VERSION ""

NS_ :

BS_:

BU_: PBWM MCPB MCPA IDCM EVCU2 ECM DMPI BPCM

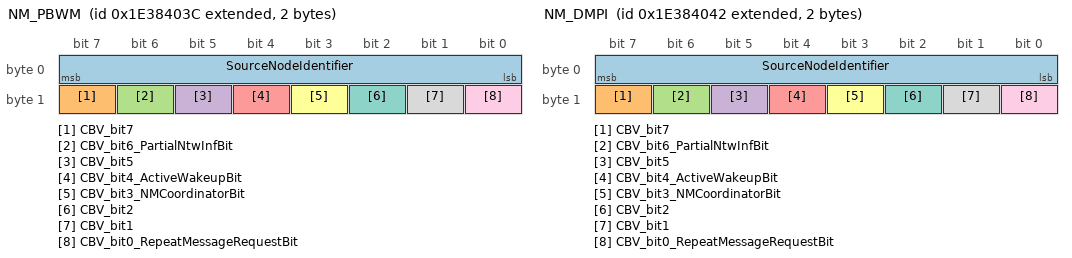
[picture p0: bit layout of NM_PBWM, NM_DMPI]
BO_ 2654486588 NM_PBWM: 2 PBWM
 SG_ SourceNodeIdentifier : 7|8@0+ (1,0) [0|255] "-"  DMPI,EVCU2,MCPB,MCPA,IDCM,BPCM,ECM
 SG_ CBV_bit7 : 15|1@0+ (1,0) [0|1] "" DMPI,EVCU2,MCPB,MCPA,IDCM,BPCM,ECM
 SG_ CBV_bit6_PartialNtwInfBit : 14|1@0+ (1,0) [0|1] "" DMPI,EVCU2,MCPB,MCPA,IDCM,BPCM,ECM
 SG_ CBV_bit5 : 13|1@0+ (1,0) [0|1] "" DMPI,EVCU2,MCPB,MCPA,IDCM,BPCM,ECM
 SG_ CBV_bit4_ActiveWakeupBit : 12|1@0+ (1,0) [0|1] "" DMPI,EVCU2,MCPB,MCPA,IDCM,BPCM,ECM
 SG_ CBV_bit3_NMCoordinatorBit : 11|1@0+ (1,0) [0|1] "" DMPI,EVCU2,MCPB,MCPA,IDCM,BPCM,ECM
 SG_ CBV_bit2 : 10|1@0+ (1,0) [0|1] "" DMPI,EVCU2,MCPB,MCPA,IDCM,BPCM,ECM
 SG_ CBV_bit1 : 9|1@0+ (1,0) [0|1] "" DMPI,EVCU2,MCPB,MCPA,IDCM,BPCM,ECM
 SG_ CBV_bit0_RepeatMessageRequestBit : 8|1@0+ (1,0) [0|1] "" DMPI,EVCU2,MCPB,MCPA,IDCM,BPCM,ECM

BO_ 2654486594 NM_DMPI: 2 DMPI
 SG_ SourceNodeIdentifier : 7|8@0+ (1,0) [0|255] "-"  PBWM,EVCU2,MCPB,MCPA,IDCM,BPCM,ECM
 SG_ CBV_bit7 : 15|1@0+ (1,0) [0|1] "" PBWM,EVCU2,MCPB,MCPA,IDCM,BPCM,ECM
 SG_ CBV_bit6_PartialNtwInfBit : 14|1@0+ (1,0) [0|1] "" PBWM,EVCU2,MCPB,MCPA,IDCM,BPCM,ECM
 SG_ CBV_bit5 : 13|1@0+ (1,0) [0|1] "" PBWM,EVCU2,MCPB,MCPA,IDCM,BPCM,ECM
 SG_ CBV_bit4_ActiveWakeupBit : 12|1@0+ (1,0) [0|1] "" PBWM,EVCU2,MCPB,MCPA,IDCM,BPCM,ECM
 SG_ CBV_bit3_NMCoordinatorBit : 11|1@0+ (1,0) [0|1] "" PBWM,EVCU2,MCPB,MCPA,IDCM,BPCM,ECM
 SG_ CBV_bit2 : 10|1@0+ (1,0) [0|1] "" PBWM,EVCU2,MCPB,MCPA,IDCM,BPCM,ECM
 SG_ CBV_bit1 : 9|1@0+ (1,0) [0|1] "" PBWM,EVCU2,MCPB,MCPA,IDCM,BPCM,ECM
 SG_ CBV_bit0_RepeatMessageRequestBit : 8|1@0+ (1,0) [0|1] "" PBWM,EVCU2,MCPB,MCPA,IDCM,BPCM,ECM

BO_ 214 INVTARGET1_2: 64 EVCU2
 SG_ UDCMin_Unlim_MCPB_2 : 129|16@0+ (0.01,0) [0|655.35] "V"  DMPI
 SG_ UDCMin_Unlim_MCPA_2 : 81|16@0+ (0.01,0) [0|655.35] "V"  DMPI
 SG_ UDCMax_Unlim_MCPB_2 : 113|16@0+ (0.01,0) [0|655.35] "V"  DMPI
 SG_ UDCMax_Unlim_MCPA_2 : 65|16@0+ (0.01,0) [0|655.35] "V"  DMPI
 SG_ TqGrdtLim_MCPB_2 : 144|16@0+ (0.1,0) [0|6553.5] "Nm/s"  DMPI
 SG_ TqGrdtLim_MCPA_2 : 97|16@0+ (0.1,0) [0|6553.5] "Nm/s"  DMPI
 SG_ TorqueCommand_MCPB_2 : 201|13@0+ (0.125,-512) [-512|511.875] "Nm"  DMPI
 SG_ TorqueCommand_MCPA_2 : 7|13@0+ (0.125,-512) [-512|511.875] "Nm"  DMPI
 SG_ TargetMotorRPM_MCPB_2 : 216|16@0+ (0.5,-16384) [-16384|16383.5] "rpm"  DMPI
 SG_ TargetMotorRPM_MCPA_2 : 22|16@0+ (0.5,-16384) [-16384|16383.5] "rpm"  DMPI
 SG_ SpdGrdtLim_MCPB_2 : 273|11@0+ (20,0) [0|40940] "rpm/s"  DMPI
 SG_ SpdGrdtLim_MCPA_2 : 160|11@0+ (20,0) [0|40940] "rpm/s"  DMPI
 SG_ Mtr_6SO_Request_MCPB_2 : 145|1@0+ (1,0) [0|1] "" DMPI
 SG_ Mtr_6SO_Request_MCPA_2 : 38|1@0+ (1,0) [0|1] "" DMPI
 SG_ ModeCommand_MCPB_2 : 220|4@0+ (1,0) [0|15] "" DMPI
 SG_ ModeCommand_MCPA_2 : 10|4@0+ (1,0) [0|15] "" DMPI
 SG_ MinTorque_Limit_MCPB_2 : 296|14@0+ (0.1,-1638.2) [-1638.2|0.1] "Nm"  DMPI
 SG_ MinTorque_Limit_MCPA_2 : 199|14@0+ (0.1,-1638.2) [-1638.2|0.1] "Nm"  DMPI
 SG_ MessageCounter_INVTARGET1_2 : 435|4@0+ (1,0) [0|15] "" DMPI
 SG_ MaxTorque_Limit_MCPB_2 : 294|14@0+ (0.1,0) [0|1638.3] "Nm"  DMPI
 SG_ MaxTorque_Limit_MCPA_2 : 181|14@0+ (0.1,0) [0|1638.3] "Nm"  DMPI
 SG_ MAC_INVTARGET1_2 : 471|48@0+ (1,0) [0|0] "" DMPI
 SG_ LgsDiagCldStrtCndMet_MCPB_2 : 267|1@0+ (1,0) [0|1] "" DMPI
 SG_ LgsDiagCldStrtCndFltPr_MCPB_2 : 268|1@0+ (1,0) [0|1] "" DMPI
 SG_ HVBatVlt_V_2 : 266|1@0+ (1,0) [0|1] "" DMPI
 SG_ EVCU_END_Request_Flag_2 : 256|1@0+ (1,0) [0|1] "" DMPI
 SG_ CRC_INVTARGET1_2 : 447|8@0+ (1,0) [0|255] "" DMPI
 SG_ Cntr_INVTARGET1_2 : 455|16@0+ (1,0) [0|65535] "" DMPI
 SG_ AEMD_MinOffset_MCPB_2 : 252|12@0+ (0.125,-511.875) [-511.875|0] "Nm"  DMPI
 SG_ AEMD_MinOffset_MCPA_2 : 41|12@0+ (0.125,-511.875) [-511.875|0] "Nm"  DMPI
 SG_ AEMD_MaxOffset_MCPB_2 : 232|12@0+ (0.125,0) [0|511.875] "Nm"  DMPI
 SG_ AEMD_Cutoff_FreqLow_MCPB_2 : 399|8@0+ (0.1,4.5) [4.5|30] "Hz"  DMPI
 SG_ AEMD_Cutoff_FreqLow_MCPA_2 : 391|8@0+ (0.1,4.5) [4.5|30] "Hz"  DMPI
 SG_ AEMD_Cutoff_FreqHigh_MCPB_2 : 383|8@0+ (0.1,0) [0|25.5] "Hz"  DMPI
 SG_ AEMD_Cutoff_FreqHigh_MCPA_2 : 375|8@0+ (0.1,0) [0|25.5] "Hz"  DMPI
 SG_ AEMD_Sclr_Gn_MCPB_2 : 354|11@0+ (0.01,0) [0|20.47] "rad/s/Nm"  DMPI
 SG_ AEMD_Sclr_Gn_MCPA_2 : 349|11@0+ (0.01,0) [0|20.47] "rad/s/Nm"  DMPI
 SG_ AEMD_Torque_BoostVolt_Margin : 37|12@0+ (0.125,0) [0|511.875] "Nm"  DMPI
 SG_ Boost_Torque_Margin_MCPB : 343|10@0+ (0.5,-256) [-256|255.5] "Nm"  DMPI
 SG_ Boost_Torque_Margin_MCPA : 321|10@0+ (0.5,-256) [-256|255.5] "Nm"  DMPI

BO_ 1065 MCPB_OBD_DTC: 32 MCPB
 SG_ MessageCounter_MCPB_OBD_DTC : 179|4@0+ (1,0) [0|15] ""  EVCU2
 SG_ MCPB_DTC_Stat2 : 26|3@0+ (1,0) [0|7] "" EVCU2
 SG_ MCPB_DTC_Stat1 : 18|3@0+ (1,0) [0|7] "" EVCU2
 SG_ MCPB_DTC_Idx2 : 31|5@0+ (1,0) [0|31] "" EVCU2
 SG_ MCPB_DTC_Idx1 : 23|5@0+ (1,0) [0|31] "" EVCU2
 SG_ MCPB_CalChar : 15|8@0+ (1,0) [0|255] "" EVCU2
 SG_ MCPB_Cal_ID_Idx : 7|6@0+ (1,0) [0|63] "" EVCU2
 SG_ CRC_MCPB_OBD_DTC : 191|8@0+ (1,0) [0|255] ""  EVCU2

BO_ 1057 MCPA_OBD_DTC: 32 MCPA
 SG_ MessageCounter_MCPA_OBD_DTC : 179|4@0+ (1,0) [0|15] ""  EVCU2
 SG_ MCPA_DTC_Stat2 : 26|3@0+ (1,0) [0|7] "" EVCU2
 SG_ MCPA_DTC_Stat1 : 18|3@0+ (1,0) [0|7] "" EVCU2
 SG_ MCPA_DTC_Idx2 : 31|5@0+ (1,0) [0|31] "" EVCU2
 SG_ MCPA_DTC_Idx1 : 23|5@0+ (1,0) [0|31] "" EVCU2
 SG_ MCPA_CalChar : 15|8@0+ (1,0) [0|255] "" EVCU2
 SG_ MCPA_Cal_ID_Idx : 7|6@0+ (1,0) [0|63] "" EVCU2
 SG_ CRC_MCPA_OBD_DTC : 191|8@0+ (1,0) [0|255] ""  EVCU2

BO_ 504 MCPB_STATUS: 32 MCPB
 SG_ MCPB_DerateReason_P : 7|4@0+ (1,0) [0|15] "-"  EVCU2
 SG_ MCPB_DC_Voltage_P : 1|10@0+ (1,0) [0|1022] "V"  EVCU2
 SG_ MCPB_DC_Volt_V_P : 3|1@0+ (1,0) [0|1] "" EVCU2
 SG_ MCPB_DC_Current_V_P : 2|1@0+ (1,0) [0|1] "" EVCU2
 SG_ MCPB_DC_Current_P : 38|15@0+ (0.1,-1638.4) [-1638.4|1638.3] "A"  EVCU2,BPCM
 SG_ MCPB_CoolantTemp_P : 18|11@0+ (0.1,-40) [-40|164.7] "°C"  EVCU2
 SG_ MC_MCPB_STATUS : 179|4@0+ (1,0) [0|15] "-"  EVCU2
 SG_ CRC_MCPB_STATUS : 191|8@0+ (1,0) [0|255] "-"  EVCU2
 SG_ MCPB_Inverter_Temp_P : 71|8@0+ (1,-40) [-40|215] "°C"  EVCU2
 SG_ MCPB_PIM_DC_Side_Busbar_Temp_P : 79|8@0+ (1,-40) [-40|215] "°C"  EVCU2
 SG_ MCPB_Rotor_Temperature_P : 55|8@0+ (1,-40) [-40|215] "ºC"  EVCU2
 SG_ MCPB_Service_Lamp_Request_P : 19|1@0+ (1,0) [0|1] "" EVCU2
 SG_ CLrDiagInfo_MCPB_P : 39|1@0+ (1,0) [0|1] "" EVCU2
 SG_ MCPB_Control_Board_Temperature_P : 63|8@0+ (1,-40) [-40|215] "" EVCU2

BO_ 503 MCPA_STATUS: 32 MCPA
 SG_ MCPA_DerateReason_P : 7|4@0+ (1,0) [0|15] "" EVCU2
 SG_ MCPA_DC_Voltage_P : 1|10@0+ (1,0) [0|1023] "V"  EVCU2
 SG_ MCPA_DC_Volt_V_P : 3|1@0+ (1,0) [0|1] "" EVCU2
 SG_ MCPA_DC_Current_V_P : 2|1@0+ (1,0) [0|1] "" EVCU2
 SG_ MCPA_DC_Current_P : 38|15@0+ (0.1,-1638.4) [-1638.4|1638.3] "A"  EVCU2,BPCM
 SG_ MCPA_CoolantTemp_P : 18|11@0+ (0.1,-40) [-40|164.7] "C"  EVCU2
 SG_ MC_MCPA_STATUS : 179|4@0+ (1,0) [0|15] "-"  EVCU2
 SG_ CRC_MCPA_STATUS : 191|8@0+ (1,0) [0|255] "-"  EVCU2
 SG_ MCPA_Inverter_Temp_P : 71|8@0+ (1,-40) [-40|215] "ºC"  EVCU2
 SG_ MCPA_PIM_DC_Side_Busbar_Temp_P : 79|8@0+ (1,-40) [-40|215] "ºC"  EVCU2
 SG_ MCPA_Rotor_Temperature_P : 55|8@0+ (1,-40) [-40|215] "ºC"  EVCU2
 SG_ MCPA_Service_Lamp_Request_P : 19|1@0+ (1,0) [0|1] "" EVCU2
 SG_ CLrDiagInfo_MCPA_P : 39|1@0+ (1,0) [0|1] "" EVCU2
 SG_ MCPA_Control_Board_Temperature_P : 63|8@0+ (1,-40) [-40|215] "ºC"  EVCU2

BO_ 297 INVTARGET_PROPULSION2: 48 EVCU2
 SG_ UDCMin_Unlim_MCPB_P : 111|16@0+ (0.01,0) [0|655.35] "V"  MCPB
 SG_ UDCMin_Unlim_MCPA_P : 23|16@0+ (0.01,0) [0|655.35] "V"  MCPA
 SG_ UDCMax_Unlim_MCPB_P : 143|16@0+ (0.01,0) [0|655.35] "V"  MCPB
 SG_ UDCMax_Unlim_MCPA_P : 39|16@0+ (0.01,0) [0|655.35] "V"  MCPA
 SG_ TqGrdtLim_MCPB_P : 79|16@0+ (0.1,0) [0|6553.5] "Nm/s"  MCPB
 SG_ TqGrdtLim_MCPA_P : 7|16@0+ (0.1,0) [0|6553.5] "Nm/s"  MCPA
 SG_ SpdGrdtLim_MCPB_P : 277|11@0+ (20,0) [0|40940] "rpm/s"  MCPB
 SG_ SpdGrdtLim_MCPA_P : 282|11@0+ (20,0) [0|40940] "rpm/s"  MCPA
 SG_ Pwr_Electr_Loop_FlwRate_MCPB_P : 63|8@0+ (0.1,0) [0|25.5] "LPM"  MCPB
 SG_ Pwr_Electr_Loop_FlwRate_MCPA_P : 55|8@0+ (0.1,0) [0|25.5] "LPM"  MCPA
 SG_ MC_INVTARGET_PROPULSION2 : 307|4@0+ (1,0) [0|15] "-"  MCPB,MCPA
 SG_ EVCU_MotorB_Speed : 191|16@0+ (1,-32768) [-32768|32767] "rpm"  MCPB
 SG_ EVCU_MotorA_Speed : 175|16@0+ (1,-32768) [-32768|32767] "rpm"  MCPA
 SG_ CRC_INVTARGET_PROPULSION2 : 319|8@0+ (1,0) [0|255] "-"  MCPB,MCPA

BO_ 296 INVTARGET_PROPULSION1: 48 EVCU2
 SG_ VehicleSpeedVSOSig_P : 55|13@0+ (0.0625,0) [0|511.875] "Km/h"  MCPB,MCPA
 SG_ TorqueCommand_MCPB_P : 157|14@0+ (0.125,-1023) [-1023|1024.875] "Nm"  MCPB
 SG_ TorqueCommand_MCPA_P : 139|14@0+ (0.125,-1023) [-1023|1024.875] "Nm"  MCPA
 SG_ TargetMotorRPM_MCPB_P : 23|16@0+ (0.5,-16384) [-16384|16383.5] "rpm"  MCPB
 SG_ TargetMotorRPM_MCPA_P : 7|16@0+ (0.5,-16384) [-16384|16383.5] "rpm"  MCPA
 SG_ ShiftLeverPosition_P : 273|4@0+ (1,0) [0|15] "" MCPB
 SG_ ParkCmd_PT_P : 259|2@0+ (1,0) [0|3] "" MCPB
 SG_ Mtr_6SO_Request_MCPB_P : 248|1@0+ (1,0) [0|1] "" MCPB
 SG_ Mtr_6SO_Request_MCPA_P : 249|1@0+ (1,0) [0|1] "" MCPA
 SG_ ModeCommand_MCPB_P : 227|4@0+ (1,0) [0|15] "" MCPB
 SG_ ModeCommand_MCPA_P : 231|4@0+ (1,0) [0|15] "" MCPA
 SG_ MC_INVTARGET_PROPULSION1 : 307|4@0+ (1,0) [0|15] "" MCPB,MCPA
 SG_ CRC_INVTARGET_PROPULSION1 : 319|8@0+ (1,0) [0|255] "-"  MCPB,MCPA
 SG_ CmdIgnSts_P : 58|3@0+ (1,0) [0|7] "" MCPB,MCPA
 SG_ BPCM_HV_TractionBusVoltage_P : 271|11@0+ (1,0) [0|2047] "V"  MCPB,MCPA
 SG_ BPCM_HV_Trac_Main_Contac_Sts_P : 276|3@0+ (1,0) [0|7] "" MCPB,MCPA
 SG_ AEMD_MinOffset_MCPB_P : 195|14@0+ (0.125,-1023) [-1023|1024.875] "Nm"  MCPB
 SG_ AEMD_MinOffset_MCPA_P : 119|14@0+ (0.125,-1023) [-1023|1024.875] "Nm"  MCPA
 SG_ AEMD_MaxOffset_MCPB_P : 213|14@0+ (0.125,-1023) [-1023|1024.875] "Nm"  MCPB
 SG_ AEMD_MaxOffset_MCPA_P : 121|14@0+ (0.125,-1023) [-1023|1024.875] "Nm"  MCPA
 SG_ AEMD_Cutoff_FreqLow_MCPB_P : 87|8@0+ (0.1,4.5) [4.5|30] "Hz"  MCPB
 SG_ AEMD_Cutoff_FreqLow_MCPA_P : 71|8@0+ (0.1,4.5) [4.5|30] "Hz"  MCPA
 SG_ AEMD_Cutoff_FreqHigh_MCPB_P : 95|8@0+ (0.1,0) [0|25.5] "Hz"  MCPB
 SG_ AEMD_Cutoff_FreqHigh_MCPA_P : 79|8@0+ (0.1,0) [0|25.5] "Hz"  MCPA
 SG_ AEMD_Sclr_Gn_MCPB_P : 242|9@0+ (0.02,0) [0|10.22] "rad/s/Nm"  MCPB
 SG_ AEMD_Sclr_Gn_MCPA_P : 235|9@0+ (0.02,0) [0|10.22] "rad/s/Nm"  MCPA

BO_ 294 MCPB_PROPULSION: 64 MCPB
 SG_ PlockFailSts_P : 179|3@0+ (1,0) [0|6] "" EVCU2
 SG_ Plock_PosSensor_P : 196|3@0+ (1,0) [0|6] "" EVCU2
 SG_ Plock_MotorPosSts_P : 188|3@0+ (1,0) [0|6] "" EVCU2
 SG_ Plock_fdbk_sts_P : 191|3@0+ (1,0) [0|7] "" EVCU2
 SG_ MPR_PosSensor_P : 199|3@0+ (1,0) [0|6] "" EVCU2
 SG_ MCPB_Torque_Achieved_V_P : 54|1@0+ (1,0) [0|1] "" EVCU2
 SG_ MCPB_Torque_Achieved_P : 21|14@0+ (0.125,-1023) [-1023|1024.875] "Nm"  EVCU2
 SG_ MCPB_TorqAchieved_AEMD_V_P : 71|1@0+ (1,0) [0|1] "" EVCU2
 SG_ MCPB_TorqAchieved_AEMD_P : 85|14@0+ (0.125,-1023) [-1023|1024.875] "Nm"  EVCU2
 SG_ MCPB_SPT_Stat_P : 39|2@0+ (1,0) [0|3] "" EVCU2
 SG_ MCPB_Spd_Lim_P : 135|16@0+ (1,-32767) [-32767|32678] "rpm"  EVCU2
 SG_ MCPB_RPM_V_P : 70|1@0+ (1,0) [0|1] "" EVCU2
 SG_ MCPB_RPM_P : 7|16@0+ (1,-32768) [-32768|32767] "rpm"  EVCU2
 SG_ MCPB_MtrMinCpbltyTrq_P : 117|14@0+ (0.125,-1023) [-1023|1024.875] "Nm"  EVCU2
 SG_ MCPB_MtrMaxCpbltyTrq_P : 101|14@0+ (0.125,-1023) [-1023|1024.875] "Nm"  EVCU2
 SG_ MCPB_MtrIndex_P : 44|5@0+ (1,0) [0|31] "" EVCU2
 SG_ MCPB_MinTorq_P : 69|14@0+ (0.125,-1023) [-1023|1024.875] "Nm"  EVCU2
 SG_ MCPB_MaxTorq_P : 53|14@0+ (0.125,-1023) [-1023|1024.875] "Nm"  EVCU2
 SG_ MCPB_Invrtr_State_P : 183|4@0+ (1,0) [0|15] "" EVCU2
 SG_ MCPB_InterlockSts_P : 103|2@0+ (1,0) [0|3] "" EVCU2
 SG_ MCPB_HV_CnctrOpn_Req_P : 119|1@0+ (1,0) [0|1] "" EVCU2
 SG_ MCPB_Dschrge_Status_P : 87|2@0+ (1,0) [0|3] "" EVCU2
 SG_ MCPB_DeratingFactor_P : 37|6@0+ (0.02,0) [0|1.26] "" EVCU2
 SG_ MCPB_CpbltySpdDivVolt_P : 167|16@0+ (1,0) [0|65535] "V"  EVCU2
 SG_ MCPB_AccelRawV_P : 55|1@0+ (1,0) [0|1] "" EVCU2
 SG_ MCPB_6SO_Status_P : 23|2@0+ (1,0) [0|3] "" EVCU2
 SG_ MCPB_3PS_Pos_P : 118|1@0+ (1,0) [0|1] "" EVCU2
 SG_ MCPB_AccelRaw_P : 151|16@0+ (1,-32768) [-32768|32767] "RPM/s"  EVCU2
 SG_ MC_MCPB_PROPULSION : 435|4@0+ (1,0) [0|15] "-"  EVCU2
 SG_ CRC_MCPB_PROPULSION : 447|8@0+ (1,0) [0|255] "-"  EVCU2
 SG_ MCPB_AC_Isolation_Status_P : 193|2@0+ (1,0) [0|3] "" EVCU2
 SG_ MCPB_Temp_P : 207|8@0+ (1,-40) [-40|215] "ºC"  EVCU2

BO_ 293 MCPA_PROPULSION: 64 MCPA
 SG_ MCPA_Torque_Achieved_V_P : 54|1@0+ (1,0) [0|1] "" EVCU2
 SG_ MCPA_Torque_Achieved_P : 21|14@0+ (0.125,-1023) [-1023|1024.875] "Nm"  EVCU2
 SG_ MCPA_TorqAchieved_AEMD_V_P : 71|1@0+ (1,0) [0|1] "" EVCU2
 SG_ MCPA_TorqAchieved_AEMD_P : 85|14@0+ (0.125,-1023) [-1023|1024.875] "Nm"  EVCU2
 SG_ MCPA_SPT_Stat_P : 39|2@0+ (1,0) [0|3] "" EVCU2
 SG_ MCPA_Spd_Lim_P : 135|16@0+ (1,-32767) [-32767|32768] "rpm"  EVCU2
 SG_ MCPA_RPM_V_P : 70|1@0+ (1,0) [0|1] "" EVCU2
 SG_ MCPA_RPM_P : 7|16@0+ (1,-32768) [-32768|32767] "rpm"  EVCU2
 SG_ MCPA_MtrMinCpbltyTrq_P : 117|14@0+ (0.125,-1023) [-1023|1024.875] "Nm"  EVCU2
 SG_ MCPA_MtrMaxCpbltyTrq_P : 101|14@0+ (0.125,-1023) [-1023|1024.875] "Nm"  EVCU2
 SG_ MCPA_MtrIndex_P : 44|5@0+ (1,0) [0|31] "" EVCU2
 SG_ MCPA_MinTorq_P : 69|14@0+ (0.125,-1023) [-1023|1024.875] "Nm"  EVCU2
 SG_ MCPA_MaxTorq_P : 53|14@0+ (0.125,-1023) [-1023|1024.875] "Nm"  EVCU2
 SG_ MCPA_Invrtr_State_P : 183|4@0+ (1,0) [0|15] "" EVCU2
 SG_ MCPA_InterlockSts_P : 103|2@0+ (1,0) [0|3] "" EVCU2
 SG_ MCPA_HV_CnctrOpn_Req_P : 119|1@0+ (1,0) [0|1] "" EVCU2
 SG_ MCPA_Dschrge_Status_P : 87|2@0+ (1,0) [0|3] "" EVCU2
 SG_ MCPA_DeratingFactor_P : 37|6@0+ (0.02,0) [0|1.26] "" EVCU2
 SG_ MCPA_CpbltySpdDivVolt_P : 167|16@0+ (1,0) [0|65535] "rpm"  EVCU2
 SG_ MCPA_AccelRawV_P : 55|1@0+ (1,0) [0|1] "" EVCU2
 SG_ MCPA_6SO_Status_P : 23|2@0+ (1,0) [0|3] "" EVCU2
 SG_ MCPA_3PS_Pos_P : 118|1@0+ (1,0) [0|1] "" EVCU2
 SG_ MCPA_AccelRaw_P : 151|16@0+ (1,-32768) [-32768|32767] "RPM/s"  EVCU2
 SG_ MC_MCPA_PROPULSION : 435|4@0+ (1,0) [0|15] "-"  EVCU2
 SG_ CRC_MCPA_PROPULSION : 447|8@0+ (1,0) [0|255] "-"  EVCU2
 SG_ MCPA_Temp_P : 207|8@0+ (1,-40) [-40|215] "°C"  EVCU2
 SG_ MCPA_AC_Isolation_Status_P : 199|2@0+ (1,0) [0|3] "" EVCU2

BO_ 220 PT_SYSTEM_FD_OBD: 48 EVCU2
 SG_ VIN_MSG_OBD : 25|2@0+ (1,0) [0|3] "" DMPI,PBWM,BPCM
 SG_ VIN_DATA_OBD : 39|56@0+ (1,0) [0|0] "" DMPI,PBWM,BPCM
 SG_ VehicleSpeedVSOSig_OBD : 119|13@0+ (0.0625,0) [0|511.9375] "Km/h"  DMPI,MCPB,MCPA,BPCM
 SG_ TotalOdometer_OBD : 95|20@0+ (1,0) [0|1048575] "km"  DMPI,PBWM,BPCM
 SG_ OperationalModeSts_OBD : 107|4@0+ (1,0) [0|15] "" DMPI,PBWM,MCPB,MCPA,BPCM,ECM
 SG_ EngineSpeedFailSts_W_OBD : 149|1@0+ (1,0) [0|1] "" DMPI
 SG_ EngineSpeed_W_OBD : 23|14@0+ (1,0) [0|16383] "1/min"  DMPI,BPCM
 SG_ CmdIgnSts_OBD : 122|3@0+ (1,0) [0|7] "" DMPI,PBWM,MCPB,MCPA,BPCM,ECM
 SG_ MessageCounter_PT_SYSTEM_FD_OBD : 307|4@0+ (1,0) [0|15] "-"  DMPI,BPCM,ECM
 SG_ CRC_PT_SYSTEM_FD_OBD : 319|8@0+ (1,0) [0|255] "-"  DMPI,BPCM,ECM

BO_ 200 PT_SYSTEM_FD_4: 64 EVCU2
 SG_ TotalAxle_Rq_BSM_PT : 55|16@0+ (2,-65534) [-65534|65536] "Nm"  DMPI
 SG_ TotalAxle_Min_Rq_BSM_PT : 113|1@0+ (1,0) [0|1] "" DMPI
 SG_ TotalAxle_Max_Rq_BSM_PT : 114|1@0+ (1,0) [0|1] "" DMPI
 SG_ Total_AxleTorque_Static_PT : 71|16@0+ (2,-65534) [-65534|65536] "Nm"  DMPI
 SG_ RHFWheelSpeed_PT : 111|13@0+ (0.0625,0) [0|511.9375] "Km/h"  DMPI
 SG_ RHF_WheelSensorFailSts_PT : 9|1@0+ (1,0) [0|1] "" DMPI
 SG_ LHFWheelSpeed_PT : 7|13@0+ (0.0625,0) [0|511.9375] "Km/h"  DMPI
 SG_ LHF_WheelSensorFailSts_PT : 10|1@0+ (1,0) [0|1] "" DMPI
 SG_ Ft_RrCouplingTrq_Desired_PT : 103|8@0+ (12,0) [0|3060] "Nm"  DMPI
 SG_ Ft_RrCouplingTrq_Actual_PT : 87|8@0+ (12,0) [0|3060] "Nm"  DMPI
 SG_ ESCActive_PT : 8|1@0+ (1,0) [0|1] "" DMPI
 SG_ Axle_TorqueStatic_D_TTC_PT : 23|16@0+ (2,-65534) [-65534|65536] "Nm"  DMPI
 SG_ Axle_TorqueStatic_D_TTC_ESC_PT : 39|16@0+ (2,-65534) [-65534|65536] "Nm"  DMPI
 SG_ AWDSysStat_PT : 123|3@0+ (1,0) [0|7] "-"  DMPI
 SG_ AtmosphericPressureFailSts_PT : 112|1@0+ (1,0) [0|1] "" DMPI
 SG_ AtmosphericPressure_W_PT : 95|8@0+ (3.6,300) [300|1218] "mbar"  DMPI
 SG_ MessageCounter_PT_SYSTEM_FD_4 : 435|4@0+ (1,0) [0|15] "-"  DMPI
 SG_ CRC_PT_SYSTEM_FD_4 : 447|8@0+ (1,0) [0|255] "-"  DMPI

CM_ SG_ 2654486588 SourceNodeIdentifier "Source Node Identifier";
CM_ SG_ 2654486588 CBV_bit6_PartialNtwInfBit "Partial Network Information Bit (PNI)";
CM_ SG_ 2654486588 CBV_bit4_ActiveWakeupBit "Active Wakeup Bit";
CM_ SG_ 2654486588 CBV_bit3_NMCoordinatorBit "NM Coordinator Sleep Bit";
CM_ SG_ 2654486588 CBV_bit0_RepeatMessageRequestBit "Repeat Message Request Bit";
CM_ SG_ 2654486594 SourceNodeIdentifier "Source Node Identifier";
CM_ SG_ 2654486594 CBV_bit6_PartialNtwInfBit "Partial Network Information Bit (PNI)";
CM_ SG_ 2654486594 CBV_bit4_ActiveWakeupBit "Active Wakeup Bit";
CM_ SG_ 2654486594 CBV_bit3_NMCoordinatorBit "NM Coordinator Sleep Bit";
CM_ SG_ 2654486594 CBV_bit0_RepeatMessageRequestBit "Repeat Message Request Bit";
CM_ SG_ 214 UDCMin_Unlim_MCPB_2 "Minimum DC voltage limit before linear generator derating Consider Max or Min torque. Default 36V";
CM_ SG_ 214 UDCMin_Unlim_MCPA_2 "Minimum DC voltage limit before linear generator derating Consider Max or Min torque. Default 36V";
CM_ SG_ 214 UDCMax_Unlim_MCPB_2 "Maximum DC voltage limit before linear generator derating Consider Max or Min torque. Default 52V";
CM_ SG_ 214 UDCMax_Unlim_MCPA_2 "Maximum DC voltage limit before linear generator derating Consider Max or Min torque. Default 52V";
CM_ SG_ 214 TqGrdtLim_MCPB_2 "Positive or Negative Torque Gradient applied for Torque Control Mode and Speed Control Mode. Default 1000Nm/s";
CM_ SG_ 214 TqGrdtLim_MCPA_2 "Positive or Negative Torque Gradient applied for Torque Control Mode and Speed Control Mode. Default 1000Nm/s";
CM_ SG_ 214 TorqueCommand_MCPB_2 "Torque command for MCPB";
CM_ SG_ 214 AEMD_Cutoff_FreqHigh_MCPA_2 "AEMD cut-off Frequency High for MCPA";
CM_ SG_ 214 AEMD_Cutoff_FreqHigh_MCPB_2 "AEMD cut-off Frequency High for MCPB";
CM_ SG_ 214 AEMD_Cutoff_FreqLow_MCPA_2 "AEMD cut-off Frequency Low for MCPA";
CM_ SG_ 214 AEMD_Cutoff_FreqLow_MCPB_2 "AEMD cut-off Frequency Low for MCPB";
CM_ SG_ 214 AEMD_MaxOffset_MCPB_2 "MCPB AEMD Max Offset";
CM_ SG_ 214 AEMD_MinOffset_MCPA_2 "MCPA AEMD Min Offset";
CM_ SG_ 214 AEMD_MinOffset_MCPB_2 "MCPB AEMD Min Offset";
CM_ SG_ 214 AEMD_Sclr_Gn_MCPA_2 "MCPA AEMD Scalar Gain";
CM_ SG_ 214 AEMD_Sclr_Gn_MCPB_2 "MCPB AEMD Scalar Gain";
CM_ SG_ 214 AEMD_Torque_BoostVolt_Margin "AEMD Torque for Boost Voltage Control";
CM_ SG_ 214 Boost_Torque_Margin_MCPA "Motor A Torque marging for Boost converter Voltage";
CM_ SG_ 214 Boost_Torque_Margin_MCPB "Motor B Torque marging for Boost converter Voltage";
CM_ SG_ 214 Cntr_INVTARGET1_2 "Cntr";
CM_ SG_ 214 CRC_INVTARGET1_2 "CRC according to SAE J1850 standard at each frame transmission.";
CM_ SG_ 214 EVCU_END_Request_Flag_2 "PCU END Request Flag";
CM_ SG_ 214 HVBatVlt_V_2 "High voltage battery pack voltage Validity";
CM_ SG_ 214 LgsDiagCldStrtCndFltPr_MCPB_2 "Legislated diagnostics cold start conditions fault present; true = [1]";
CM_ SG_ 214 LgsDiagCldStrtCndMet_MCPB_2 "Legislated diagnostics cold start conditions met; true = [1]";
CM_ SG_ 214 MAC_INVTARGET1_2 "MAC";
CM_ SG_ 214 MaxTorque_Limit_MCPA_2 "Maximum Limit of Electric Machine torque defined by Master Controller";
CM_ SG_ 214 MaxTorque_Limit_MCPB_2 "Maximum Limit of Electric Machine torque defined by Master Controller";
CM_ SG_ 214 MessageCounter_INVTARGET1_2 "This signal is a counter used for safety checks strategies. This counter is incremented of 1 (one) unit at each frame transmission.";
CM_ SG_ 214 MinTorque_Limit_MCPA_2 "Minimum Limit of Electric Machine torque defined by Master Controller";
CM_ SG_ 214 MinTorque_Limit_MCPB_2 "Minimum Limit of Electric Machine torque defined by Master Controller";
CM_ SG_ 214 ModeCommand_MCPA_2 "Mode command for MCPA";
CM_ SG_ 214 ModeCommand_MCPB_2 "Mode command for MCPB";
CM_ SG_ 214 Mtr_6SO_Request_MCPA_2 "Six Switch Open Request  for MCPA (1=RequestActive; 0=RequestNotActive)";
CM_ SG_ 214 Mtr_6SO_Request_MCPB_2 "Six Switch Open Request  for MCPB (1=RequestActive; 0=RequestNotActive)";
CM_ SG_ 214 SpdGrdtLim_MCPA_2 "Positive or negative (symetric) Speed Request Gradient applicable on both sign only for Speed Control Mode. Default 25,000 rpm/s";
CM_ SG_ 214 SpdGrdtLim_MCPB_2 "Positive or negative (symetric) Speed Request Gradient applicable on both sign only for Speed Control Mode. Default 25,000 rpm/s";
CM_ SG_ 214 TargetMotorRPM_MCPA_2 "Target Motor RPM for MCPA";
CM_ SG_ 214 TargetMotorRPM_MCPB_2 "Target Motor RPM for MCPB";
CM_ SG_ 214 TorqueCommand_MCPA_2 "Torque command for MCPA";
CM_ SG_ 1065 MessageCounter_MCPB_OBD_DTC "This signal is a counter used for safety checks strategies. This counter is incremented of 1 (one) unit at each frame transmission.";
CM_ SG_ 1065 MCPB_DTC_Stat2 "MCPB diagnostic trouble code status 1";
CM_ SG_ 1065 MCPB_DTC_Stat1 "MCPB diagnostic trouble code status 1";
CM_ SG_ 1065 MCPB_DTC_Idx2 "MCPB diagnostic trouble code index 2";
CM_ SG_ 1065 MCPB_DTC_Idx1 "MCPB diagnostic trouble code index 1";
CM_ SG_ 1065 MCPB_CalChar "MCPB Calibration CVN";
CM_ SG_ 1065 MCPB_Cal_ID_Idx "MCPB Calibration ID Index";
CM_ SG_ 1065 CRC_MCPB_OBD_DTC "CRC according to SAE J1850 standard at each frame transmission.";
CM_ SG_ 1057 MessageCounter_MCPA_OBD_DTC "This signal is a counter used for safety checks strategies. This counter is incremented of 1 (one) unit at each frame transmission.";
CM_ SG_ 1057 MCPA_DTC_Stat2 "MCPA diagnostic trouble code status 1";
CM_ SG_ 1057 MCPA_DTC_Stat1 "MCPA diagnostic trouble code status 1";
CM_ SG_ 1057 MCPA_DTC_Idx2 "MCPA diagnostic trouble code index 2";
CM_ SG_ 1057 MCPA_DTC_Idx1 "MCPA diagnostic trouble code index 1";
CM_ SG_ 1057 MCPA_CalChar "MCPA Calibration CVN";
CM_ SG_ 1057 MCPA_Cal_ID_Idx "MCPA Calibration ID Index";
CM_ SG_ 1057 CRC_MCPA_OBD_DTC "CRC according to SAE J1850 standard at each frame transmission.";
CM_ SG_ 504 MCPB_Service_Lamp_Request_P "The Service Light Request from the MCPB";
CM_ SG_ 504 MCPB_Rotor_Temperature_P "Rotor Temperature from Motor";
CM_ SG_ 504 MCPB_PIM_DC_Side_Busbar_Temp_P "MCPB busbar temperature in DC side";
CM_ SG_ 504 MCPB_Inverter_Temp_P "Motor Inverter Temperature";
CM_ SG_ 504 MCPB_DerateReason_P "Inverter Derating Reason.";
CM_ SG_ 504 MCPB_DC_Voltage_P "This signal indicates the Inverter Rear Right DC Voltage.";
CM_ SG_ 504 MCPB_DC_Volt_V_P "Achieved Torque value Validity, [1] = True";
CM_ SG_ 504 MCPB_DC_Current_V_P "Achieved Torque value Validity, [1] = True";
CM_ SG_ 504 MCPB_DC_Current_P "Motor B DC Current";
CM_ SG_ 504 MCPB_CoolantTemp_P "PIM Coolant Temperature";
CM_ SG_ 504 MCPB_Control_Board_Temperature_P "Motor Control Board temperature";
CM_ SG_ 504 MC_MCPB_STATUS "Message counter according to SAE J1850 standard that has to be calculated from bit 63 to bit 8 at each frame transmission.";
CM_ SG_ 504 CRC_MCPB_STATUS "CRC according to SAE J1850 standard that has to be calculated from bit 63 to bit 8 at each frame transmission.";
CM_ SG_ 504 CLrDiagInfo_MCPB_P "Legislative Diagnostic Clear information for MCPB";
CM_ SG_ 503 MCPA_Service_Lamp_Request_P "The Service Light Request from the MCPA";
CM_ SG_ 503 MCPA_Rotor_Temperature_P "Rotor Temperature from Motor";
CM_ SG_ 503 MCPA_PIM_DC_Side_Busbar_Temp_P "MCPA busbar temperature in DC side";
CM_ SG_ 503 MCPA_Inverter_Temp_P "Motor Inverter Temperature";
CM_ SG_ 503 MCPA_DerateReason_P "Inverter Derating Reason";
CM_ SG_ 503 MCPA_DC_Voltage_P "Inverter Front DC Voltage.";
CM_ SG_ 503 MCPA_DC_Volt_V_P "Motor A DC current validity, [1] = True";
CM_ SG_ 503 MCPA_DC_Current_V_P "Motor A DC current validity, [1] = True";
CM_ SG_ 503 MCPA_DC_Current_P "Motor A DC Current";
CM_ SG_ 503 MCPA_CoolantTemp_P "PIM Coolant Temperature";
CM_ SG_ 503 MCPA_Control_Board_Temperature_P "Motor Control Board temperature";
CM_ SG_ 503 MC_MCPA_STATUS "Message counter according to SAE J1850 standard that has to be calculated from bit 63 to bit 8 at each frame transmission.";
CM_ SG_ 503 CRC_MCPA_STATUS "CRC according to SAE J1850 standard that has to be calculated from bit 63 to bit 8 at each frame transmission.";
CM_ SG_ 503 CLrDiagInfo_MCPA_P "Legislative Diagnostic Clear information for MCPA";
CM_ SG_ 297 CRC_INVTARGET_PROPULSION2 "CRC according to SAE J1850 standard that has to be calculated from bit 63 to bit 8 at each frame transmission.";
CM_ SG_ 297 EVCU_MotorA_Speed "Motor A Speed Calculted by Supervisory Controller";
CM_ SG_ 297 EVCU_MotorB_Speed "Motor B Speed Calculted by Supervisory Controller";
CM_ SG_ 297 MC_INVTARGET_PROPULSION2 "Message counter according to SAE J1850 standard that has to be calculated from bit 63 to bit 8 at each frame transmission.";
CM_ SG_ 297 Pwr_Electr_Loop_FlwRate_MCPA_P "Inverter cooling liquid flow rate information";
CM_ SG_ 297 Pwr_Electr_Loop_FlwRate_MCPB_P "Inverter cooling liquid flow rate information";
CM_ SG_ 297 SpdGrdtLim_MCPA_P "Positive or negative (symetric) Speed Request Gradient applicable on both sign only for Speed Control Mode. Default 25,000 rpm/s";
CM_ SG_ 297 SpdGrdtLim_MCPB_P "Positive or negative (symetric) Speed Request Gradient applicable on both sign only for Speed Control Mode. Default 25,000 rpm/s";
CM_ SG_ 297 TqGrdtLim_MCPA_P "Positive or Negative Torque Gradient applied for Torque Control Mode and Speed Control Mode. Default 1000Nm/s";
CM_ SG_ 297 TqGrdtLim_MCPB_P "Positive or Negative Torque Gradient applied for Torque Control Mode and Speed Control Mode. Default 1000Nm/s";
CM_ SG_ 297 UDCMax_Unlim_MCPA_P "Maximum DC voltage limit before linear generator derating Consider Max or Min torque. Default 52V";
CM_ SG_ 297 UDCMax_Unlim_MCPB_P "Maximum DC voltage limit before linear generator derating Consider Max or Min torque. Default 52V";
CM_ SG_ 297 UDCMin_Unlim_MCPA_P "Minimum DC voltage limit before linear generator derating Consider Max or Min torque. Default 36V";
CM_ SG_ 297 UDCMin_Unlim_MCPB_P "Minimum DC voltage limit before linear generator derating Consider Max or Min torque. Default 36V";
CM_ SG_ 296 AEMD_Cutoff_FreqHigh_MCPA_P "AEMD cut-off Frequency High for MCPA";
CM_ SG_ 296 AEMD_Cutoff_FreqHigh_MCPB_P "AEMD cut-off Frequency High for MCPB";
CM_ SG_ 296 AEMD_Cutoff_FreqLow_MCPA_P "AEMD cut-off Frequency Low for MCPA";
CM_ SG_ 296 AEMD_Cutoff_FreqLow_MCPB_P "AEMD cut-off Frequency Low for MCPB";
CM_ SG_ 296 AEMD_MaxOffset_MCPA_P "MCPA AEMD Max Offset";
CM_ SG_ 296 AEMD_MaxOffset_MCPB_P "MCPB AEMD Max Offset";
CM_ SG_ 296 AEMD_MinOffset_MCPA_P "MCPA AEMD Min Offset";
CM_ SG_ 296 AEMD_MinOffset_MCPB_P "MCPB AEMD Min Offset";
CM_ SG_ 296 AEMD_Sclr_Gn_MCPA_P "MCPA AEMD Scalar Gain";
CM_ SG_ 296 AEMD_Sclr_Gn_MCPB_P "MCPB AEMD Scalar Gain";
CM_ SG_ 296 BPCM_HV_Trac_Main_Contac_Sts_P "Traction main contactor physical relay status";
CM_ SG_ 296 BPCM_HV_TractionBusVoltage_P "Battery link traction bus voltage.";
CM_ SG_ 296 CmdIgnSts_P "Used to give information about the key selector position";
CM_ SG_ 296 CRC_INVTARGET_PROPULSION1 "CRC according to SAE J1850 standard that has to be calculated from bit 63 to bit 8 at each frame transmission.";
CM_ SG_ 296 ModeCommand_MCPA_P "Mode command for MCPA";
CM_ SG_ 296 ModeCommand_MCPB_P "Mode command for MCPB";
CM_ SG_ 296 Mtr_6SO_Request_MCPA_P "Six Switch Open Request  for MCPA (1=RequestActive; 0=RequestNotActive)";
CM_ SG_ 296 Mtr_6SO_Request_MCPB_P "Six Switch Open Request  for MCPB (1=RequestActive; 0=RequestNotActive)";
CM_ SG_ 296 ParkCmd_PT_P "Park Command for MCP.";
CM_ SG_ 296 ShiftLeverPosition_P "Shift Lever Position";
CM_ SG_ 296 TargetMotorRPM_MCPA_P "Target Motor RPM for MCPA";
CM_ SG_ 296 TargetMotorRPM_MCPB_P "Target Motor RPM for MCPB";
CM_ SG_ 296 TorqueCommand_MCPA_P "Torque command for MCPA";
CM_ SG_ 296 TorqueCommand_MCPB_P "Torque command for MCPB";
CM_ SG_ 296 VehicleSpeedVSOSig_P "It is the average vehicle speed calculated.";
CM_ SG_ 294 PlockFailSts_P "Park Lock Fail Sts";
CM_ SG_ 294 Plock_PosSensor_P "Par lock physical position sensor feedback";
CM_ SG_ 294 MCPB_SPT_Stat_P "Inverter Isolation Status";
CM_ SG_ 294 Plock_MotorPosSts_P "Park lock motor position status";
CM_ SG_ 294 Plock_fdbk_sts_P "Park lock status";
CM_ SG_ 294 MPR_PosSensor_P "Manual Park Release sensor feedback";
CM_ SG_ 294 MCPB_Torque_Achieved_V_P "Achieved Torque value Validity, [1] = True";
CM_ SG_ 294 MCPB_Torque_Achieved_P "Motr B Torque Achieved";
CM_ SG_ 294 MCPB_TorqAchieved_AEMD_V_P "Motor Torque Achieved Validity";
CM_ SG_ 294 MCPB_TorqAchieved_AEMD_P "Motor Torque Achieved";
CM_ SG_ 294 MCPB_Temp_P "Motor Stator Temperature";
CM_ SG_ 294 MCPB_Spd_Lim_P "Limited motor speed during reduced performance from MCP B";
CM_ SG_ 294 MCPB_RPM_V_P "Motor B Speed Validity, [1] = True";
CM_ SG_ 294 MCPB_RPM_P "Motor B Speed Raw";
CM_ SG_ 294 MCPB_MtrMinCpbltyTrq_P "Motor B Min Capability Torque";
CM_ SG_ 294 MCPB_MtrMaxCpbltyTrq_P "Motor B Max Capability Torque";
CM_ SG_ 294 MCPB_MtrIndex_P "Motor B Capability Curve Array Index";
CM_ SG_ 294 MCPB_MinTorq_P "Motor B Minimum Torque";
CM_ SG_ 294 MCPB_MaxTorq_P "Motor B Maximum Torque";
CM_ SG_ 294 MCPB_Invrtr_State_P "Inverter State of Operation of Motor B";
CM_ SG_ 294 MCPB_InterlockSts_P "Rear right inverter interlock state";
CM_ SG_ 294 MCPB_HV_CnctrOpn_Req_P "HV Battery pack contactor request";
CM_ SG_ 294 MCPB_Dschrge_Status_P "The active discharge status of MCPB";
CM_ SG_ 294 MCPB_DeratingFactor_P "Motor B Derating Factor";
CM_ SG_ 294 MCPB_CpbltySpdDivVolt_P "Motor B Speed at Capability Curve";
CM_ SG_ 294 MCPB_AccelRawV_P "Motor B Acceleration Validity";
CM_ SG_ 294 MCPB_AccelRaw_P "Motor B Acceleration";
CM_ SG_ 294 MCPB_AC_Isolation_Status_P "Motor AC Isolation Status";
CM_ SG_ 294 MCPB_6SO_Status_P "Motor B 6SO Status";
CM_ SG_ 294 MCPB_3PS_Pos_P "3 phase motor short possible from MCP B; True = [1]";
CM_ SG_ 294 MC_MCPB_PROPULSION "Message counter according to SAE J1850 standard that has to be calculated from bit 63 to bit 8 at each frame transmission.";
CM_ SG_ 294 CRC_MCPB_PROPULSION "CRC according to SAE J1850 standard that has to be calculated from bit 63 to bit 8 at each frame transmission.";
CM_ SG_ 293 MCPA_Torque_Achieved_V_P "Achieved Torque value Validity, [1] = True";
CM_ SG_ 293 MCPA_Torque_Achieved_P "Motor A Torque Achieved";
CM_ SG_ 293 MCPA_TorqAchieved_AEMD_V_P "Motor Torque Achieved Validity";
CM_ SG_ 293 MCPA_TorqAchieved_AEMD_P "Motor Torque Achieved without AEMD";
CM_ SG_ 293 MCPA_Temp_P "Motor Stator Temperature";
CM_ SG_ 293 MCPA_SPT_Stat_P "Inverter Isolation Status";
CM_ SG_ 293 MCPA_Spd_Lim_P "Limited motor speed during reduced performance from MCPA";
CM_ SG_ 293 MCPA_RPM_V_P "Motor A Speed Validity, [1] = True";
CM_ SG_ 293 MCPA_RPM_P "Motor A Speed Raw";
CM_ SG_ 293 MCPA_MtrMinCpbltyTrq_P "Motor A Min Capability Torque";
CM_ SG_ 293 MCPA_MtrMaxCpbltyTrq_P "Motor A Max Capability Torque";
CM_ SG_ 293 MCPA_MtrIndex_P "Motor A Capability Curve Array Index";
CM_ SG_ 293 MCPA_MinTorq_P "Motor A Minimum Torque";
CM_ SG_ 293 MCPA_MaxTorq_P "Motor A Maximum Torque";
CM_ SG_ 293 MCPA_Invrtr_State_P "Inverter State of Operation of Motor A";
CM_ SG_ 293 MCPA_InterlockSts_P "Front inverter interlock state";
CM_ SG_ 293 MCPA_HV_CnctrOpn_Req_P "HV Battery pack contactor request";
CM_ SG_ 293 MCPA_Dschrge_Status_P "The active discharge status of MCPA";
CM_ SG_ 293 MCPA_DeratingFactor_P "Motor A Derating Factor";
CM_ SG_ 293 MCPA_CpbltySpdDivVolt_P "Motor A Speed at Capability Curve";
CM_ SG_ 293 MCPA_AccelRawV_P "Motor A Acceleration Validity";
CM_ SG_ 293 MCPA_AccelRaw_P "Motor A Acceleration";
CM_ SG_ 293 MCPA_AC_Isolation_Status_P "Motor AC Isolation Status";
CM_ SG_ 293 MCPA_6SO_Status_P "Motor A 6SO Status";
CM_ SG_ 293 MCPA_3PS_Pos_P "3 phase motor short possible from MCP B; True = [1]";
CM_ SG_ 293 MC_MCPA_PROPULSION "Message counter according to SAE J1850 standard that has to be calculated from bit 63 to bit 8 at each frame transmission.";
CM_ SG_ 293 CRC_MCPA_PROPULSION "CRC according to SAE J1850 standard that has to be calculated from bit 63 to bit 8 at each frame transmission.";
CM_ SG_ 220 TotalOdometer_OBD "Used to give information about the total odometer value in km.";
CM_ SG_ 220 OperationalModeSts_OBD "Used to give information about the Operational Mode Status";
CM_ SG_ 220 MessageCounter_PT_SYSTEM_FD_OBD "This signal is a counter used for safety checks strategies. This counter is incremented of 1 (one) unit at each frame transmission.";
CM_ SG_ 220 EngineSpeedFailSts_W_OBD "Used to indicate if a Fail is present for the engine speed";
CM_ SG_ 220 EngineSpeed_W_OBD "It gives information on C-CAN network about engine speed";
CM_ SG_ 220 CmdIgnSts_OBD "Used to give information about the key selector position";
CM_ SG_ 220 VIN_MSG_OBD "VIN Message Information";
CM_ SG_ 220 VIN_DATA_OBD "VIN Digits (8 bit ascii encoded)";
CM_ SG_ 220 VehicleSpeedVSOSig_OBD "It is the average vehicle speed calculated.";
CM_ SG_ 220 CRC_PT_SYSTEM_FD_OBD "CRC according to SAE J1850 standard at each frame transmission.";
CM_ SG_ 200 TotalAxle_Rq_BSM_PT "Combined axle traction torque request";
CM_ SG_ 200 TotalAxle_Min_Rq_BSM_PT "Combined axle traction torque min limit flag. Active = [1]";
CM_ SG_ 200 TotalAxle_Max_Rq_BSM_PT "Combined axle traction torque max limit flag. Active = [1]";
CM_ SG_ 200 Total_AxleTorque_Static_PT "Static Axle Torque (effective total Axle torque)";
CM_ SG_ 200 RHFWheelSpeed_PT "This is the value of the right front wheel speed";
CM_ SG_ 200 RHF_WheelSensorFailSts_PT "This signal indicates the fail status of RHF sensor";
CM_ SG_ 200 MessageCounter_PT_SYSTEM_FD_4 "This signal is a counter used for safety checks strategies. This counter is incremented of 1 (one) unit at each frame transmission.";
CM_ SG_ 200 LHFWheelSpeed_PT "This is the value of the left front wheel speed";
CM_ SG_ 200 LHF_WheelSensorFailSts_PT "This signal indicates the fail status of LHF sensor";
CM_ SG_ 200 Ft_RrCouplingTrq_Desired_PT "Desired center differential torque (Nm)";
CM_ SG_ 200 Ft_RrCouplingTrq_Actual_PT "Actual center differential torque (Nm)";
CM_ SG_ 200 ESCActive_PT "This signal is set to Active when the brake intervention by ESC is active.";
CM_ SG_ 200 CRC_PT_SYSTEM_FD_4 "CRC according to SAE J1850 standard at each frame transmission.";
CM_ SG_ 200 Axle_TorqueStatic_D_TTC_PT "Driver requested Axle torque (filtered/ torque shaped)";
CM_ SG_ 200 Axle_TorqueStatic_D_TTC_ESC_PT "Driver requested Axle torque (filtered/ torque shaped) including ESC torque intervention";
CM_ SG_ 200 AWDSysStat_PT "Transfer Case Status";
CM_ SG_ 200 AtmosphericPressureFailSts_PT "This signal indicates if the atmospheric pressure sensor is in fail.";
CM_ SG_ 200 AtmosphericPressure_W_PT "It indicates atmospheric pressure read from the atmospheric pressure sensor";
BA_DEF_ BO_ "CANFD_BRS" ENUM "0","1";
BA_DEF_ BO_ "VFrameFormat" ENUM "StandardCAN","ExtendedCAN","reserved","reserved","reserved","reserved","reserved","reserved","reserved","reserved","reserved","reserved","reserved","reserved","StandardCAN_FD","ExtendedCAN_FD";
BA_DEF_ BO_ "DiagConnection" HEX 0 65535;
BA_DEF_ BO_ "DiagState" ENUM "No","Yes";
BA_DEF_ BO_ "NmAsrMessage" ENUM "No","Yes";
BA_DEF_ BO_ "GenMsgDelayTime" INT 0 65535;
BA_DEF_ BO_ "GenMsgCycleTime" INT 0 65535;
BA_DEF_ BO_ "GenMsgCycleTimeFast" INT 0 65535;
BA_DEF_ BO_ "GenMsgStartDelayTime" INT 0 65535;
BA_DEF_ BO_ "GenMsgILSupport" ENUM "No","Yes";
BA_DEF_ BO_ "GenMsgNrOfRepetition" INT 0 255;
BA_DEF_ BO_ "GenMsgSendType" ENUM "Cyclic","NotUsed","NotUsed","NotUsed","NotUsed","NotUsed","NotUsed","NotUsed","NoMsgSendType";
BA_DEF_ BO_ "NmMessage" ENUM "No","Yes";
BA_DEF_ BO_ "DiagResponse" ENUM "No","Yes";
BA_DEF_ BO_ "Type" ENUM "P","C","PE","COC","PE_Cntrl","E","E_Cntrl","OC","S","BAF","DC","EM","MM","ISO-TP","-";
BA_DEF_ BO_ "DiagRequest" ENUM "No","Yes";
BA_DEF_ SG_ "GenSigTimeoutTime_PBWM" INT 0 65535;
BA_DEF_ SG_ "GenSigTimeoutTime_MCPB" INT 0 65535;
BA_DEF_ SG_ "GenSigTimeoutTime_MCPA" INT 0 65535;
BA_DEF_ SG_ "GenSigTimeoutTime_IDCM" INT 0 65535;
BA_DEF_ SG_ "GenSigTimeoutTime_EVCU2" INT 0 65535;
BA_DEF_ SG_ "GenSigTimeoutTime_ECM" INT 0 65535;
BA_DEF_ SG_ "GenSigTimeoutTime_DMPI" INT 0 65535;
BA_DEF_ SG_ "GenSigTimeoutTime_BPCM" INT 0 65535;
BA_DEF_ SG_ "SystemSignalLongSymbol" STRING ;
BA_DEF_ SG_ "GenSigSendType" ENUM "NotUsed","OnWrite","OnWriteWithRepetition","OnChange","OnChangeWithRepetition","IfActive","IfActiveWithRepetition","NoSigSendType";
BA_DEF_ SG_ "GenSigInactiveValue" INT 0 2147483647;
BA_DEF_ SG_ "GenSigStartValue" INT 0 2147483647;
BA_DEF_DEF_ "CANFD_BRS" "0";
BA_DEF_DEF_ "VFrameFormat" "StandardCAN_FD";
BA_DEF_DEF_ "DiagConnection" 0;
BA_DEF_DEF_ "DiagState" "No";
BA_DEF_DEF_ "NmAsrMessage" "No";
BA_DEF_DEF_ "GenMsgDelayTime" 0;
BA_DEF_DEF_ "GenMsgCycleTime" 0;
BA_DEF_DEF_ "GenMsgCycleTimeFast" 0;
BA_DEF_DEF_ "GenMsgStartDelayTime" 0;
BA_DEF_DEF_ "GenMsgILSupport" "No";
BA_DEF_DEF_ "GenMsgNrOfRepetition" 0;
BA_DEF_DEF_ "GenMsgSendType" "NoMsgSendType";
BA_DEF_DEF_ "NmMessage" "No";
BA_DEF_DEF_ "DiagResponse" "No";
BA_DEF_DEF_ "Type" "-";
BA_DEF_DEF_ "DiagRequest" "No";
BA_DEF_DEF_ "GenSigTimeoutTime_PBWM" 2500;
BA_DEF_DEF_ "GenSigTimeoutTime_MCPB" 2500;
BA_DEF_DEF_ "GenSigTimeoutTime_MCPA" 2500;
BA_DEF_DEF_ "GenSigTimeoutTime_IDCM" 2500;
BA_DEF_DEF_ "GenSigTimeoutTime_EVCU2" 2500;
BA_DEF_DEF_ "GenSigTimeoutTime_ECM" 2500;
BA_DEF_DEF_ "GenSigTimeoutTime_DMPI" 2500;
BA_DEF_DEF_ "GenSigTimeoutTime_BPCM" 2500;
BA_DEF_DEF_ "SystemSignalLongSymbol" "";
BA_DEF_DEF_ "GenSigSendType" "NoSigSendType";
BA_DEF_DEF_ "GenSigInactiveValue" 0;
BA_DEF_DEF_ "GenSigStartValue" 0;
BA_ "CANFD_BRS" BO_ 2654486588 1;
BA_ "VFrameFormat" BO_ 2654486588 15;
BA_ "NmAsrMessage" BO_ 2654486588 1;
BA_ "NmMessage" BO_ 2654486588 1;
BA_ "Type" BO_ 2654486588 8;
BA_ "CANFD_BRS" BO_ 2654486594 1;
BA_ "VFrameFormat" BO_ 2654486594 15;
BA_ "NmAsrMessage" BO_ 2654486594 1;
BA_ "NmMessage" BO_ 2654486594 1;
BA_ "Type" BO_ 2654486594 8;
BA_ "CANFD_BRS" BO_ 214 1;
BA_ "GenMsgCycleTime" BO_ 214 5;
BA_ "GenMsgILSupport" BO_ 214 1;
BA_ "GenMsgSendType" BO_ 214 0;
BA_ "Type" BO_ 214 1;
BA_ "CANFD_BRS" BO_ 1065 1;
BA_ "GenMsgCycleTime" BO_ 1065 100;
BA_ "GenMsgILSupport" BO_ 1065 1;
BA_ "GenMsgSendType" BO_ 1065 0;
BA_ "Type" BO_ 1065 1;
BA_ "CANFD_BRS" BO_ 1057 1;
BA_ "GenMsgCycleTime" BO_ 1057 100;
BA_ "GenMsgILSupport" BO_ 1057 1;
BA_ "GenMsgSendType" BO_ 1057 0;
BA_ "Type" BO_ 1057 1;
BA_ "CANFD_BRS" BO_ 504 1;
BA_ "GenMsgCycleTime" BO_ 504 20;
BA_ "GenMsgILSupport" BO_ 504 1;
BA_ "GenMsgSendType" BO_ 504 0;
BA_ "Type" BO_ 504 1;
BA_ "CANFD_BRS" BO_ 503 1;
BA_ "GenMsgCycleTime" BO_ 503 20;
BA_ "GenMsgILSupport" BO_ 503 1;
BA_ "GenMsgSendType" BO_ 503 0;
BA_ "Type" BO_ 503 1;
BA_ "CANFD_BRS" BO_ 297 1;
BA_ "GenMsgCycleTime" BO_ 297 10;
BA_ "GenMsgILSupport" BO_ 297 1;
BA_ "GenMsgSendType" BO_ 297 0;
BA_ "Type" BO_ 297 1;
BA_ "CANFD_BRS" BO_ 296 1;
BA_ "GenMsgCycleTime" BO_ 296 10;
BA_ "GenMsgILSupport" BO_ 296 1;
BA_ "GenMsgSendType" BO_ 296 0;
BA_ "Type" BO_ 296 1;
BA_ "CANFD_BRS" BO_ 294 1;
BA_ "GenMsgCycleTime" BO_ 294 10;
BA_ "GenMsgILSupport" BO_ 294 1;
BA_ "GenMsgSendType" BO_ 294 0;
BA_ "Type" BO_ 294 1;
BA_ "CANFD_BRS" BO_ 293 1;
BA_ "GenMsgCycleTime" BO_ 293 10;
BA_ "GenMsgILSupport" BO_ 293 1;
BA_ "GenMsgSendType" BO_ 293 0;
BA_ "Type" BO_ 293 1;
BA_ "CANFD_BRS" BO_ 220 1;
BA_ "GenMsgCycleTime" BO_ 220 10;
BA_ "GenMsgILSupport" BO_ 220 1;
BA_ "GenMsgSendType" BO_ 220 0;
BA_ "Type" BO_ 220 1;
BA_ "CANFD_BRS" BO_ 200 1;
BA_ "GenMsgCycleTime" BO_ 200 10;
BA_ "GenMsgILSupport" BO_ 200 1;
BA_ "GenMsgSendType" BO_ 200 0;
BA_ "Type" BO_ 200 1;
BA_ "GenSigTimeoutTime_MCPB" SG_ 220 VIN_MSG_OBD 0;
BA_ "GenSigTimeoutTime_MCPA" SG_ 220 VIN_MSG_OBD 0;
BA_ "GenSigTimeoutTime_IDCM" SG_ 220 VIN_MSG_OBD 0;
BA_ "GenSigTimeoutTime_EVCU2" SG_ 220 VIN_MSG_OBD 0;
BA_ "GenSigTimeoutTime_ECM" SG_ 220 VIN_MSG_OBD 0;
BA_ "GenSigStartValue" SG_ 220 VIN_MSG_OBD 3;
BA_ "GenSigTimeoutTime_PBWM" SG_ 214 TorqueCommand_MCPA_2 0;
BA_ "GenSigTimeoutTime_MCPB" SG_ 214 TorqueCommand_MCPA_2 0;
BA_ "GenSigTimeoutTime_MCPA" SG_ 214 TorqueCommand_MCPA_2 0;
BA_ "GenSigTimeoutTime_IDCM" SG_ 214 TorqueCommand_MCPA_2 0;
BA_ "GenSigTimeoutTime_EVCU2" SG_ 214 TorqueCommand_MCPA_2 0;
BA_ "GenSigTimeoutTime_ECM" SG_ 214 TorqueCommand_MCPA_2 0;
BA_ "GenSigTimeoutTime_BPCM" SG_ 214 TorqueCommand_MCPA_2 0;
BA_ "GenSigStartValue" SG_ 214 TorqueCommand_MCPA_2 4096;
BA_ "GenSigTimeoutTime_PBWM" SG_ 214 TargetMotorRPM_MCPB_2 0;
BA_ "GenSigTimeoutTime_MCPB" SG_ 214 TargetMotorRPM_MCPB_2 0;
BA_ "GenSigTimeoutTime_MCPA" SG_ 214 TargetMotorRPM_MCPB_2 0;
BA_ "GenSigTimeoutTime_IDCM" SG_ 214 TargetMotorRPM_MCPB_2 0;
BA_ "GenSigTimeoutTime_EVCU2" SG_ 214 TargetMotorRPM_MCPB_2 0;
BA_ "GenSigTimeoutTime_ECM" SG_ 214 TargetMotorRPM_MCPB_2 0;
BA_ "GenSigTimeoutTime_BPCM" SG_ 214 TargetMotorRPM_MCPB_2 0;
BA_ "GenSigStartValue" SG_ 214 TargetMotorRPM_MCPB_2 32768;
BA_ "GenSigTimeoutTime_PBWM" SG_ 214 TorqueCommand_MCPB_2 0;
BA_ "GenSigTimeoutTime_MCPB" SG_ 214 TorqueCommand_MCPB_2 0;
BA_ "GenSigTimeoutTime_MCPA" SG_ 214 TorqueCommand_MCPB_2 0;
BA_ "GenSigTimeoutTime_IDCM" SG_ 214 TorqueCommand_MCPB_2 0;
BA_ "GenSigTimeoutTime_EVCU2" SG_ 214 TorqueCommand_MCPB_2 0;
BA_ "GenSigTimeoutTime_ECM" SG_ 214 TorqueCommand_MCPB_2 0;
BA_ "GenSigTimeoutTime_BPCM" SG_ 214 TorqueCommand_MCPB_2 0;
BA_ "GenSigStartValue" SG_ 214 TorqueCommand_MCPB_2 4096;
BA_ "GenSigTimeoutTime_PBWM" SG_ 214 TqGrdtLim_MCPA_2 0;
BA_ "GenSigTimeoutTime_MCPB" SG_ 214 TqGrdtLim_MCPA_2 0;
BA_ "GenSigTimeoutTime_MCPA" SG_ 214 TqGrdtLim_MCPA_2 0;
BA_ "GenSigTimeoutTime_IDCM" SG_ 214 TqGrdtLim_MCPA_2 0;
BA_ "GenSigTimeoutTime_EVCU2" SG_ 214 TqGrdtLim_MCPA_2 0;
BA_ "GenSigTimeoutTime_ECM" SG_ 214 TqGrdtLim_MCPA_2 0;
BA_ "GenSigTimeoutTime_BPCM" SG_ 214 TqGrdtLim_MCPA_2 0;
BA_ "GenSigTimeoutTime_PBWM" SG_ 214 TargetMotorRPM_MCPA_2 0;
BA_ "GenSigTimeoutTime_MCPB" SG_ 214 TargetMotorRPM_MCPA_2 0;
BA_ "GenSigTimeoutTime_MCPA" SG_ 214 TargetMotorRPM_MCPA_2 0;
BA_ "GenSigTimeoutTime_IDCM" SG_ 214 TargetMotorRPM_MCPA_2 0;
BA_ "GenSigTimeoutTime_EVCU2" SG_ 214 TargetMotorRPM_MCPA_2 0;
BA_ "GenSigTimeoutTime_ECM" SG_ 214 TargetMotorRPM_MCPA_2 0;
BA_ "GenSigTimeoutTime_BPCM" SG_ 214 TargetMotorRPM_MCPA_2 0;
BA_ "GenSigStartValue" SG_ 214 TargetMotorRPM_MCPA_2 32768;
BA_ "GenSigTimeoutTime_PBWM" SG_ 214 SpdGrdtLim_MCPB_2 0;
BA_ "GenSigTimeoutTime_MCPB" SG_ 214 SpdGrdtLim_MCPB_2 0;
BA_ "GenSigTimeoutTime_MCPA" SG_ 214 SpdGrdtLim_MCPB_2 0;
BA_ "GenSigTimeoutTime_IDCM" SG_ 214 SpdGrdtLim_MCPB_2 0;
BA_ "GenSigTimeoutTime_EVCU2" SG_ 214 SpdGrdtLim_MCPB_2 0;
BA_ "GenSigTimeoutTime_ECM" SG_ 214 SpdGrdtLim_MCPB_2 0;
BA_ "GenSigTimeoutTime_BPCM" SG_ 214 SpdGrdtLim_MCPB_2 0;
BA_ "GenSigTimeoutTime_PBWM" SG_ 214 SpdGrdtLim_MCPA_2 0;
BA_ "GenSigTimeoutTime_MCPB" SG_ 214 SpdGrdtLim_MCPA_2 0;
BA_ "GenSigTimeoutTime_MCPA" SG_ 214 SpdGrdtLim_MCPA_2 0;
BA_ "GenSigTimeoutTime_IDCM" SG_ 214 SpdGrdtLim_MCPA_2 0;
BA_ "GenSigTimeoutTime_EVCU2" SG_ 214 SpdGrdtLim_MCPA_2 0;
BA_ "GenSigTimeoutTime_ECM" SG_ 214 SpdGrdtLim_MCPA_2 0;
BA_ "GenSigTimeoutTime_BPCM" SG_ 214 SpdGrdtLim_MCPA_2 0;
BA_ "GenSigTimeoutTime_PBWM" SG_ 214 Mtr_6SO_Request_MCPB_2 0;
BA_ "GenSigTimeoutTime_MCPB" SG_ 214 Mtr_6SO_Request_MCPB_2 0;
BA_ "GenSigTimeoutTime_MCPA" SG_ 214 Mtr_6SO_Request_MCPB_2 0;
BA_ "GenSigTimeoutTime_IDCM" SG_ 214 Mtr_6SO_Request_MCPB_2 0;
BA_ "GenSigTimeoutTime_EVCU2" SG_ 214 Mtr_6SO_Request_MCPB_2 0;
BA_ "GenSigTimeoutTime_ECM" SG_ 214 Mtr_6SO_Request_MCPB_2 0;
BA_ "GenSigTimeoutTime_BPCM" SG_ 214 Mtr_6SO_Request_MCPB_2 0;
BA_ "GenSigTimeoutTime_PBWM" SG_ 214 TqGrdtLim_MCPB_2 0;
BA_ "GenSigTimeoutTime_MCPB" SG_ 214 TqGrdtLim_MCPB_2 0;
BA_ "GenSigTimeoutTime_MCPA" SG_ 214 TqGrdtLim_MCPB_2 0;
BA_ "GenSigTimeoutTime_IDCM" SG_ 214 TqGrdtLim_MCPB_2 0;
BA_ "GenSigTimeoutTime_EVCU2" SG_ 214 TqGrdtLim_MCPB_2 0;
BA_ "GenSigTimeoutTime_ECM" SG_ 214 TqGrdtLim_MCPB_2 0;
BA_ "GenSigTimeoutTime_BPCM" SG_ 214 TqGrdtLim_MCPB_2 0;
BA_ "GenSigTimeoutTime_PBWM" SG_ 214 UDCMax_Unlim_MCPA_2 0;
BA_ "GenSigTimeoutTime_MCPB" SG_ 214 UDCMax_Unlim_MCPA_2 0;
BA_ "GenSigTimeoutTime_MCPA" SG_ 214 UDCMax_Unlim_MCPA_2 0;
BA_ "GenSigTimeoutTime_IDCM" SG_ 214 UDCMax_Unlim_MCPA_2 0;
BA_ "GenSigTimeoutTime_EVCU2" SG_ 214 UDCMax_Unlim_MCPA_2 0;
BA_ "GenSigTimeoutTime_ECM" SG_ 214 UDCMax_Unlim_MCPA_2 0;
BA_ "GenSigTimeoutTime_BPCM" SG_ 214 UDCMax_Unlim_MCPA_2 0;
BA_ "GenSigTimeoutTime_PBWM" SG_ 214 UDCMax_Unlim_MCPB_2 0;
BA_ "GenSigTimeoutTime_MCPB" SG_ 214 UDCMax_Unlim_MCPB_2 0;
BA_ "GenSigTimeoutTime_MCPA" SG_ 214 UDCMax_Unlim_MCPB_2 0;
BA_ "GenSigTimeoutTime_IDCM" SG_ 214 UDCMax_Unlim_MCPB_2 0;
BA_ "GenSigTimeoutTime_EVCU2" SG_ 214 UDCMax_Unlim_MCPB_2 0;
BA_ "GenSigTimeoutTime_ECM" SG_ 214 UDCMax_Unlim_MCPB_2 0;
BA_ "GenSigTimeoutTime_BPCM" SG_ 214 UDCMax_Unlim_MCPB_2 0;
BA_ "GenSigTimeoutTime_PBWM" SG_ 214 UDCMin_Unlim_MCPA_2 0;
BA_ "GenSigTimeoutTime_MCPB" SG_ 214 UDCMin_Unlim_MCPA_2 0;
BA_ "GenSigTimeoutTime_MCPA" SG_ 214 UDCMin_Unlim_MCPA_2 0;
BA_ "GenSigTimeoutTime_IDCM" SG_ 214 UDCMin_Unlim_MCPA_2 0;
BA_ "GenSigTimeoutTime_EVCU2" SG_ 214 UDCMin_Unlim_MCPA_2 0;
BA_ "GenSigTimeoutTime_ECM" SG_ 214 UDCMin_Unlim_MCPA_2 0;
BA_ "GenSigTimeoutTime_BPCM" SG_ 214 UDCMin_Unlim_MCPA_2 0;
BA_ "GenSigTimeoutTime_PBWM" SG_ 214 UDCMin_Unlim_MCPB_2 0;
BA_ "GenSigTimeoutTime_MCPB" SG_ 214 UDCMin_Unlim_MCPB_2 0;
BA_ "GenSigTimeoutTime_MCPA" SG_ 214 UDCMin_Unlim_MCPB_2 0;
BA_ "GenSigTimeoutTime_IDCM" SG_ 214 UDCMin_Unlim_MCPB_2 0;
BA_ "GenSigTimeoutTime_EVCU2" SG_ 214 UDCMin_Unlim_MCPB_2 0;
BA_ "GenSigTimeoutTime_ECM" SG_ 214 UDCMin_Unlim_MCPB_2 0;
BA_ "GenSigTimeoutTime_BPCM" SG_ 214 UDCMin_Unlim_MCPB_2 0;
BA_ "GenSigTimeoutTime_PBWM" SG_ 214 Mtr_6SO_Request_MCPA_2 0;
BA_ "GenSigTimeoutTime_MCPB" SG_ 214 Mtr_6SO_Request_MCPA_2 0;
BA_ "GenSigTimeoutTime_MCPA" SG_ 214 Mtr_6SO_Request_MCPA_2 0;
BA_ "GenSigTimeoutTime_IDCM" SG_ 214 Mtr_6SO_Request_MCPA_2 0;
BA_ "GenSigTimeoutTime_EVCU2" SG_ 214 Mtr_6SO_Request_MCPA_2 0;
BA_ "GenSigTimeoutTime_ECM" SG_ 214 Mtr_6SO_Request_MCPA_2 0;
BA_ "GenSigTimeoutTime_BPCM" SG_ 214 Mtr_6SO_Request_MCPA_2 0;
BA_ "GenSigTimeoutTime_PBWM" SG_ 214 ModeCommand_MCPB_2 0;
BA_ "GenSigTimeoutTime_MCPB" SG_ 214 ModeCommand_MCPB_2 0;
BA_ "GenSigTimeoutTime_MCPA" SG_ 214 ModeCommand_MCPB_2 0;
BA_ "GenSigTimeoutTime_IDCM" SG_ 214 ModeCommand_MCPB_2 0;
BA_ "GenSigTimeoutTime_EVCU2" SG_ 214 ModeCommand_MCPB_2 0;
BA_ "GenSigTimeoutTime_ECM" SG_ 214 ModeCommand_MCPB_2 0;
BA_ "GenSigTimeoutTime_BPCM" SG_ 214 ModeCommand_MCPB_2 0;
BA_ "GenSigTimeoutTime_PBWM" SG_ 214 ModeCommand_MCPA_2 0;
BA_ "GenSigTimeoutTime_MCPB" SG_ 214 ModeCommand_MCPA_2 0;
BA_ "GenSigTimeoutTime_MCPA" SG_ 214 ModeCommand_MCPA_2 0;
BA_ "GenSigTimeoutTime_IDCM" SG_ 214 ModeCommand_MCPA_2 0;
BA_ "GenSigTimeoutTime_EVCU2" SG_ 214 ModeCommand_MCPA_2 0;
BA_ "GenSigTimeoutTime_ECM" SG_ 214 ModeCommand_MCPA_2 0;
BA_ "GenSigTimeoutTime_BPCM" SG_ 214 ModeCommand_MCPA_2 0;
BA_ "GenSigTimeoutTime_PBWM" SG_ 214 MinTorque_Limit_MCPB_2 0;
BA_ "GenSigTimeoutTime_MCPB" SG_ 214 MinTorque_Limit_MCPB_2 0;
BA_ "GenSigTimeoutTime_MCPA" SG_ 214 MinTorque_Limit_MCPB_2 0;
BA_ "GenSigTimeoutTime_IDCM" SG_ 214 MinTorque_Limit_MCPB_2 0;
BA_ "GenSigTimeoutTime_EVCU2" SG_ 214 MinTorque_Limit_MCPB_2 0;
BA_ "GenSigTimeoutTime_ECM" SG_ 214 MinTorque_Limit_MCPB_2 0;
BA_ "GenSigTimeoutTime_BPCM" SG_ 214 MinTorque_Limit_MCPB_2 0;
BA_ "GenSigTimeoutTime_MCPB" SG_ 214 MinTorque_Limit_MCPA_2 0;
BA_ "GenSigTimeoutTime_MCPA" SG_ 214 MinTorque_Limit_MCPA_2 0;
BA_ "GenSigTimeoutTime_IDCM" SG_ 214 MinTorque_Limit_MCPA_2 0;
BA_ "GenSigTimeoutTime_EVCU2" SG_ 214 MinTorque_Limit_MCPA_2 0;
BA_ "GenSigTimeoutTime_ECM" SG_ 214 MinTorque_Limit_MCPA_2 0;
BA_ "GenSigTimeoutTime_BPCM" SG_ 214 MinTorque_Limit_MCPA_2 0;
BA_ "GenSigTimeoutTime_PBWM" SG_ 214 MinTorque_Limit_MCPA_2 0;
BA_ "GenSigTimeoutTime_PBWM" SG_ 214 MessageCounter_INVTARGET1_2 0;
BA_ "GenSigTimeoutTime_MCPB" SG_ 214 MessageCounter_INVTARGET1_2 0;
BA_ "GenSigTimeoutTime_MCPA" SG_ 214 MessageCounter_INVTARGET1_2 0;
BA_ "GenSigTimeoutTime_IDCM" SG_ 214 MessageCounter_INVTARGET1_2 0;
BA_ "GenSigTimeoutTime_EVCU2" SG_ 214 MessageCounter_INVTARGET1_2 0;
BA_ "GenSigTimeoutTime_ECM" SG_ 214 MessageCounter_INVTARGET1_2 0;
BA_ "GenSigTimeoutTime_BPCM" SG_ 214 MessageCounter_INVTARGET1_2 0;
BA_ "GenSigTimeoutTime_PBWM" SG_ 214 MaxTorque_Limit_MCPB_2 0;
BA_ "GenSigTimeoutTime_MCPB" SG_ 214 MaxTorque_Limit_MCPB_2 0;
BA_ "GenSigTimeoutTime_MCPA" SG_ 214 MaxTorque_Limit_MCPB_2 0;
BA_ "GenSigTimeoutTime_IDCM" SG_ 214 MaxTorque_Limit_MCPB_2 0;
BA_ "GenSigTimeoutTime_EVCU2" SG_ 214 MaxTorque_Limit_MCPB_2 0;
BA_ "GenSigTimeoutTime_ECM" SG_ 214 MaxTorque_Limit_MCPB_2 0;
BA_ "GenSigTimeoutTime_BPCM" SG_ 214 MaxTorque_Limit_MCPB_2 0;
BA_ "GenSigStartValue" SG_ 214 MaxTorque_Limit_MCPB_2 16382;
BA_ "GenSigTimeoutTime_PBWM" SG_ 214 MaxTorque_Limit_MCPA_2 0;
BA_ "GenSigTimeoutTime_MCPB" SG_ 214 MaxTorque_Limit_MCPA_2 0;
BA_ "GenSigTimeoutTime_MCPA" SG_ 214 MaxTorque_Limit_MCPA_2 0;
BA_ "GenSigTimeoutTime_IDCM" SG_ 214 MaxTorque_Limit_MCPA_2 0;
BA_ "GenSigTimeoutTime_EVCU2" SG_ 214 MaxTorque_Limit_MCPA_2 0;
BA_ "GenSigTimeoutTime_ECM" SG_ 214 MaxTorque_Limit_MCPA_2 0;
BA_ "GenSigTimeoutTime_BPCM" SG_ 214 MaxTorque_Limit_MCPA_2 0;
BA_ "GenSigStartValue" SG_ 214 MaxTorque_Limit_MCPA_2 16382;
BA_ "GenSigTimeoutTime_PBWM" SG_ 214 MAC_INVTARGET1_2 0;
BA_ "GenSigTimeoutTime_MCPB" SG_ 214 MAC_INVTARGET1_2 0;
BA_ "GenSigTimeoutTime_MCPA" SG_ 214 MAC_INVTARGET1_2 0;
BA_ "GenSigTimeoutTime_IDCM" SG_ 214 MAC_INVTARGET1_2 0;
BA_ "GenSigTimeoutTime_EVCU2" SG_ 214 MAC_INVTARGET1_2 0;
BA_ "GenSigTimeoutTime_ECM" SG_ 214 MAC_INVTARGET1_2 0;
BA_ "GenSigTimeoutTime_BPCM" SG_ 214 MAC_INVTARGET1_2 0;
BA_ "GenSigTimeoutTime_PBWM" SG_ 214 LgsDiagCldStrtCndMet_MCPB_2 0;
BA_ "GenSigTimeoutTime_MCPB" SG_ 214 LgsDiagCldStrtCndMet_MCPB_2 0;
BA_ "GenSigTimeoutTime_MCPA" SG_ 214 LgsDiagCldStrtCndMet_MCPB_2 0;
BA_ "GenSigTimeoutTime_IDCM" SG_ 214 LgsDiagCldStrtCndMet_MCPB_2 0;
BA_ "GenSigTimeoutTime_EVCU2" SG_ 214 LgsDiagCldStrtCndMet_MCPB_2 0;
BA_ "GenSigTimeoutTime_ECM" SG_ 214 LgsDiagCldStrtCndMet_MCPB_2 0;
BA_ "GenSigTimeoutTime_BPCM" SG_ 214 LgsDiagCldStrtCndMet_MCPB_2 0;
BA_ "GenSigTimeoutTime_PBWM" SG_ 214 LgsDiagCldStrtCndFltPr_MCPB_2 0;
BA_ "GenSigTimeoutTime_MCPB" SG_ 214 LgsDiagCldStrtCndFltPr_MCPB_2 0;
BA_ "GenSigTimeoutTime_MCPA" SG_ 214 LgsDiagCldStrtCndFltPr_MCPB_2 0;
BA_ "GenSigTimeoutTime_IDCM" SG_ 214 LgsDiagCldStrtCndFltPr_MCPB_2 0;
BA_ "GenSigTimeoutTime_EVCU2" SG_ 214 LgsDiagCldStrtCndFltPr_MCPB_2 0;
BA_ "GenSigTimeoutTime_ECM" SG_ 214 LgsDiagCldStrtCndFltPr_MCPB_2 0;
BA_ "GenSigTimeoutTime_BPCM" SG_ 214 LgsDiagCldStrtCndFltPr_MCPB_2 0;
BA_ "GenSigTimeoutTime_PBWM" SG_ 214 HVBatVlt_V_2 0;
BA_ "GenSigTimeoutTime_MCPB" SG_ 214 HVBatVlt_V_2 0;
BA_ "GenSigTimeoutTime_MCPA" SG_ 214 HVBatVlt_V_2 0;
BA_ "GenSigTimeoutTime_IDCM" SG_ 214 HVBatVlt_V_2 0;
BA_ "GenSigTimeoutTime_EVCU2" SG_ 214 HVBatVlt_V_2 0;
BA_ "GenSigTimeoutTime_ECM" SG_ 214 HVBatVlt_V_2 0;
BA_ "GenSigTimeoutTime_BPCM" SG_ 214 HVBatVlt_V_2 0;
BA_ "GenSigTimeoutTime_PBWM" SG_ 214 EVCU_END_Request_Flag_2 0;
BA_ "GenSigTimeoutTime_MCPB" SG_ 214 EVCU_END_Request_Flag_2 0;
BA_ "GenSigTimeoutTime_MCPA" SG_ 214 EVCU_END_Request_Flag_2 0;
BA_ "GenSigTimeoutTime_IDCM" SG_ 214 EVCU_END_Request_Flag_2 0;
BA_ "GenSigTimeoutTime_EVCU2" SG_ 214 EVCU_END_Request_Flag_2 0;
BA_ "GenSigTimeoutTime_ECM" SG_ 214 EVCU_END_Request_Flag_2 0;
BA_ "GenSigTimeoutTime_BPCM" SG_ 214 EVCU_END_Request_Flag_2 0;
BA_ "GenSigTimeoutTime_PBWM" SG_ 214 CRC_INVTARGET1_2 0;
BA_ "GenSigTimeoutTime_MCPB" SG_ 214 CRC_INVTARGET1_2 0;
BA_ "GenSigTimeoutTime_MCPA" SG_ 214 CRC_INVTARGET1_2 0;
BA_ "GenSigTimeoutTime_IDCM" SG_ 214 CRC_INVTARGET1_2 0;
BA_ "GenSigTimeoutTime_EVCU2" SG_ 214 CRC_INVTARGET1_2 0;
BA_ "GenSigTimeoutTime_ECM" SG_ 214 CRC_INVTARGET1_2 0;
BA_ "GenSigTimeoutTime_BPCM" SG_ 214 CRC_INVTARGET1_2 0;
BA_ "GenSigTimeoutTime_PBWM" SG_ 214 Cntr_INVTARGET1_2 0;
BA_ "GenSigTimeoutTime_MCPB" SG_ 214 Cntr_INVTARGET1_2 0;
BA_ "GenSigTimeoutTime_MCPA" SG_ 214 Cntr_INVTARGET1_2 0;
BA_ "GenSigTimeoutTime_IDCM" SG_ 214 Cntr_INVTARGET1_2 0;
BA_ "GenSigTimeoutTime_EVCU2" SG_ 214 Cntr_INVTARGET1_2 0;
BA_ "GenSigTimeoutTime_ECM" SG_ 214 Cntr_INVTARGET1_2 0;
BA_ "GenSigTimeoutTime_BPCM" SG_ 214 Cntr_INVTARGET1_2 0;
BA_ "GenSigTimeoutTime_PBWM" SG_ 214 AEMD_MinOffset_MCPB_2 0;
BA_ "GenSigTimeoutTime_MCPB" SG_ 214 AEMD_MinOffset_MCPB_2 0;
BA_ "GenSigTimeoutTime_MCPA" SG_ 214 AEMD_MinOffset_MCPB_2 0;
BA_ "GenSigTimeoutTime_IDCM" SG_ 214 AEMD_MinOffset_MCPB_2 0;
BA_ "GenSigTimeoutTime_EVCU2" SG_ 214 AEMD_MinOffset_MCPB_2 0;
BA_ "GenSigTimeoutTime_ECM" SG_ 214 AEMD_MinOffset_MCPB_2 0;
BA_ "GenSigTimeoutTime_BPCM" SG_ 214 AEMD_MinOffset_MCPB_2 0;
BA_ "GenSigStartValue" SG_ 214 AEMD_MinOffset_MCPB_2 4095;
BA_ "GenSigTimeoutTime_PBWM" SG_ 214 AEMD_Cutoff_FreqHigh_MCPB_2 0;
BA_ "GenSigTimeoutTime_MCPB" SG_ 214 AEMD_Cutoff_FreqHigh_MCPB_2 0;
BA_ "GenSigTimeoutTime_MCPA" SG_ 214 AEMD_Cutoff_FreqHigh_MCPB_2 0;
BA_ "GenSigTimeoutTime_IDCM" SG_ 214 AEMD_Cutoff_FreqHigh_MCPB_2 0;
BA_ "GenSigTimeoutTime_EVCU2" SG_ 214 AEMD_Cutoff_FreqHigh_MCPB_2 0;
BA_ "GenSigTimeoutTime_ECM" SG_ 214 AEMD_Cutoff_FreqHigh_MCPB_2 0;
BA_ "GenSigTimeoutTime_BPCM" SG_ 214 AEMD_Cutoff_FreqHigh_MCPB_2 0;
BA_ "GenSigTimeoutTime_PBWM" SG_ 214 AEMD_Cutoff_FreqHigh_MCPA_2 0;
BA_ "GenSigTimeoutTime_MCPB" SG_ 214 AEMD_Cutoff_FreqHigh_MCPA_2 0;
BA_ "GenSigTimeoutTime_MCPA" SG_ 214 AEMD_Cutoff_FreqHigh_MCPA_2 0;
BA_ "GenSigTimeoutTime_IDCM" SG_ 214 AEMD_Cutoff_FreqHigh_MCPA_2 0;
BA_ "GenSigTimeoutTime_EVCU2" SG_ 214 AEMD_Cutoff_FreqHigh_MCPA_2 0;
BA_ "GenSigTimeoutTime_ECM" SG_ 214 AEMD_Cutoff_FreqHigh_MCPA_2 0;
BA_ "GenSigTimeoutTime_BPCM" SG_ 214 AEMD_Cutoff_FreqHigh_MCPA_2 0;
BA_ "GenSigTimeoutTime_PBWM" SG_ 214 AEMD_MinOffset_MCPA_2 0;
BA_ "GenSigTimeoutTime_MCPB" SG_ 214 AEMD_MinOffset_MCPA_2 0;
BA_ "GenSigTimeoutTime_MCPA" SG_ 214 AEMD_MinOffset_MCPA_2 0;
BA_ "GenSigTimeoutTime_IDCM" SG_ 214 AEMD_MinOffset_MCPA_2 0;
BA_ "GenSigTimeoutTime_EVCU2" SG_ 214 AEMD_MinOffset_MCPA_2 0;
BA_ "GenSigTimeoutTime_ECM" SG_ 214 AEMD_MinOffset_MCPA_2 0;
BA_ "GenSigTimeoutTime_BPCM" SG_ 214 AEMD_MinOffset_MCPA_2 0;
BA_ "GenSigStartValue" SG_ 214 AEMD_MinOffset_MCPA_2 4095;
BA_ "GenSigTimeoutTime_PBWM" SG_ 214 AEMD_MaxOffset_MCPB_2 0;
BA_ "GenSigTimeoutTime_MCPB" SG_ 214 AEMD_MaxOffset_MCPB_2 0;
BA_ "GenSigTimeoutTime_MCPA" SG_ 214 AEMD_MaxOffset_MCPB_2 0;
BA_ "GenSigTimeoutTime_IDCM" SG_ 214 AEMD_MaxOffset_MCPB_2 0;
BA_ "GenSigTimeoutTime_EVCU2" SG_ 214 AEMD_MaxOffset_MCPB_2 0;
BA_ "GenSigTimeoutTime_ECM" SG_ 214 AEMD_MaxOffset_MCPB_2 0;
BA_ "GenSigTimeoutTime_BPCM" SG_ 214 AEMD_MaxOffset_MCPB_2 0;
BA_ "GenSigTimeoutTime_PBWM" SG_ 214 AEMD_Cutoff_FreqLow_MCPB_2 0;
BA_ "GenSigTimeoutTime_MCPB" SG_ 214 AEMD_Cutoff_FreqLow_MCPB_2 0;
BA_ "GenSigTimeoutTime_MCPA" SG_ 214 AEMD_Cutoff_FreqLow_MCPB_2 0;
BA_ "GenSigTimeoutTime_IDCM" SG_ 214 AEMD_Cutoff_FreqLow_MCPB_2 0;
BA_ "GenSigTimeoutTime_EVCU2" SG_ 214 AEMD_Cutoff_FreqLow_MCPB_2 0;
BA_ "GenSigTimeoutTime_ECM" SG_ 214 AEMD_Cutoff_FreqLow_MCPB_2 0;
BA_ "GenSigTimeoutTime_BPCM" SG_ 214 AEMD_Cutoff_FreqLow_MCPB_2 0;
BA_ "GenSigTimeoutTime_PBWM" SG_ 214 AEMD_Cutoff_FreqLow_MCPA_2 0;
BA_ "GenSigTimeoutTime_MCPB" SG_ 214 AEMD_Cutoff_FreqLow_MCPA_2 0;
BA_ "GenSigTimeoutTime_MCPA" SG_ 214 AEMD_Cutoff_FreqLow_MCPA_2 0;
BA_ "GenSigTimeoutTime_IDCM" SG_ 214 AEMD_Cutoff_FreqLow_MCPA_2 0;
BA_ "GenSigTimeoutTime_EVCU2" SG_ 214 AEMD_Cutoff_FreqLow_MCPA_2 0;
BA_ "GenSigTimeoutTime_ECM" SG_ 214 AEMD_Cutoff_FreqLow_MCPA_2 0;
BA_ "GenSigTimeoutTime_BPCM" SG_ 214 AEMD_Cutoff_FreqLow_MCPA_2 0;
BA_ "GenSigTimeoutTime_PBWM" SG_ 297 UDCMin_Unlim_MCPB_P 0;
BA_ "GenSigTimeoutTime_MCPA" SG_ 297 UDCMin_Unlim_MCPB_P 0;
BA_ "GenSigTimeoutTime_IDCM" SG_ 297 UDCMin_Unlim_MCPB_P 0;
BA_ "GenSigTimeoutTime_EVCU2" SG_ 297 UDCMin_Unlim_MCPB_P 0;
BA_ "GenSigTimeoutTime_ECM" SG_ 297 UDCMin_Unlim_MCPB_P 0;
BA_ "GenSigTimeoutTime_DMPI" SG_ 297 UDCMin_Unlim_MCPB_P 0;
BA_ "GenSigTimeoutTime_BPCM" SG_ 297 UDCMin_Unlim_MCPB_P 0;
BA_ "GenSigTimeoutTime_PBWM" SG_ 297 UDCMin_Unlim_MCPA_P 0;
BA_ "GenSigTimeoutTime_MCPB" SG_ 297 UDCMin_Unlim_MCPA_P 0;
BA_ "GenSigTimeoutTime_IDCM" SG_ 297 UDCMin_Unlim_MCPA_P 0;
BA_ "GenSigTimeoutTime_EVCU2" SG_ 297 UDCMin_Unlim_MCPA_P 0;
BA_ "GenSigTimeoutTime_ECM" SG_ 297 UDCMin_Unlim_MCPA_P 0;
BA_ "GenSigTimeoutTime_DMPI" SG_ 297 UDCMin_Unlim_MCPA_P 0;
BA_ "GenSigTimeoutTime_BPCM" SG_ 297 UDCMin_Unlim_MCPA_P 0;
BA_ "GenSigTimeoutTime_PBWM" SG_ 297 UDCMax_Unlim_MCPB_P 0;
BA_ "GenSigTimeoutTime_MCPA" SG_ 297 UDCMax_Unlim_MCPB_P 0;
BA_ "GenSigTimeoutTime_IDCM" SG_ 297 UDCMax_Unlim_MCPB_P 0;
BA_ "GenSigTimeoutTime_EVCU2" SG_ 297 UDCMax_Unlim_MCPB_P 0;
BA_ "GenSigTimeoutTime_ECM" SG_ 297 UDCMax_Unlim_MCPB_P 0;
BA_ "GenSigTimeoutTime_DMPI" SG_ 297 UDCMax_Unlim_MCPB_P 0;
BA_ "GenSigTimeoutTime_BPCM" SG_ 297 UDCMax_Unlim_MCPB_P 0;
BA_ "GenSigTimeoutTime_PBWM" SG_ 297 UDCMax_Unlim_MCPA_P 0;
BA_ "GenSigTimeoutTime_MCPB" SG_ 297 UDCMax_Unlim_MCPA_P 0;
BA_ "GenSigTimeoutTime_IDCM" SG_ 297 UDCMax_Unlim_MCPA_P 0;
BA_ "GenSigTimeoutTime_EVCU2" SG_ 297 UDCMax_Unlim_MCPA_P 0;
BA_ "GenSigTimeoutTime_ECM" SG_ 297 UDCMax_Unlim_MCPA_P 0;
BA_ "GenSigTimeoutTime_DMPI" SG_ 297 UDCMax_Unlim_MCPA_P 0;
BA_ "GenSigTimeoutTime_BPCM" SG_ 297 UDCMax_Unlim_MCPA_P 0;
BA_ "GenSigTimeoutTime_PBWM" SG_ 297 TqGrdtLim_MCPB_P 0;
BA_ "GenSigTimeoutTime_MCPA" SG_ 297 TqGrdtLim_MCPB_P 0;
BA_ "GenSigTimeoutTime_IDCM" SG_ 297 TqGrdtLim_MCPB_P 0;
BA_ "GenSigTimeoutTime_EVCU2" SG_ 297 TqGrdtLim_MCPB_P 0;
BA_ "GenSigTimeoutTime_ECM" SG_ 297 TqGrdtLim_MCPB_P 0;
BA_ "GenSigTimeoutTime_DMPI" SG_ 297 TqGrdtLim_MCPB_P 0;
BA_ "GenSigTimeoutTime_BPCM" SG_ 297 TqGrdtLim_MCPB_P 0;
BA_ "GenSigTimeoutTime_PBWM" SG_ 297 TqGrdtLim_MCPA_P 0;
BA_ "GenSigTimeoutTime_MCPB" SG_ 297 TqGrdtLim_MCPA_P 0;
BA_ "GenSigTimeoutTime_IDCM" SG_ 297 TqGrdtLim_MCPA_P 0;
BA_ "GenSigTimeoutTime_EVCU2" SG_ 297 TqGrdtLim_MCPA_P 0;
BA_ "GenSigTimeoutTime_ECM" SG_ 297 TqGrdtLim_MCPA_P 0;
BA_ "GenSigTimeoutTime_DMPI" SG_ 297 TqGrdtLim_MCPA_P 0;
BA_ "GenSigTimeoutTime_BPCM" SG_ 297 TqGrdtLim_MCPA_P 0;
BA_ "GenSigTimeoutTime_BPCM" SG_ 297 SpdGrdtLim_MCPB_P 0;
BA_ "GenSigTimeoutTime_PBWM" SG_ 297 SpdGrdtLim_MCPB_P 0;
BA_ "GenSigTimeoutTime_MCPA" SG_ 297 SpdGrdtLim_MCPB_P 0;
BA_ "GenSigTimeoutTime_IDCM" SG_ 297 SpdGrdtLim_MCPB_P 0;
BA_ "GenSigTimeoutTime_EVCU2" SG_ 297 SpdGrdtLim_MCPB_P 0;
BA_ "GenSigTimeoutTime_ECM" SG_ 297 SpdGrdtLim_MCPB_P 0;
BA_ "GenSigTimeoutTime_DMPI" SG_ 297 SpdGrdtLim_MCPB_P 0;
BA_ "GenSigTimeoutTime_PBWM" SG_ 297 SpdGrdtLim_MCPA_P 0;
BA_ "GenSigTimeoutTime_MCPB" SG_ 297 SpdGrdtLim_MCPA_P 0;
BA_ "GenSigTimeoutTime_IDCM" SG_ 297 SpdGrdtLim_MCPA_P 0;
BA_ "GenSigTimeoutTime_EVCU2" SG_ 297 SpdGrdtLim_MCPA_P 0;
BA_ "GenSigTimeoutTime_ECM" SG_ 297 SpdGrdtLim_MCPA_P 0;
BA_ "GenSigTimeoutTime_DMPI" SG_ 297 SpdGrdtLim_MCPA_P 0;
BA_ "GenSigTimeoutTime_BPCM" SG_ 297 SpdGrdtLim_MCPA_P 0;
BA_ "GenSigTimeoutTime_PBWM" SG_ 297 Pwr_Electr_Loop_FlwRate_MCPB_P 0;
BA_ "GenSigTimeoutTime_MCPA" SG_ 297 Pwr_Electr_Loop_FlwRate_MCPB_P 0;
BA_ "GenSigTimeoutTime_IDCM" SG_ 297 Pwr_Electr_Loop_FlwRate_MCPB_P 0;
BA_ "GenSigTimeoutTime_EVCU2" SG_ 297 Pwr_Electr_Loop_FlwRate_MCPB_P 0;
BA_ "GenSigTimeoutTime_ECM" SG_ 297 Pwr_Electr_Loop_FlwRate_MCPB_P 0;
BA_ "GenSigTimeoutTime_DMPI" SG_ 297 Pwr_Electr_Loop_FlwRate_MCPB_P 0;
BA_ "GenSigTimeoutTime_BPCM" SG_ 297 Pwr_Electr_Loop_FlwRate_MCPB_P 0;
BA_ "GenSigTimeoutTime_PBWM" SG_ 297 Pwr_Electr_Loop_FlwRate_MCPA_P 0;
BA_ "GenSigTimeoutTime_MCPB" SG_ 297 Pwr_Electr_Loop_FlwRate_MCPA_P 0;
BA_ "GenSigTimeoutTime_IDCM" SG_ 297 Pwr_Electr_Loop_FlwRate_MCPA_P 0;
BA_ "GenSigTimeoutTime_EVCU2" SG_ 297 Pwr_Electr_Loop_FlwRate_MCPA_P 0;
BA_ "GenSigTimeoutTime_ECM" SG_ 297 Pwr_Electr_Loop_FlwRate_MCPA_P 0;
BA_ "GenSigTimeoutTime_DMPI" SG_ 297 Pwr_Electr_Loop_FlwRate_MCPA_P 0;
BA_ "GenSigTimeoutTime_BPCM" SG_ 297 Pwr_Electr_Loop_FlwRate_MCPA_P 0;
BA_ "GenSigTimeoutTime_PBWM" SG_ 297 MC_INVTARGET_PROPULSION2 0;
BA_ "GenSigTimeoutTime_IDCM" SG_ 297 MC_INVTARGET_PROPULSION2 0;
BA_ "GenSigTimeoutTime_EVCU2" SG_ 297 MC_INVTARGET_PROPULSION2 0;
BA_ "GenSigTimeoutTime_ECM" SG_ 297 MC_INVTARGET_PROPULSION2 0;
BA_ "GenSigTimeoutTime_DMPI" SG_ 297 MC_INVTARGET_PROPULSION2 0;
BA_ "GenSigTimeoutTime_BPCM" SG_ 297 MC_INVTARGET_PROPULSION2 0;
BA_ "GenSigTimeoutTime_PBWM" SG_ 214 AEMD_Sclr_Gn_MCPB_2 0;
BA_ "GenSigTimeoutTime_MCPB" SG_ 214 AEMD_Sclr_Gn_MCPB_2 0;
BA_ "GenSigTimeoutTime_MCPA" SG_ 214 AEMD_Sclr_Gn_MCPB_2 0;
BA_ "GenSigTimeoutTime_IDCM" SG_ 214 AEMD_Sclr_Gn_MCPB_2 0;
BA_ "GenSigTimeoutTime_EVCU2" SG_ 214 AEMD_Sclr_Gn_MCPB_2 0;
BA_ "GenSigTimeoutTime_ECM" SG_ 214 AEMD_Sclr_Gn_MCPB_2 0;
BA_ "GenSigTimeoutTime_BPCM" SG_ 214 AEMD_Sclr_Gn_MCPB_2 0;
BA_ "GenSigTimeoutTime_PBWM" SG_ 214 AEMD_Sclr_Gn_MCPA_2 0;
BA_ "GenSigTimeoutTime_MCPB" SG_ 214 AEMD_Sclr_Gn_MCPA_2 0;
BA_ "GenSigTimeoutTime_MCPA" SG_ 214 AEMD_Sclr_Gn_MCPA_2 0;
BA_ "GenSigTimeoutTime_IDCM" SG_ 214 AEMD_Sclr_Gn_MCPA_2 0;
BA_ "GenSigTimeoutTime_EVCU2" SG_ 214 AEMD_Sclr_Gn_MCPA_2 0;
BA_ "GenSigTimeoutTime_ECM" SG_ 214 AEMD_Sclr_Gn_MCPA_2 0;
BA_ "GenSigTimeoutTime_BPCM" SG_ 214 AEMD_Sclr_Gn_MCPA_2 0;
BA_ "GenSigTimeoutTime_PBWM" SG_ 214 AEMD_Torque_BoostVolt_Margin 0;
BA_ "GenSigTimeoutTime_MCPB" SG_ 214 AEMD_Torque_BoostVolt_Margin 0;
BA_ "GenSigTimeoutTime_MCPA" SG_ 214 AEMD_Torque_BoostVolt_Margin 0;
BA_ "GenSigTimeoutTime_IDCM" SG_ 214 AEMD_Torque_BoostVolt_Margin 0;
BA_ "GenSigTimeoutTime_EVCU2" SG_ 214 AEMD_Torque_BoostVolt_Margin 0;
BA_ "GenSigTimeoutTime_ECM" SG_ 214 AEMD_Torque_BoostVolt_Margin 0;
BA_ "GenSigTimeoutTime_BPCM" SG_ 214 AEMD_Torque_BoostVolt_Margin 0;
BA_ "GenSigTimeoutTime_PBWM" SG_ 214 Boost_Torque_Margin_MCPA 0;
BA_ "GenSigTimeoutTime_MCPB" SG_ 214 Boost_Torque_Margin_MCPA 0;
BA_ "GenSigTimeoutTime_MCPA" SG_ 214 Boost_Torque_Margin_MCPA 0;
BA_ "GenSigTimeoutTime_IDCM" SG_ 214 Boost_Torque_Margin_MCPA 0;
BA_ "GenSigTimeoutTime_EVCU2" SG_ 214 Boost_Torque_Margin_MCPA 0;
BA_ "GenSigTimeoutTime_ECM" SG_ 214 Boost_Torque_Margin_MCPA 0;
BA_ "GenSigTimeoutTime_BPCM" SG_ 214 Boost_Torque_Margin_MCPA 0;
BA_ "GenSigStartValue" SG_ 214 Boost_Torque_Margin_MCPA 512;
BA_ "GenSigTimeoutTime_PBWM" SG_ 214 Boost_Torque_Margin_MCPB 0;
BA_ "GenSigTimeoutTime_MCPB" SG_ 214 Boost_Torque_Margin_MCPB 0;
BA_ "GenSigTimeoutTime_MCPA" SG_ 214 Boost_Torque_Margin_MCPB 0;
BA_ "GenSigTimeoutTime_IDCM" SG_ 214 Boost_Torque_Margin_MCPB 0;
BA_ "GenSigTimeoutTime_EVCU2" SG_ 214 Boost_Torque_Margin_MCPB 0;
BA_ "GenSigTimeoutTime_ECM" SG_ 214 Boost_Torque_Margin_MCPB 0;
BA_ "GenSigTimeoutTime_BPCM" SG_ 214 Boost_Torque_Margin_MCPB 0;
BA_ "GenSigStartValue" SG_ 214 Boost_Torque_Margin_MCPB 512;
BA_ "GenSigTimeoutTime_PBWM" SG_ 296 AEMD_Sclr_Gn_MCPB_P 0;
BA_ "GenSigTimeoutTime_MCPA" SG_ 296 AEMD_Sclr_Gn_MCPB_P 0;
BA_ "GenSigTimeoutTime_IDCM" SG_ 296 AEMD_Sclr_Gn_MCPB_P 0;
BA_ "GenSigTimeoutTime_EVCU2" SG_ 296 AEMD_Sclr_Gn_MCPB_P 0;
BA_ "GenSigTimeoutTime_ECM" SG_ 296 AEMD_Sclr_Gn_MCPB_P 0;
BA_ "GenSigTimeoutTime_DMPI" SG_ 296 AEMD_Sclr_Gn_MCPB_P 0;
BA_ "GenSigTimeoutTime_BPCM" SG_ 296 AEMD_Sclr_Gn_MCPB_P 0;
BA_ "GenSigTimeoutTime_PBWM" SG_ 296 AEMD_Sclr_Gn_MCPA_P 0;
BA_ "GenSigTimeoutTime_MCPB" SG_ 296 AEMD_Sclr_Gn_MCPA_P 0;
BA_ "GenSigTimeoutTime_IDCM" SG_ 296 AEMD_Sclr_Gn_MCPA_P 0;
BA_ "GenSigTimeoutTime_EVCU2" SG_ 296 AEMD_Sclr_Gn_MCPA_P 0;
BA_ "GenSigTimeoutTime_ECM" SG_ 296 AEMD_Sclr_Gn_MCPA_P 0;
BA_ "GenSigTimeoutTime_DMPI" SG_ 296 AEMD_Sclr_Gn_MCPA_P 0;
BA_ "GenSigTimeoutTime_BPCM" SG_ 296 AEMD_Sclr_Gn_MCPA_P 0;
BA_ "GenSigTimeoutTime_PBWM" SG_ 296 AEMD_Cutoff_FreqHigh_MCPA_P 0;
BA_ "GenSigTimeoutTime_MCPB" SG_ 296 AEMD_Cutoff_FreqHigh_MCPA_P 0;
BA_ "GenSigTimeoutTime_IDCM" SG_ 296 AEMD_Cutoff_FreqHigh_MCPA_P 0;
BA_ "GenSigTimeoutTime_EVCU2" SG_ 296 AEMD_Cutoff_FreqHigh_MCPA_P 0;
BA_ "GenSigTimeoutTime_ECM" SG_ 296 AEMD_Cutoff_FreqHigh_MCPA_P 0;
BA_ "GenSigTimeoutTime_DMPI" SG_ 296 AEMD_Cutoff_FreqHigh_MCPA_P 0;
BA_ "GenSigTimeoutTime_BPCM" SG_ 296 AEMD_Cutoff_FreqHigh_MCPA_P 0;
BA_ "GenSigTimeoutTime_PBWM" SG_ 296 AEMD_Cutoff_FreqLow_MCPA_P 0;
BA_ "GenSigTimeoutTime_MCPB" SG_ 296 AEMD_Cutoff_FreqLow_MCPA_P 0;
BA_ "GenSigTimeoutTime_IDCM" SG_ 296 AEMD_Cutoff_FreqLow_MCPA_P 0;
BA_ "GenSigTimeoutTime_EVCU2" SG_ 296 AEMD_Cutoff_FreqLow_MCPA_P 0;
BA_ "GenSigTimeoutTime_ECM" SG_ 296 AEMD_Cutoff_FreqLow_MCPA_P 0;
BA_ "GenSigTimeoutTime_DMPI" SG_ 296 AEMD_Cutoff_FreqLow_MCPA_P 0;
BA_ "GenSigTimeoutTime_BPCM" SG_ 296 AEMD_Cutoff_FreqLow_MCPA_P 0;
BA_ "GenSigTimeoutTime_PBWM" SG_ 296 AEMD_Cutoff_FreqHigh_MCPB_P 0;
BA_ "GenSigTimeoutTime_MCPA" SG_ 296 AEMD_Cutoff_FreqHigh_MCPB_P 0;
BA_ "GenSigTimeoutTime_IDCM" SG_ 296 AEMD_Cutoff_FreqHigh_MCPB_P 0;
BA_ "GenSigTimeoutTime_EVCU2" SG_ 296 AEMD_Cutoff_FreqHigh_MCPB_P 0;
BA_ "GenSigTimeoutTime_ECM" SG_ 296 AEMD_Cutoff_FreqHigh_MCPB_P 0;
BA_ "GenSigTimeoutTime_DMPI" SG_ 296 AEMD_Cutoff_FreqHigh_MCPB_P 0;
BA_ "GenSigTimeoutTime_BPCM" SG_ 296 AEMD_Cutoff_FreqHigh_MCPB_P 0;
BA_ "GenSigTimeoutTime_PBWM" SG_ 296 AEMD_MinOffset_MCPA_P 0;
BA_ "GenSigTimeoutTime_MCPB" SG_ 296 AEMD_MinOffset_MCPA_P 0;
BA_ "GenSigTimeoutTime_IDCM" SG_ 296 AEMD_MinOffset_MCPA_P 0;
BA_ "GenSigTimeoutTime_EVCU2" SG_ 296 AEMD_MinOffset_MCPA_P 0;
BA_ "GenSigTimeoutTime_ECM" SG_ 296 AEMD_MinOffset_MCPA_P 0;
BA_ "GenSigTimeoutTime_DMPI" SG_ 296 AEMD_MinOffset_MCPA_P 0;
BA_ "GenSigTimeoutTime_BPCM" SG_ 296 AEMD_MinOffset_MCPA_P 0;
BA_ "GenSigStartValue" SG_ 296 AEMD_MinOffset_MCPA_P 8184;
BA_ "GenSigTimeoutTime_PBWM" SG_ 296 AEMD_MaxOffset_MCPB_P 0;
BA_ "GenSigTimeoutTime_MCPA" SG_ 296 AEMD_MaxOffset_MCPB_P 0;
BA_ "GenSigTimeoutTime_IDCM" SG_ 296 AEMD_MaxOffset_MCPB_P 0;
BA_ "GenSigTimeoutTime_EVCU2" SG_ 296 AEMD_MaxOffset_MCPB_P 0;
BA_ "GenSigTimeoutTime_ECM" SG_ 296 AEMD_MaxOffset_MCPB_P 0;
BA_ "GenSigTimeoutTime_DMPI" SG_ 296 AEMD_MaxOffset_MCPB_P 0;
BA_ "GenSigTimeoutTime_BPCM" SG_ 296 AEMD_MaxOffset_MCPB_P 0;
BA_ "GenSigStartValue" SG_ 296 AEMD_MaxOffset_MCPB_P 8184;
BA_ "GenSigTimeoutTime_PBWM" SG_ 296 AEMD_MaxOffset_MCPA_P 0;
BA_ "GenSigTimeoutTime_MCPB" SG_ 296 AEMD_MaxOffset_MCPA_P 0;
BA_ "GenSigTimeoutTime_IDCM" SG_ 296 AEMD_MaxOffset_MCPA_P 0;
BA_ "GenSigTimeoutTime_EVCU2" SG_ 296 AEMD_MaxOffset_MCPA_P 0;
BA_ "GenSigTimeoutTime_ECM" SG_ 296 AEMD_MaxOffset_MCPA_P 0;
BA_ "GenSigTimeoutTime_DMPI" SG_ 296 AEMD_MaxOffset_MCPA_P 0;
BA_ "GenSigTimeoutTime_BPCM" SG_ 296 AEMD_MaxOffset_MCPA_P 0;
BA_ "GenSigStartValue" SG_ 296 AEMD_MaxOffset_MCPA_P 8184;
BA_ "GenSigTimeoutTime_PBWM" SG_ 296 AEMD_Cutoff_FreqLow_MCPB_P 0;
BA_ "GenSigTimeoutTime_MCPA" SG_ 296 AEMD_Cutoff_FreqLow_MCPB_P 0;
BA_ "GenSigTimeoutTime_IDCM" SG_ 296 AEMD_Cutoff_FreqLow_MCPB_P 0;
BA_ "GenSigTimeoutTime_EVCU2" SG_ 296 AEMD_Cutoff_FreqLow_MCPB_P 0;
BA_ "GenSigTimeoutTime_ECM" SG_ 296 AEMD_Cutoff_FreqLow_MCPB_P 0;
BA_ "GenSigTimeoutTime_DMPI" SG_ 296 AEMD_Cutoff_FreqLow_MCPB_P 0;
BA_ "GenSigTimeoutTime_BPCM" SG_ 296 AEMD_Cutoff_FreqLow_MCPB_P 0;
BA_ "GenSigTimeoutTime_PBWM" SG_ 297 EVCU_MotorB_Speed 0;
BA_ "GenSigTimeoutTime_MCPA" SG_ 297 EVCU_MotorB_Speed 0;
BA_ "GenSigTimeoutTime_IDCM" SG_ 297 EVCU_MotorB_Speed 0;
BA_ "GenSigTimeoutTime_EVCU2" SG_ 297 EVCU_MotorB_Speed 0;
BA_ "GenSigTimeoutTime_ECM" SG_ 297 EVCU_MotorB_Speed 0;
BA_ "GenSigTimeoutTime_DMPI" SG_ 297 EVCU_MotorB_Speed 0;
BA_ "GenSigTimeoutTime_BPCM" SG_ 297 EVCU_MotorB_Speed 0;
BA_ "GenSigStartValue" SG_ 297 EVCU_MotorB_Speed 32768;
BA_ "GenSigTimeoutTime_PBWM" SG_ 297 EVCU_MotorA_Speed 0;
BA_ "GenSigTimeoutTime_MCPB" SG_ 297 EVCU_MotorA_Speed 0;
BA_ "GenSigTimeoutTime_IDCM" SG_ 297 EVCU_MotorA_Speed 0;
BA_ "GenSigTimeoutTime_EVCU2" SG_ 297 EVCU_MotorA_Speed 0;
BA_ "GenSigTimeoutTime_ECM" SG_ 297 EVCU_MotorA_Speed 0;
BA_ "GenSigTimeoutTime_DMPI" SG_ 297 EVCU_MotorA_Speed 0;
BA_ "GenSigTimeoutTime_BPCM" SG_ 297 EVCU_MotorA_Speed 0;
BA_ "GenSigStartValue" SG_ 297 EVCU_MotorA_Speed 32768;
BA_ "GenSigTimeoutTime_PBWM" SG_ 297 CRC_INVTARGET_PROPULSION2 0;
BA_ "GenSigTimeoutTime_IDCM" SG_ 297 CRC_INVTARGET_PROPULSION2 0;
BA_ "GenSigTimeoutTime_EVCU2" SG_ 297 CRC_INVTARGET_PROPULSION2 0;
BA_ "GenSigTimeoutTime_ECM" SG_ 297 CRC_INVTARGET_PROPULSION2 0;
BA_ "GenSigTimeoutTime_DMPI" SG_ 297 CRC_INVTARGET_PROPULSION2 0;
BA_ "GenSigTimeoutTime_BPCM" SG_ 297 CRC_INVTARGET_PROPULSION2 0;
BA_ "GenSigTimeoutTime_PBWM" SG_ 296 VehicleSpeedVSOSig_P 0;
BA_ "GenSigTimeoutTime_IDCM" SG_ 296 VehicleSpeedVSOSig_P 0;
BA_ "GenSigTimeoutTime_EVCU2" SG_ 296 VehicleSpeedVSOSig_P 0;
BA_ "GenSigTimeoutTime_ECM" SG_ 296 VehicleSpeedVSOSig_P 0;
BA_ "GenSigTimeoutTime_DMPI" SG_ 296 VehicleSpeedVSOSig_P 0;
BA_ "GenSigTimeoutTime_BPCM" SG_ 296 VehicleSpeedVSOSig_P 0;
BA_ "GenSigTimeoutTime_PBWM" SG_ 296 TorqueCommand_MCPB_P 0;
BA_ "GenSigTimeoutTime_MCPA" SG_ 296 TorqueCommand_MCPB_P 0;
BA_ "GenSigTimeoutTime_IDCM" SG_ 296 TorqueCommand_MCPB_P 0;
BA_ "GenSigTimeoutTime_EVCU2" SG_ 296 TorqueCommand_MCPB_P 0;
BA_ "GenSigTimeoutTime_ECM" SG_ 296 TorqueCommand_MCPB_P 0;
BA_ "GenSigTimeoutTime_DMPI" SG_ 296 TorqueCommand_MCPB_P 0;
BA_ "GenSigTimeoutTime_BPCM" SG_ 296 TorqueCommand_MCPB_P 0;
BA_ "GenSigStartValue" SG_ 296 TorqueCommand_MCPB_P 8184;
BA_ "GenSigTimeoutTime_PBWM" SG_ 296 TorqueCommand_MCPA_P 0;
BA_ "GenSigTimeoutTime_MCPB" SG_ 296 TorqueCommand_MCPA_P 0;
BA_ "GenSigTimeoutTime_IDCM" SG_ 296 TorqueCommand_MCPA_P 0;
BA_ "GenSigTimeoutTime_EVCU2" SG_ 296 TorqueCommand_MCPA_P 0;
BA_ "GenSigTimeoutTime_ECM" SG_ 296 TorqueCommand_MCPA_P 0;
BA_ "GenSigTimeoutTime_DMPI" SG_ 296 TorqueCommand_MCPA_P 0;
BA_ "GenSigTimeoutTime_BPCM" SG_ 296 TorqueCommand_MCPA_P 0;
BA_ "GenSigStartValue" SG_ 296 TorqueCommand_MCPA_P 8184;
BA_ "GenSigTimeoutTime_PBWM" SG_ 296 TargetMotorRPM_MCPB_P 0;
BA_ "GenSigTimeoutTime_MCPA" SG_ 296 TargetMotorRPM_MCPB_P 0;
BA_ "GenSigTimeoutTime_IDCM" SG_ 296 TargetMotorRPM_MCPB_P 0;
BA_ "GenSigTimeoutTime_EVCU2" SG_ 296 TargetMotorRPM_MCPB_P 0;
BA_ "GenSigTimeoutTime_ECM" SG_ 296 TargetMotorRPM_MCPB_P 0;
BA_ "GenSigTimeoutTime_DMPI" SG_ 296 TargetMotorRPM_MCPB_P 0;
BA_ "GenSigTimeoutTime_BPCM" SG_ 296 TargetMotorRPM_MCPB_P 0;
BA_ "GenSigStartValue" SG_ 296 TargetMotorRPM_MCPB_P 32768;
BA_ "GenSigTimeoutTime_PBWM" SG_ 296 TargetMotorRPM_MCPA_P 0;
BA_ "GenSigTimeoutTime_MCPB" SG_ 296 TargetMotorRPM_MCPA_P 0;
BA_ "GenSigTimeoutTime_IDCM" SG_ 296 TargetMotorRPM_MCPA_P 0;
BA_ "GenSigTimeoutTime_EVCU2" SG_ 296 TargetMotorRPM_MCPA_P 0;
BA_ "GenSigTimeoutTime_ECM" SG_ 296 TargetMotorRPM_MCPA_P 0;
BA_ "GenSigTimeoutTime_DMPI" SG_ 296 TargetMotorRPM_MCPA_P 0;
BA_ "GenSigTimeoutTime_BPCM" SG_ 296 TargetMotorRPM_MCPA_P 0;
BA_ "GenSigStartValue" SG_ 296 TargetMotorRPM_MCPA_P 32768;
BA_ "GenSigTimeoutTime_PBWM" SG_ 296 ShiftLeverPosition_P 0;
BA_ "GenSigTimeoutTime_MCPA" SG_ 296 ShiftLeverPosition_P 0;
BA_ "GenSigTimeoutTime_PBWM" SG_ 220 VehicleSpeedVSOSig_OBD 0;
BA_ "GenSigTimeoutTime_IDCM" SG_ 220 VehicleSpeedVSOSig_OBD 0;
BA_ "GenSigTimeoutTime_EVCU2" SG_ 220 VehicleSpeedVSOSig_OBD 0;
BA_ "GenSigTimeoutTime_MCPB" SG_ 220 VIN_DATA_OBD 0;
BA_ "GenSigTimeoutTime_MCPA" SG_ 220 VIN_DATA_OBD 0;
BA_ "GenSigTimeoutTime_IDCM" SG_ 220 VIN_DATA_OBD 0;
BA_ "GenSigTimeoutTime_EVCU2" SG_ 220 VIN_DATA_OBD 0;
BA_ "GenSigTimeoutTime_ECM" SG_ 220 VIN_DATA_OBD 0;
BA_ "GenSigTimeoutTime_ECM" SG_ 220 VehicleSpeedVSOSig_OBD 0;
BA_ "GenSigTimeoutTime_PBWM" SG_ 220 EngineSpeed_W_OBD 0;
BA_ "GenSigTimeoutTime_MCPB" SG_ 220 EngineSpeed_W_OBD 0;
BA_ "GenSigTimeoutTime_MCPA" SG_ 220 EngineSpeed_W_OBD 0;
BA_ "GenSigTimeoutTime_IDCM" SG_ 220 EngineSpeed_W_OBD 0;
BA_ "GenSigTimeoutTime_EVCU2" SG_ 220 EngineSpeed_W_OBD 0;
BA_ "GenSigTimeoutTime_ECM" SG_ 220 EngineSpeed_W_OBD 0;
BA_ "GenSigTimeoutTime_PBWM" SG_ 220 EngineSpeedFailSts_W_OBD 0;
BA_ "GenSigTimeoutTime_MCPB" SG_ 220 EngineSpeedFailSts_W_OBD 0;
BA_ "GenSigTimeoutTime_MCPA" SG_ 220 EngineSpeedFailSts_W_OBD 0;
BA_ "GenSigTimeoutTime_IDCM" SG_ 220 EngineSpeedFailSts_W_OBD 0;
BA_ "GenSigTimeoutTime_EVCU2" SG_ 220 EngineSpeedFailSts_W_OBD 0;
BA_ "GenSigTimeoutTime_ECM" SG_ 220 EngineSpeedFailSts_W_OBD 0;
BA_ "GenSigTimeoutTime_BPCM" SG_ 220 EngineSpeedFailSts_W_OBD 0;
BA_ "GenSigTimeoutTime_IDCM" SG_ 220 OperationalModeSts_OBD 0;
BA_ "GenSigTimeoutTime_EVCU2" SG_ 220 OperationalModeSts_OBD 0;
BA_ "GenSigTimeoutTime_MCPB" SG_ 220 TotalOdometer_OBD 0;
BA_ "GenSigTimeoutTime_MCPA" SG_ 220 TotalOdometer_OBD 0;
BA_ "GenSigTimeoutTime_IDCM" SG_ 220 TotalOdometer_OBD 0;
BA_ "GenSigTimeoutTime_EVCU2" SG_ 220 TotalOdometer_OBD 0;
BA_ "GenSigTimeoutTime_ECM" SG_ 220 TotalOdometer_OBD 0;
BA_ "GenSigTimeoutTime_PBWM" SG_ 200 AtmosphericPressure_W_PT 0;
BA_ "GenSigTimeoutTime_MCPB" SG_ 200 AtmosphericPressure_W_PT 0;
BA_ "GenSigTimeoutTime_MCPA" SG_ 200 AtmosphericPressure_W_PT 0;
BA_ "GenSigTimeoutTime_IDCM" SG_ 200 AtmosphericPressure_W_PT 0;
BA_ "GenSigTimeoutTime_EVCU2" SG_ 200 AtmosphericPressure_W_PT 0;
BA_ "GenSigTimeoutTime_ECM" SG_ 200 AtmosphericPressure_W_PT 0;
BA_ "GenSigTimeoutTime_BPCM" SG_ 200 AtmosphericPressure_W_PT 0;
BA_ "GenSigStartValue" SG_ 200 AtmosphericPressure_W_PT 255;
BA_ "GenSigTimeoutTime_PBWM" SG_ 200 AtmosphericPressureFailSts_PT 0;
BA_ "GenSigTimeoutTime_MCPB" SG_ 200 AtmosphericPressureFailSts_PT 0;
BA_ "GenSigTimeoutTime_MCPA" SG_ 200 AtmosphericPressureFailSts_PT 0;
BA_ "GenSigTimeoutTime_IDCM" SG_ 200 AtmosphericPressureFailSts_PT 0;
BA_ "GenSigTimeoutTime_EVCU2" SG_ 200 AtmosphericPressureFailSts_PT 0;
BA_ "GenSigTimeoutTime_ECM" SG_ 200 AtmosphericPressureFailSts_PT 0;
BA_ "GenSigTimeoutTime_BPCM" SG_ 200 AtmosphericPressureFailSts_PT 0;
BA_ "GenSigTimeoutTime_PBWM" SG_ 200 AWDSysStat_PT 0;
BA_ "GenSigTimeoutTime_MCPB" SG_ 200 AWDSysStat_PT 0;
BA_ "GenSigTimeoutTime_MCPA" SG_ 200 AWDSysStat_PT 0;
BA_ "GenSigTimeoutTime_IDCM" SG_ 200 AWDSysStat_PT 0;
BA_ "GenSigTimeoutTime_EVCU2" SG_ 200 AWDSysStat_PT 0;
BA_ "GenSigTimeoutTime_ECM" SG_ 200 AWDSysStat_PT 0;
BA_ "GenSigTimeoutTime_BPCM" SG_ 200 AWDSysStat_PT 0;
BA_ "GenSigStartValue" SG_ 200 AWDSysStat_PT 7;
BA_ "GenSigTimeoutTime_PBWM" SG_ 200 Axle_TorqueStatic_D_TTC_ESC_PT 0;
BA_ "GenSigTimeoutTime_MCPB" SG_ 200 Axle_TorqueStatic_D_TTC_ESC_PT 0;
BA_ "GenSigTimeoutTime_MCPA" SG_ 200 Axle_TorqueStatic_D_TTC_ESC_PT 0;
BA_ "GenSigTimeoutTime_IDCM" SG_ 200 Axle_TorqueStatic_D_TTC_ESC_PT 0;
BA_ "GenSigTimeoutTime_EVCU2" SG_ 200 Axle_TorqueStatic_D_TTC_ESC_PT 0;
BA_ "GenSigTimeoutTime_ECM" SG_ 200 Axle_TorqueStatic_D_TTC_ESC_PT 0;
BA_ "GenSigTimeoutTime_BPCM" SG_ 200 Axle_TorqueStatic_D_TTC_ESC_PT 0;
BA_ "GenSigStartValue" SG_ 200 Axle_TorqueStatic_D_TTC_ESC_PT 32767;
BA_ "GenSigTimeoutTime_PBWM" SG_ 200 Axle_TorqueStatic_D_TTC_PT 0;
BA_ "GenSigTimeoutTime_MCPB" SG_ 200 Axle_TorqueStatic_D_TTC_PT 0;
BA_ "GenSigTimeoutTime_MCPA" SG_ 200 Axle_TorqueStatic_D_TTC_PT 0;
BA_ "GenSigTimeoutTime_IDCM" SG_ 200 Axle_TorqueStatic_D_TTC_PT 0;
BA_ "GenSigTimeoutTime_EVCU2" SG_ 200 Axle_TorqueStatic_D_TTC_PT 0;
BA_ "GenSigTimeoutTime_ECM" SG_ 200 Axle_TorqueStatic_D_TTC_PT 0;
BA_ "GenSigTimeoutTime_BPCM" SG_ 200 Axle_TorqueStatic_D_TTC_PT 0;
BA_ "GenSigStartValue" SG_ 200 Axle_TorqueStatic_D_TTC_PT 32767;
BA_ "GenSigTimeoutTime_PBWM" SG_ 200 ESCActive_PT 0;
BA_ "GenSigTimeoutTime_MCPB" SG_ 200 ESCActive_PT 0;
BA_ "GenSigTimeoutTime_MCPA" SG_ 200 ESCActive_PT 0;
BA_ "GenSigTimeoutTime_IDCM" SG_ 200 ESCActive_PT 0;
BA_ "GenSigTimeoutTime_EVCU2" SG_ 200 ESCActive_PT 0;
BA_ "GenSigTimeoutTime_ECM" SG_ 200 ESCActive_PT 0;
BA_ "GenSigTimeoutTime_BPCM" SG_ 200 ESCActive_PT 0;
BA_ "GenSigTimeoutTime_PBWM" SG_ 200 Ft_RrCouplingTrq_Actual_PT 0;
BA_ "GenSigTimeoutTime_MCPB" SG_ 200 Ft_RrCouplingTrq_Actual_PT 0;
BA_ "GenSigTimeoutTime_MCPA" SG_ 200 Ft_RrCouplingTrq_Actual_PT 0;
BA_ "GenSigTimeoutTime_IDCM" SG_ 200 Ft_RrCouplingTrq_Actual_PT 0;
BA_ "GenSigTimeoutTime_EVCU2" SG_ 200 Ft_RrCouplingTrq_Actual_PT 0;
BA_ "GenSigTimeoutTime_ECM" SG_ 200 Ft_RrCouplingTrq_Actual_PT 0;
BA_ "GenSigTimeoutTime_BPCM" SG_ 200 Ft_RrCouplingTrq_Actual_PT 0;
BA_ "GenSigStartValue" SG_ 200 Ft_RrCouplingTrq_Actual_PT 255;
BA_ "GenSigTimeoutTime_PBWM" SG_ 200 Ft_RrCouplingTrq_Desired_PT 0;
BA_ "GenSigTimeoutTime_MCPB" SG_ 200 Ft_RrCouplingTrq_Desired_PT 0;
BA_ "GenSigTimeoutTime_MCPA" SG_ 200 Ft_RrCouplingTrq_Desired_PT 0;
BA_ "GenSigTimeoutTime_IDCM" SG_ 200 Ft_RrCouplingTrq_Desired_PT 0;
BA_ "GenSigTimeoutTime_EVCU2" SG_ 200 Ft_RrCouplingTrq_Desired_PT 0;
BA_ "GenSigTimeoutTime_ECM" SG_ 200 Ft_RrCouplingTrq_Desired_PT 0;
BA_ "GenSigTimeoutTime_BPCM" SG_ 200 Ft_RrCouplingTrq_Desired_PT 0;
BA_ "GenSigStartValue" SG_ 200 Ft_RrCouplingTrq_Desired_PT 255;
BA_ "GenSigTimeoutTime_PBWM" SG_ 200 LHF_WheelSensorFailSts_PT 0;
BA_ "GenSigTimeoutTime_MCPB" SG_ 200 LHF_WheelSensorFailSts_PT 0;
BA_ "GenSigTimeoutTime_MCPA" SG_ 200 LHF_WheelSensorFailSts_PT 0;
BA_ "GenSigTimeoutTime_IDCM" SG_ 200 LHF_WheelSensorFailSts_PT 0;
BA_ "GenSigTimeoutTime_EVCU2" SG_ 200 LHF_WheelSensorFailSts_PT 0;
BA_ "GenSigTimeoutTime_ECM" SG_ 200 LHF_WheelSensorFailSts_PT 0;
BA_ "GenSigTimeoutTime_BPCM" SG_ 200 LHF_WheelSensorFailSts_PT 0;
BA_ "GenSigTimeoutTime_PBWM" SG_ 200 LHFWheelSpeed_PT 0;
BA_ "GenSigTimeoutTime_MCPB" SG_ 200 LHFWheelSpeed_PT 0;
BA_ "GenSigTimeoutTime_MCPA" SG_ 200 LHFWheelSpeed_PT 0;
BA_ "GenSigTimeoutTime_IDCM" SG_ 200 LHFWheelSpeed_PT 0;
BA_ "GenSigTimeoutTime_EVCU2" SG_ 200 LHFWheelSpeed_PT 0;
BA_ "GenSigTimeoutTime_ECM" SG_ 200 LHFWheelSpeed_PT 0;
BA_ "GenSigTimeoutTime_BPCM" SG_ 200 LHFWheelSpeed_PT 0;
BA_ "GenSigTimeoutTime_PBWM" SG_ 200 RHF_WheelSensorFailSts_PT 0;
BA_ "GenSigTimeoutTime_MCPB" SG_ 200 RHF_WheelSensorFailSts_PT 0;
BA_ "GenSigTimeoutTime_MCPA" SG_ 200 RHF_WheelSensorFailSts_PT 0;
BA_ "GenSigTimeoutTime_IDCM" SG_ 200 RHF_WheelSensorFailSts_PT 0;
BA_ "GenSigTimeoutTime_EVCU2" SG_ 200 RHF_WheelSensorFailSts_PT 0;
BA_ "GenSigTimeoutTime_ECM" SG_ 200 RHF_WheelSensorFailSts_PT 0;
BA_ "GenSigTimeoutTime_BPCM" SG_ 200 RHF_WheelSensorFailSts_PT 0;
BA_ "GenSigTimeoutTime_PBWM" SG_ 200 RHFWheelSpeed_PT 0;
BA_ "GenSigTimeoutTime_MCPB" SG_ 200 RHFWheelSpeed_PT 0;
BA_ "GenSigTimeoutTime_MCPA" SG_ 200 RHFWheelSpeed_PT 0;
BA_ "GenSigTimeoutTime_IDCM" SG_ 200 RHFWheelSpeed_PT 0;
BA_ "GenSigTimeoutTime_EVCU2" SG_ 200 RHFWheelSpeed_PT 0;
BA_ "GenSigTimeoutTime_ECM" SG_ 200 RHFWheelSpeed_PT 0;
BA_ "GenSigTimeoutTime_BPCM" SG_ 200 RHFWheelSpeed_PT 0;
BA_ "GenSigTimeoutTime_PBWM" SG_ 200 Total_AxleTorque_Static_PT 0;
BA_ "GenSigTimeoutTime_MCPB" SG_ 200 Total_AxleTorque_Static_PT 0;
BA_ "GenSigTimeoutTime_MCPA" SG_ 200 Total_AxleTorque_Static_PT 0;
BA_ "GenSigTimeoutTime_IDCM" SG_ 200 Total_AxleTorque_Static_PT 0;
BA_ "GenSigTimeoutTime_EVCU2" SG_ 200 Total_AxleTorque_Static_PT 0;
BA_ "GenSigTimeoutTime_ECM" SG_ 200 Total_AxleTorque_Static_PT 0;
BA_ "GenSigTimeoutTime_BPCM" SG_ 200 Total_AxleTorque_Static_PT 0;
BA_ "GenSigStartValue" SG_ 200 Total_AxleTorque_Static_PT 32767;
BA_ "GenSigTimeoutTime_PBWM" SG_ 200 TotalAxle_Max_Rq_BSM_PT 0;
BA_ "GenSigTimeoutTime_MCPB" SG_ 200 TotalAxle_Max_Rq_BSM_PT 0;
BA_ "GenSigTimeoutTime_MCPA" SG_ 200 TotalAxle_Max_Rq_BSM_PT 0;
BA_ "GenSigTimeoutTime_IDCM" SG_ 200 TotalAxle_Max_Rq_BSM_PT 0;
BA_ "GenSigTimeoutTime_EVCU2" SG_ 200 TotalAxle_Max_Rq_BSM_PT 0;
BA_ "GenSigTimeoutTime_ECM" SG_ 200 TotalAxle_Max_Rq_BSM_PT 0;
BA_ "GenSigTimeoutTime_BPCM" SG_ 200 TotalAxle_Max_Rq_BSM_PT 0;
BA_ "GenSigTimeoutTime_PBWM" SG_ 200 TotalAxle_Min_Rq_BSM_PT 0;
BA_ "GenSigTimeoutTime_MCPB" SG_ 200 TotalAxle_Min_Rq_BSM_PT 0;
BA_ "GenSigTimeoutTime_MCPA" SG_ 200 TotalAxle_Min_Rq_BSM_PT 0;
BA_ "GenSigTimeoutTime_IDCM" SG_ 200 TotalAxle_Min_Rq_BSM_PT 0;
BA_ "GenSigTimeoutTime_EVCU2" SG_ 200 TotalAxle_Min_Rq_BSM_PT 0;
BA_ "GenSigTimeoutTime_ECM" SG_ 200 TotalAxle_Min_Rq_BSM_PT 0;
BA_ "GenSigTimeoutTime_BPCM" SG_ 200 TotalAxle_Min_Rq_BSM_PT 0;
BA_ "GenSigTimeoutTime_PBWM" SG_ 200 TotalAxle_Rq_BSM_PT 0;
BA_ "GenSigTimeoutTime_MCPB" SG_ 200 TotalAxle_Rq_BSM_PT 0;
BA_ "GenSigTimeoutTime_MCPA" SG_ 200 TotalAxle_Rq_BSM_PT 0;
BA_ "GenSigTimeoutTime_IDCM" SG_ 200 TotalAxle_Rq_BSM_PT 0;
BA_ "GenSigTimeoutTime_EVCU2" SG_ 200 TotalAxle_Rq_BSM_PT 0;
BA_ "GenSigTimeoutTime_ECM" SG_ 200 TotalAxle_Rq_BSM_PT 0;
BA_ "GenSigTimeoutTime_BPCM" SG_ 200 TotalAxle_Rq_BSM_PT 0;
BA_ "GenSigStartValue" SG_ 200 TotalAxle_Rq_BSM_PT 32767;
BA_ "GenSigTimeoutTime_IDCM" SG_ 220 CmdIgnSts_OBD 0;
BA_ "GenSigTimeoutTime_EVCU2" SG_ 220 CmdIgnSts_OBD 0;
BA_ "GenSigTimeoutTime_PBWM" SG_ 220 MessageCounter_PT_SYSTEM_FD_OBD 0;
BA_ "GenSigTimeoutTime_MCPB" SG_ 220 MessageCounter_PT_SYSTEM_FD_OBD 0;
BA_ "GenSigTimeoutTime_MCPA" SG_ 220 MessageCounter_PT_SYSTEM_FD_OBD 0;
BA_ "GenSigTimeoutTime_IDCM" SG_ 220 MessageCounter_PT_SYSTEM_FD_OBD 0;
BA_ "GenSigTimeoutTime_EVCU2" SG_ 220 MessageCounter_PT_SYSTEM_FD_OBD 0;
BA_ "GenSigTimeoutTime_PBWM" SG_ 220 CRC_PT_SYSTEM_FD_OBD 0;
BA_ "GenSigTimeoutTime_MCPB" SG_ 220 CRC_PT_SYSTEM_FD_OBD 0;
BA_ "GenSigTimeoutTime_MCPA" SG_ 220 CRC_PT_SYSTEM_FD_OBD 0;
BA_ "GenSigTimeoutTime_IDCM" SG_ 220 CRC_PT_SYSTEM_FD_OBD 0;
BA_ "GenSigTimeoutTime_EVCU2" SG_ 220 CRC_PT_SYSTEM_FD_OBD 0;
BA_ "GenSigTimeoutTime_PBWM" SG_ 200 CRC_PT_SYSTEM_FD_4 0;
BA_ "GenSigTimeoutTime_MCPB" SG_ 200 CRC_PT_SYSTEM_FD_4 0;
BA_ "GenSigTimeoutTime_MCPA" SG_ 200 CRC_PT_SYSTEM_FD_4 0;
BA_ "GenSigTimeoutTime_IDCM" SG_ 200 CRC_PT_SYSTEM_FD_4 0;
BA_ "GenSigTimeoutTime_EVCU2" SG_ 200 CRC_PT_SYSTEM_FD_4 0;
BA_ "GenSigTimeoutTime_ECM" SG_ 200 CRC_PT_SYSTEM_FD_4 0;
BA_ "GenSigTimeoutTime_BPCM" SG_ 200 CRC_PT_SYSTEM_FD_4 0;
BA_ "GenSigTimeoutTime_PBWM" SG_ 200 MessageCounter_PT_SYSTEM_FD_4 0;
BA_ "GenSigTimeoutTime_MCPB" SG_ 200 MessageCounter_PT_SYSTEM_FD_4 0;
BA_ "GenSigTimeoutTime_MCPA" SG_ 200 MessageCounter_PT_SYSTEM_FD_4 0;
BA_ "GenSigTimeoutTime_IDCM" SG_ 200 MessageCounter_PT_SYSTEM_FD_4 0;
BA_ "GenSigTimeoutTime_EVCU2" SG_ 200 MessageCounter_PT_SYSTEM_FD_4 0;
BA_ "GenSigTimeoutTime_ECM" SG_ 200 MessageCounter_PT_SYSTEM_FD_4 0;
BA_ "GenSigTimeoutTime_BPCM" SG_ 200 MessageCounter_PT_SYSTEM_FD_4 0;
BA_ "GenSigTimeoutTime_PBWM" SG_ 2654486594 CBV_bit7 0;
BA_ "GenSigTimeoutTime_MCPB" SG_ 2654486594 CBV_bit7 0;
BA_ "GenSigTimeoutTime_MCPA" SG_ 2654486594 CBV_bit7 0;
BA_ "GenSigTimeoutTime_IDCM" SG_ 2654486594 CBV_bit7 0;
BA_ "GenSigTimeoutTime_EVCU2" SG_ 2654486594 CBV_bit7 0;
BA_ "GenSigTimeoutTime_ECM" SG_ 2654486594 CBV_bit7 0;
BA_ "GenSigTimeoutTime_DMPI" SG_ 2654486594 CBV_bit7 0;
BA_ "GenSigTimeoutTime_BPCM" SG_ 2654486594 CBV_bit7 0;
BA_ "GenSigTimeoutTime_PBWM" SG_ 2654486594 SourceNodeIdentifier 0;
BA_ "GenSigTimeoutTime_MCPB" SG_ 2654486594 SourceNodeIdentifier 0;
BA_ "GenSigTimeoutTime_MCPA" SG_ 2654486594 SourceNodeIdentifier 0;
BA_ "GenSigTimeoutTime_IDCM" SG_ 2654486594 SourceNodeIdentifier 0;
BA_ "GenSigTimeoutTime_EVCU2" SG_ 2654486594 SourceNodeIdentifier 0;
BA_ "GenSigTimeoutTime_ECM" SG_ 2654486594 SourceNodeIdentifier 0;
BA_ "GenSigTimeoutTime_DMPI" SG_ 2654486594 SourceNodeIdentifier 0;
BA_ "GenSigTimeoutTime_BPCM" SG_ 2654486594 SourceNodeIdentifier 0;
BA_ "GenSigTimeoutTime_PBWM" SG_ 2654486594 CBV_bit5 0;
BA_ "GenSigTimeoutTime_MCPB" SG_ 2654486594 CBV_bit5 0;
BA_ "GenSigTimeoutTime_MCPA" SG_ 2654486594 CBV_bit5 0;
BA_ "GenSigTimeoutTime_IDCM" SG_ 2654486594 CBV_bit5 0;
BA_ "GenSigTimeoutTime_EVCU2" SG_ 2654486594 CBV_bit5 0;
BA_ "GenSigTimeoutTime_ECM" SG_ 2654486594 CBV_bit5 0;
BA_ "GenSigTimeoutTime_DMPI" SG_ 2654486594 CBV_bit5 0;
BA_ "GenSigTimeoutTime_BPCM" SG_ 2654486594 CBV_bit5 0;
BA_ "GenSigTimeoutTime_PBWM" SG_ 2654486594 CBV_bit6_PartialNtwInfBit 0;
BA_ "GenSigTimeoutTime_MCPB" SG_ 2654486594 CBV_bit6_PartialNtwInfBit 0;
BA_ "GenSigTimeoutTime_MCPA" SG_ 2654486594 CBV_bit6_PartialNtwInfBit 0;
BA_ "GenSigTimeoutTime_IDCM" SG_ 2654486594 CBV_bit6_PartialNtwInfBit 0;
BA_ "GenSigTimeoutTime_EVCU2" SG_ 2654486594 CBV_bit6_PartialNtwInfBit 0;
BA_ "GenSigTimeoutTime_ECM" SG_ 2654486594 CBV_bit6_PartialNtwInfBit 0;
BA_ "GenSigTimeoutTime_DMPI" SG_ 2654486594 CBV_bit6_PartialNtwInfBit 0;
BA_ "GenSigTimeoutTime_BPCM" SG_ 2654486594 CBV_bit6_PartialNtwInfBit 0;
BA_ "GenSigTimeoutTime_PBWM" SG_ 2654486594 CBV_bit3_NMCoordinatorBit 0;
BA_ "GenSigTimeoutTime_MCPB" SG_ 2654486594 CBV_bit3_NMCoordinatorBit 0;
BA_ "GenSigTimeoutTime_MCPA" SG_ 2654486594 CBV_bit3_NMCoordinatorBit 0;
BA_ "GenSigTimeoutTime_IDCM" SG_ 2654486594 CBV_bit3_NMCoordinatorBit 0;
BA_ "GenSigTimeoutTime_EVCU2" SG_ 2654486594 CBV_bit3_NMCoordinatorBit 0;
BA_ "GenSigTimeoutTime_ECM" SG_ 2654486594 CBV_bit3_NMCoordinatorBit 0;
BA_ "GenSigTimeoutTime_DMPI" SG_ 2654486594 CBV_bit3_NMCoordinatorBit 0;
BA_ "GenSigTimeoutTime_BPCM" SG_ 2654486594 CBV_bit3_NMCoordinatorBit 0;
BA_ "GenSigTimeoutTime_PBWM" SG_ 2654486594 CBV_bit4_ActiveWakeupBit 0;
BA_ "GenSigTimeoutTime_MCPB" SG_ 2654486594 CBV_bit4_ActiveWakeupBit 0;
BA_ "GenSigTimeoutTime_MCPA" SG_ 2654486594 CBV_bit4_ActiveWakeupBit 0;
BA_ "GenSigTimeoutTime_IDCM" SG_ 2654486594 CBV_bit4_ActiveWakeupBit 0;
BA_ "GenSigTimeoutTime_EVCU2" SG_ 2654486594 CBV_bit4_ActiveWakeupBit 0;
BA_ "GenSigTimeoutTime_ECM" SG_ 2654486594 CBV_bit4_ActiveWakeupBit 0;
BA_ "GenSigTimeoutTime_DMPI" SG_ 2654486594 CBV_bit4_ActiveWakeupBit 0;
BA_ "GenSigTimeoutTime_BPCM" SG_ 2654486594 CBV_bit4_ActiveWakeupBit 0;
BA_ "GenSigTimeoutTime_PBWM" SG_ 2654486594 CBV_bit1 0;
BA_ "GenSigTimeoutTime_MCPB" SG_ 2654486594 CBV_bit1 0;
BA_ "GenSigTimeoutTime_MCPA" SG_ 2654486594 CBV_bit1 0;
BA_ "GenSigTimeoutTime_IDCM" SG_ 2654486594 CBV_bit1 0;
BA_ "GenSigTimeoutTime_EVCU2" SG_ 2654486594 CBV_bit1 0;
BA_ "GenSigTimeoutTime_ECM" SG_ 2654486594 CBV_bit1 0;
BA_ "GenSigTimeoutTime_DMPI" SG_ 2654486594 CBV_bit1 0;
BA_ "GenSigTimeoutTime_BPCM" SG_ 2654486594 CBV_bit1 0;
BA_ "GenSigTimeoutTime_PBWM" SG_ 2654486594 CBV_bit2 0;
BA_ "GenSigTimeoutTime_MCPB" SG_ 2654486594 CBV_bit2 0;
BA_ "GenSigTimeoutTime_MCPA" SG_ 2654486594 CBV_bit2 0;
BA_ "GenSigTimeoutTime_IDCM" SG_ 2654486594 CBV_bit2 0;
BA_ "GenSigTimeoutTime_EVCU2" SG_ 2654486594 CBV_bit2 0;
BA_ "GenSigTimeoutTime_ECM" SG_ 2654486594 CBV_bit2 0;
BA_ "GenSigTimeoutTime_DMPI" SG_ 2654486594 CBV_bit2 0;
BA_ "GenSigTimeoutTime_BPCM" SG_ 2654486594 CBV_bit2 0;
BA_ "GenSigTimeoutTime_PBWM" SG_ 2654486594 CBV_bit0_RepeatMessageRequestBit 0;
BA_ "GenSigTimeoutTime_MCPB" SG_ 2654486594 CBV_bit0_RepeatMessageRequestBit 0;
BA_ "GenSigTimeoutTime_MCPA" SG_ 2654486594 CBV_bit0_RepeatMessageRequestBit 0;
BA_ "GenSigTimeoutTime_IDCM" SG_ 2654486594 CBV_bit0_RepeatMessageRequestBit 0;
BA_ "GenSigTimeoutTime_EVCU2" SG_ 2654486594 CBV_bit0_RepeatMessageRequestBit 0;
BA_ "GenSigTimeoutTime_ECM" SG_ 2654486594 CBV_bit0_RepeatMessageRequestBit 0;
BA_ "GenSigTimeoutTime_DMPI" SG_ 2654486594 CBV_bit0_RepeatMessageRequestBit 0;
BA_ "GenSigTimeoutTime_BPCM" SG_ 2654486594 CBV_bit0_RepeatMessageRequestBit 0;
BA_ "GenSigTimeoutTime_PBWM" SG_ 294 MCPB_MtrMinCpbltyTrq_P 0;
BA_ "GenSigTimeoutTime_MCPB" SG_ 294 MCPB_MtrMinCpbltyTrq_P 0;
BA_ "GenSigTimeoutTime_MCPA" SG_ 294 MCPB_MtrMinCpbltyTrq_P 0;
BA_ "GenSigTimeoutTime_IDCM" SG_ 294 MCPB_MtrMinCpbltyTrq_P 0;
BA_ "GenSigTimeoutTime_ECM" SG_ 294 MCPB_MtrMinCpbltyTrq_P 0;
BA_ "GenSigTimeoutTime_DMPI" SG_ 294 MCPB_MtrMinCpbltyTrq_P 0;
BA_ "GenSigTimeoutTime_BPCM" SG_ 294 MCPB_MtrMinCpbltyTrq_P 0;
BA_ "GenSigStartValue" SG_ 294 MCPB_MtrMinCpbltyTrq_P 8184;
BA_ "GenSigTimeoutTime_PBWM" SG_ 294 MCPB_RPM_P 0;
BA_ "GenSigTimeoutTime_MCPB" SG_ 294 MCPB_RPM_P 0;
BA_ "GenSigTimeoutTime_MCPA" SG_ 294 MCPB_RPM_P 0;
BA_ "GenSigTimeoutTime_IDCM" SG_ 294 MCPB_RPM_P 0;
BA_ "GenSigTimeoutTime_ECM" SG_ 294 MCPB_RPM_P 0;
BA_ "GenSigTimeoutTime_DMPI" SG_ 294 MCPB_RPM_P 0;
BA_ "GenSigTimeoutTime_BPCM" SG_ 294 MCPB_RPM_P 0;
BA_ "GenSigStartValue" SG_ 294 MCPB_RPM_P 32768;
BA_ "GenSigTimeoutTime_PBWM" SG_ 294 MCPB_RPM_V_P 0;
BA_ "GenSigTimeoutTime_MCPB" SG_ 294 MCPB_RPM_V_P 0;
BA_ "GenSigTimeoutTime_MCPA" SG_ 294 MCPB_RPM_V_P 0;
BA_ "GenSigTimeoutTime_IDCM" SG_ 294 MCPB_RPM_V_P 0;
BA_ "GenSigTimeoutTime_ECM" SG_ 294 MCPB_RPM_V_P 0;
BA_ "GenSigTimeoutTime_DMPI" SG_ 294 MCPB_RPM_V_P 0;
BA_ "GenSigTimeoutTime_BPCM" SG_ 294 MCPB_RPM_V_P 0;
BA_ "GenSigTimeoutTime_ECM" SG_ 294 MCPB_Spd_Lim_P 0;
BA_ "GenSigTimeoutTime_DMPI" SG_ 294 MCPB_Spd_Lim_P 0;
BA_ "GenSigTimeoutTime_BPCM" SG_ 294 MCPB_Spd_Lim_P 0;
BA_ "GenSigTimeoutTime_PBWM" SG_ 294 MCPB_Spd_Lim_P 0;
BA_ "GenSigTimeoutTime_MCPB" SG_ 294 MCPB_Spd_Lim_P 0;
BA_ "GenSigTimeoutTime_MCPA" SG_ 294 MCPB_Spd_Lim_P 0;
BA_ "GenSigTimeoutTime_IDCM" SG_ 294 MCPB_Spd_Lim_P 0;
BA_ "GenSigTimeoutTime_PBWM" SG_ 294 MCPB_SPT_Stat_P 0;
BA_ "GenSigTimeoutTime_MCPB" SG_ 294 MCPB_SPT_Stat_P 0;
BA_ "GenSigTimeoutTime_MCPA" SG_ 294 MCPB_SPT_Stat_P 0;
BA_ "GenSigTimeoutTime_IDCM" SG_ 294 MCPB_SPT_Stat_P 0;
BA_ "GenSigTimeoutTime_ECM" SG_ 294 MCPB_SPT_Stat_P 0;
BA_ "GenSigTimeoutTime_DMPI" SG_ 294 MCPB_SPT_Stat_P 0;
BA_ "GenSigTimeoutTime_BPCM" SG_ 294 MCPB_SPT_Stat_P 0;
BA_ "GenSigTimeoutTime_PBWM" SG_ 294 MCPB_TorqAchieved_AEMD_P 0;
BA_ "GenSigTimeoutTime_MCPB" SG_ 294 MCPB_TorqAchieved_AEMD_P 0;
BA_ "GenSigTimeoutTime_MCPA" SG_ 294 MCPB_TorqAchieved_AEMD_P 0;
BA_ "GenSigTimeoutTime_IDCM" SG_ 294 MCPB_TorqAchieved_AEMD_P 0;
BA_ "GenSigTimeoutTime_ECM" SG_ 294 MCPB_TorqAchieved_AEMD_P 0;
BA_ "GenSigTimeoutTime_DMPI" SG_ 294 MCPB_TorqAchieved_AEMD_P 0;
BA_ "GenSigTimeoutTime_BPCM" SG_ 294 MCPB_TorqAchieved_AEMD_P 0;
BA_ "GenSigStartValue" SG_ 294 MCPB_TorqAchieved_AEMD_P 8184;
BA_ "GenSigTimeoutTime_PBWM" SG_ 294 MCPB_TorqAchieved_AEMD_V_P 0;
BA_ "GenSigTimeoutTime_MCPB" SG_ 294 MCPB_TorqAchieved_AEMD_V_P 0;
BA_ "GenSigTimeoutTime_MCPA" SG_ 294 MCPB_TorqAchieved_AEMD_V_P 0;
BA_ "GenSigTimeoutTime_IDCM" SG_ 294 MCPB_TorqAchieved_AEMD_V_P 0;
BA_ "GenSigTimeoutTime_ECM" SG_ 294 MCPB_TorqAchieved_AEMD_V_P 0;
BA_ "GenSigTimeoutTime_DMPI" SG_ 294 MCPB_TorqAchieved_AEMD_V_P 0;
BA_ "GenSigTimeoutTime_BPCM" SG_ 294 MCPB_TorqAchieved_AEMD_V_P 0;
BA_ "GenSigTimeoutTime_PBWM" SG_ 294 MCPB_Torque_Achieved_P 0;
BA_ "GenSigTimeoutTime_MCPB" SG_ 294 MCPB_Torque_Achieved_P 0;
BA_ "GenSigTimeoutTime_MCPA" SG_ 294 MCPB_Torque_Achieved_P 0;
BA_ "GenSigTimeoutTime_IDCM" SG_ 294 MCPB_Torque_Achieved_P 0;
BA_ "GenSigTimeoutTime_ECM" SG_ 294 MCPB_Torque_Achieved_P 0;
BA_ "GenSigTimeoutTime_DMPI" SG_ 294 MCPB_Torque_Achieved_P 0;
BA_ "GenSigTimeoutTime_BPCM" SG_ 294 MCPB_Torque_Achieved_P 0;
BA_ "GenSigStartValue" SG_ 294 MCPB_Torque_Achieved_P 8184;
BA_ "GenSigTimeoutTime_PBWM" SG_ 294 MCPB_Torque_Achieved_V_P 0;
BA_ "GenSigTimeoutTime_MCPB" SG_ 294 MCPB_Torque_Achieved_V_P 0;
BA_ "GenSigTimeoutTime_MCPA" SG_ 294 MCPB_Torque_Achieved_V_P 0;
BA_ "GenSigTimeoutTime_IDCM" SG_ 294 MCPB_Torque_Achieved_V_P 0;
BA_ "GenSigTimeoutTime_ECM" SG_ 294 MCPB_Torque_Achieved_V_P 0;
BA_ "GenSigTimeoutTime_DMPI" SG_ 294 MCPB_Torque_Achieved_V_P 0;
BA_ "GenSigTimeoutTime_BPCM" SG_ 294 MCPB_Torque_Achieved_V_P 0;
BA_ "GenSigTimeoutTime_PBWM" SG_ 294 MPR_PosSensor_P 0;
BA_ "GenSigTimeoutTime_MCPB" SG_ 294 MPR_PosSensor_P 0;
BA_ "GenSigTimeoutTime_MCPA" SG_ 294 MPR_PosSensor_P 0;
BA_ "GenSigTimeoutTime_IDCM" SG_ 294 MPR_PosSensor_P 0;
BA_ "GenSigTimeoutTime_ECM" SG_ 294 MPR_PosSensor_P 0;
BA_ "GenSigTimeoutTime_DMPI" SG_ 294 MPR_PosSensor_P 0;
BA_ "GenSigTimeoutTime_BPCM" SG_ 294 MPR_PosSensor_P 0;
BA_ "GenSigTimeoutTime_PBWM" SG_ 294 Plock_fdbk_sts_P 0;
BA_ "GenSigTimeoutTime_MCPB" SG_ 294 Plock_fdbk_sts_P 0;
BA_ "GenSigTimeoutTime_MCPA" SG_ 294 Plock_fdbk_sts_P 0;
BA_ "GenSigTimeoutTime_IDCM" SG_ 294 Plock_fdbk_sts_P 0;
BA_ "GenSigTimeoutTime_ECM" SG_ 294 Plock_fdbk_sts_P 0;
BA_ "GenSigTimeoutTime_DMPI" SG_ 294 Plock_fdbk_sts_P 0;
BA_ "GenSigTimeoutTime_BPCM" SG_ 294 Plock_fdbk_sts_P 0;
BA_ "GenSigTimeoutTime_PBWM" SG_ 294 Plock_MotorPosSts_P 0;
BA_ "GenSigTimeoutTime_MCPB" SG_ 294 Plock_MotorPosSts_P 0;
BA_ "GenSigTimeoutTime_MCPA" SG_ 294 Plock_MotorPosSts_P 0;
BA_ "GenSigTimeoutTime_IDCM" SG_ 294 Plock_MotorPosSts_P 0;
BA_ "GenSigTimeoutTime_ECM" SG_ 294 Plock_MotorPosSts_P 0;
BA_ "GenSigTimeoutTime_DMPI" SG_ 294 Plock_MotorPosSts_P 0;
BA_ "GenSigTimeoutTime_BPCM" SG_ 294 Plock_MotorPosSts_P 0;
BA_ "GenSigTimeoutTime_PBWM" SG_ 294 Plock_PosSensor_P 0;
BA_ "GenSigTimeoutTime_MCPB" SG_ 294 Plock_PosSensor_P 0;
BA_ "GenSigTimeoutTime_MCPA" SG_ 294 Plock_PosSensor_P 0;
BA_ "GenSigTimeoutTime_IDCM" SG_ 294 Plock_PosSensor_P 0;
BA_ "GenSigTimeoutTime_ECM" SG_ 294 Plock_PosSensor_P 0;
BA_ "GenSigTimeoutTime_DMPI" SG_ 294 Plock_PosSensor_P 0;
BA_ "GenSigTimeoutTime_BPCM" SG_ 294 Plock_PosSensor_P 0;
BA_ "GenSigTimeoutTime_PBWM" SG_ 294 PlockFailSts_P 0;
BA_ "GenSigTimeoutTime_MCPB" SG_ 294 PlockFailSts_P 0;
BA_ "GenSigTimeoutTime_MCPA" SG_ 294 PlockFailSts_P 0;
BA_ "GenSigTimeoutTime_IDCM" SG_ 294 PlockFailSts_P 0;
BA_ "GenSigTimeoutTime_ECM" SG_ 294 PlockFailSts_P 0;
BA_ "GenSigTimeoutTime_DMPI" SG_ 294 PlockFailSts_P 0;
BA_ "GenSigTimeoutTime_BPCM" SG_ 294 PlockFailSts_P 0;
BA_ "GenSigTimeoutTime_PBWM" SG_ 504 CRC_MCPB_STATUS 0;
BA_ "GenSigTimeoutTime_MCPB" SG_ 504 CRC_MCPB_STATUS 0;
BA_ "GenSigTimeoutTime_MCPA" SG_ 504 CRC_MCPB_STATUS 0;
BA_ "GenSigTimeoutTime_IDCM" SG_ 504 CRC_MCPB_STATUS 0;
BA_ "GenSigTimeoutTime_ECM" SG_ 504 CRC_MCPB_STATUS 0;
BA_ "GenSigTimeoutTime_DMPI" SG_ 504 CRC_MCPB_STATUS 0;
BA_ "GenSigTimeoutTime_BPCM" SG_ 504 CRC_MCPB_STATUS 0;
BA_ "GenSigTimeoutTime_PBWM" SG_ 504 MC_MCPB_STATUS 0;
BA_ "GenSigTimeoutTime_MCPB" SG_ 504 MC_MCPB_STATUS 0;
BA_ "GenSigTimeoutTime_MCPA" SG_ 504 MC_MCPB_STATUS 0;
BA_ "GenSigTimeoutTime_IDCM" SG_ 504 MC_MCPB_STATUS 0;
BA_ "GenSigTimeoutTime_ECM" SG_ 504 MC_MCPB_STATUS 0;
BA_ "GenSigTimeoutTime_DMPI" SG_ 504 MC_MCPB_STATUS 0;
BA_ "GenSigTimeoutTime_BPCM" SG_ 504 MC_MCPB_STATUS 0;
BA_ "GenSigTimeoutTime_PBWM" SG_ 504 MCPB_CoolantTemp_P 0;
BA_ "GenSigTimeoutTime_MCPB" SG_ 504 MCPB_CoolantTemp_P 0;
BA_ "GenSigTimeoutTime_MCPA" SG_ 504 MCPB_CoolantTemp_P 0;
BA_ "GenSigTimeoutTime_IDCM" SG_ 504 MCPB_CoolantTemp_P 0;
BA_ "GenSigTimeoutTime_ECM" SG_ 504 MCPB_CoolantTemp_P 0;
BA_ "GenSigTimeoutTime_DMPI" SG_ 504 MCPB_CoolantTemp_P 0;
BA_ "GenSigTimeoutTime_BPCM" SG_ 504 MCPB_CoolantTemp_P 0;
BA_ "GenSigTimeoutTime_PBWM" SG_ 504 MCPB_DC_Current_P 0;
BA_ "GenSigTimeoutTime_MCPB" SG_ 504 MCPB_DC_Current_P 0;
BA_ "GenSigTimeoutTime_MCPA" SG_ 504 MCPB_DC_Current_P 0;
BA_ "GenSigStartValue" SG_ 294 MCPB_MtrMaxCpbltyTrq_P 8184;
BA_ "GenSigTimeoutTime_PBWM" SG_ 294 MCPB_MtrIndex_P 0;
BA_ "GenSigTimeoutTime_MCPB" SG_ 294 MCPB_MtrIndex_P 0;
BA_ "GenSigTimeoutTime_MCPA" SG_ 294 MCPB_MtrIndex_P 0;
BA_ "GenSigTimeoutTime_IDCM" SG_ 294 MCPB_MtrIndex_P 0;
BA_ "GenSigTimeoutTime_ECM" SG_ 294 MCPB_MtrIndex_P 0;
BA_ "GenSigTimeoutTime_DMPI" SG_ 294 MCPB_MtrIndex_P 0;
BA_ "GenSigTimeoutTime_BPCM" SG_ 294 MCPB_MtrIndex_P 0;
BA_ "GenSigTimeoutTime_PBWM" SG_ 294 MCPB_CpbltySpdDivVolt_P 0;
BA_ "GenSigTimeoutTime_MCPB" SG_ 294 MCPB_CpbltySpdDivVolt_P 0;
BA_ "GenSigTimeoutTime_MCPA" SG_ 294 MCPB_CpbltySpdDivVolt_P 0;
BA_ "GenSigTimeoutTime_IDCM" SG_ 294 MCPB_CpbltySpdDivVolt_P 0;
BA_ "GenSigTimeoutTime_ECM" SG_ 294 MCPB_CpbltySpdDivVolt_P 0;
BA_ "GenSigTimeoutTime_DMPI" SG_ 294 MCPB_CpbltySpdDivVolt_P 0;
BA_ "GenSigTimeoutTime_BPCM" SG_ 294 MCPB_CpbltySpdDivVolt_P 0;
BA_ "GenSigTimeoutTime_PBWM" SG_ 294 MCPB_DeratingFactor_P 0;
BA_ "GenSigTimeoutTime_MCPB" SG_ 294 MCPB_DeratingFactor_P 0;
BA_ "GenSigTimeoutTime_MCPA" SG_ 294 MCPB_DeratingFactor_P 0;
BA_ "GenSigTimeoutTime_IDCM" SG_ 294 MCPB_DeratingFactor_P 0;
BA_ "GenSigTimeoutTime_ECM" SG_ 294 MCPB_DeratingFactor_P 0;
BA_ "GenSigTimeoutTime_DMPI" SG_ 294 MCPB_DeratingFactor_P 0;
BA_ "GenSigTimeoutTime_BPCM" SG_ 294 MCPB_DeratingFactor_P 0;
BA_ "GenSigTimeoutTime_PBWM" SG_ 294 MCPB_Dschrge_Status_P 0;
BA_ "GenSigTimeoutTime_MCPB" SG_ 294 MCPB_Dschrge_Status_P 0;
BA_ "GenSigTimeoutTime_MCPA" SG_ 294 MCPB_Dschrge_Status_P 0;
BA_ "GenSigTimeoutTime_IDCM" SG_ 294 MCPB_Dschrge_Status_P 0;
BA_ "GenSigTimeoutTime_ECM" SG_ 294 MCPB_Dschrge_Status_P 0;
BA_ "GenSigTimeoutTime_DMPI" SG_ 294 MCPB_Dschrge_Status_P 0;
BA_ "GenSigTimeoutTime_BPCM" SG_ 294 MCPB_Dschrge_Status_P 0;
BA_ "GenSigTimeoutTime_PBWM" SG_ 294 MCPB_HV_CnctrOpn_Req_P 0;
BA_ "GenSigTimeoutTime_MCPB" SG_ 294 MCPB_HV_CnctrOpn_Req_P 0;
BA_ "GenSigTimeoutTime_MCPA" SG_ 294 MCPB_HV_CnctrOpn_Req_P 0;
BA_ "GenSigTimeoutTime_IDCM" SG_ 294 MCPB_HV_CnctrOpn_Req_P 0;
BA_ "GenSigTimeoutTime_ECM" SG_ 294 MCPB_HV_CnctrOpn_Req_P 0;
BA_ "GenSigTimeoutTime_DMPI" SG_ 294 MCPB_HV_CnctrOpn_Req_P 0;
BA_ "GenSigTimeoutTime_BPCM" SG_ 294 MCPB_HV_CnctrOpn_Req_P 0;
BA_ "GenSigTimeoutTime_PBWM" SG_ 294 MCPB_InterlockSts_P 0;
BA_ "GenSigTimeoutTime_MCPB" SG_ 294 MCPB_InterlockSts_P 0;
BA_ "GenSigTimeoutTime_MCPA" SG_ 294 MCPB_InterlockSts_P 0;
BA_ "GenSigTimeoutTime_IDCM" SG_ 294 MCPB_InterlockSts_P 0;
BA_ "GenSigTimeoutTime_ECM" SG_ 294 MCPB_InterlockSts_P 0;
BA_ "GenSigTimeoutTime_DMPI" SG_ 294 MCPB_InterlockSts_P 0;
BA_ "GenSigTimeoutTime_BPCM" SG_ 294 MCPB_InterlockSts_P 0;
BA_ "GenSigTimeoutTime_PBWM" SG_ 294 MCPB_Invrtr_State_P 0;
BA_ "GenSigTimeoutTime_MCPB" SG_ 294 MCPB_Invrtr_State_P 0;
BA_ "GenSigTimeoutTime_MCPA" SG_ 294 MCPB_Invrtr_State_P 0;
BA_ "GenSigTimeoutTime_IDCM" SG_ 294 MCPB_Invrtr_State_P 0;
BA_ "GenSigTimeoutTime_ECM" SG_ 294 MCPB_Invrtr_State_P 0;
BA_ "GenSigTimeoutTime_DMPI" SG_ 294 MCPB_Invrtr_State_P 0;
BA_ "GenSigTimeoutTime_BPCM" SG_ 294 MCPB_Invrtr_State_P 0;
BA_ "GenSigTimeoutTime_PBWM" SG_ 294 MCPB_MaxTorq_P 0;
BA_ "GenSigTimeoutTime_MCPB" SG_ 294 MCPB_MaxTorq_P 0;
BA_ "GenSigTimeoutTime_MCPA" SG_ 294 MCPB_MaxTorq_P 0;
BA_ "GenSigTimeoutTime_IDCM" SG_ 294 MCPB_MaxTorq_P 0;
BA_ "GenSigTimeoutTime_ECM" SG_ 294 MCPB_MaxTorq_P 0;
BA_ "GenSigTimeoutTime_DMPI" SG_ 294 MCPB_MaxTorq_P 0;
BA_ "GenSigTimeoutTime_BPCM" SG_ 294 MCPB_MaxTorq_P 0;
BA_ "GenSigStartValue" SG_ 294 MCPB_MaxTorq_P 8184;
BA_ "GenSigTimeoutTime_PBWM" SG_ 294 MCPB_MinTorq_P 0;
BA_ "GenSigTimeoutTime_MCPB" SG_ 294 MCPB_MinTorq_P 0;
BA_ "GenSigTimeoutTime_MCPA" SG_ 294 MCPB_MinTorq_P 0;
BA_ "GenSigTimeoutTime_IDCM" SG_ 294 MCPB_MinTorq_P 0;
BA_ "GenSigTimeoutTime_ECM" SG_ 294 MCPB_MinTorq_P 0;
BA_ "GenSigTimeoutTime_DMPI" SG_ 294 MCPB_MinTorq_P 0;
BA_ "GenSigTimeoutTime_BPCM" SG_ 294 MCPB_MinTorq_P 0;
BA_ "GenSigStartValue" SG_ 294 MCPB_MinTorq_P 8184;
BA_ "GenSigTimeoutTime_PBWM" SG_ 1065 CRC_MCPB_OBD_DTC 0;
BA_ "GenSigTimeoutTime_MCPB" SG_ 1065 CRC_MCPB_OBD_DTC 0;
BA_ "GenSigTimeoutTime_MCPA" SG_ 1065 CRC_MCPB_OBD_DTC 0;
BA_ "GenSigTimeoutTime_IDCM" SG_ 1065 CRC_MCPB_OBD_DTC 0;
BA_ "GenSigTimeoutTime_ECM" SG_ 1065 CRC_MCPB_OBD_DTC 0;
BA_ "GenSigTimeoutTime_DMPI" SG_ 1065 CRC_MCPB_OBD_DTC 0;
BA_ "GenSigTimeoutTime_BPCM" SG_ 1065 CRC_MCPB_OBD_DTC 0;
BA_ "GenSigTimeoutTime_PBWM" SG_ 294 MCPB_3PS_Pos_P 0;
BA_ "GenSigTimeoutTime_MCPB" SG_ 294 MCPB_3PS_Pos_P 0;
BA_ "GenSigTimeoutTime_MCPA" SG_ 294 MCPB_3PS_Pos_P 0;
BA_ "GenSigTimeoutTime_IDCM" SG_ 294 MCPB_3PS_Pos_P 0;
BA_ "GenSigTimeoutTime_ECM" SG_ 294 MCPB_3PS_Pos_P 0;
BA_ "GenSigTimeoutTime_DMPI" SG_ 294 MCPB_3PS_Pos_P 0;
BA_ "GenSigTimeoutTime_BPCM" SG_ 294 MCPB_3PS_Pos_P 0;
BA_ "GenSigTimeoutTime_PBWM" SG_ 294 MCPB_6SO_Status_P 0;
BA_ "GenSigTimeoutTime_MCPB" SG_ 294 MCPB_6SO_Status_P 0;
BA_ "GenSigTimeoutTime_MCPA" SG_ 294 MCPB_6SO_Status_P 0;
BA_ "GenSigTimeoutTime_IDCM" SG_ 294 MCPB_6SO_Status_P 0;
BA_ "GenSigTimeoutTime_ECM" SG_ 294 MCPB_6SO_Status_P 0;
BA_ "GenSigTimeoutTime_DMPI" SG_ 294 MCPB_6SO_Status_P 0;
BA_ "GenSigTimeoutTime_BPCM" SG_ 294 MCPB_6SO_Status_P 0;
BA_ "GenSigTimeoutTime_PBWM" SG_ 294 MCPB_AccelRawV_P 0;
BA_ "GenSigTimeoutTime_MCPB" SG_ 294 MCPB_AccelRawV_P 0;
BA_ "GenSigTimeoutTime_MCPA" SG_ 294 MCPB_AccelRawV_P 0;
BA_ "GenSigTimeoutTime_IDCM" SG_ 294 MCPB_AccelRawV_P 0;
BA_ "GenSigTimeoutTime_ECM" SG_ 294 MCPB_AccelRawV_P 0;
BA_ "GenSigTimeoutTime_DMPI" SG_ 294 MCPB_AccelRawV_P 0;
BA_ "GenSigTimeoutTime_BPCM" SG_ 294 MCPB_AccelRawV_P 0;
BA_ "GenSigTimeoutTime_PBWM" SG_ 294 MCPB_AC_Isolation_Status_P 0;
BA_ "GenSigTimeoutTime_MCPB" SG_ 294 MCPB_AC_Isolation_Status_P 0;
BA_ "GenSigTimeoutTime_MCPA" SG_ 294 MCPB_AC_Isolation_Status_P 0;
BA_ "GenSigTimeoutTime_IDCM" SG_ 294 MCPB_AC_Isolation_Status_P 0;
BA_ "GenSigTimeoutTime_ECM" SG_ 294 MCPB_AC_Isolation_Status_P 0;
BA_ "GenSigTimeoutTime_DMPI" SG_ 294 MCPB_AC_Isolation_Status_P 0;
BA_ "GenSigTimeoutTime_BPCM" SG_ 294 MCPB_AC_Isolation_Status_P 0;
BA_ "GenSigTimeoutTime_PBWM" SG_ 294 CRC_MCPB_PROPULSION 0;
BA_ "GenSigTimeoutTime_MCPB" SG_ 294 CRC_MCPB_PROPULSION 0;
BA_ "GenSigTimeoutTime_MCPA" SG_ 294 CRC_MCPB_PROPULSION 0;
BA_ "GenSigTimeoutTime_IDCM" SG_ 294 CRC_MCPB_PROPULSION 0;
BA_ "GenSigTimeoutTime_ECM" SG_ 294 CRC_MCPB_PROPULSION 0;
BA_ "GenSigTimeoutTime_DMPI" SG_ 294 CRC_MCPB_PROPULSION 0;
BA_ "GenSigTimeoutTime_BPCM" SG_ 294 CRC_MCPB_PROPULSION 0;
BA_ "GenSigTimeoutTime_PBWM" SG_ 294 MC_MCPB_PROPULSION 0;
BA_ "GenSigTimeoutTime_MCPB" SG_ 294 MC_MCPB_PROPULSION 0;
BA_ "GenSigTimeoutTime_MCPA" SG_ 294 MC_MCPB_PROPULSION 0;
BA_ "GenSigTimeoutTime_IDCM" SG_ 294 MC_MCPB_PROPULSION 0;
BA_ "GenSigTimeoutTime_ECM" SG_ 294 MC_MCPB_PROPULSION 0;
BA_ "GenSigTimeoutTime_DMPI" SG_ 294 MC_MCPB_PROPULSION 0;
BA_ "GenSigTimeoutTime_BPCM" SG_ 294 MC_MCPB_PROPULSION 0;
BA_ "GenSigTimeoutTime_PBWM" SG_ 294 MCPB_AccelRaw_P 0;
BA_ "GenSigTimeoutTime_MCPB" SG_ 294 MCPB_AccelRaw_P 0;
BA_ "GenSigTimeoutTime_MCPA" SG_ 294 MCPB_AccelRaw_P 0;
BA_ "GenSigTimeoutTime_IDCM" SG_ 294 MCPB_AccelRaw_P 0;
BA_ "GenSigTimeoutTime_ECM" SG_ 294 MCPB_AccelRaw_P 0;
BA_ "GenSigTimeoutTime_DMPI" SG_ 294 MCPB_AccelRaw_P 0;
BA_ "GenSigTimeoutTime_BPCM" SG_ 294 MCPB_AccelRaw_P 0;
BA_ "GenSigStartValue" SG_ 294 MCPB_AccelRaw_P 32768;
BA_ "GenSigTimeoutTime_PBWM" SG_ 503 MCPA_PIM_DC_Side_Busbar_Temp_P 0;
BA_ "GenSigTimeoutTime_MCPB" SG_ 503 MCPA_PIM_DC_Side_Busbar_Temp_P 0;
BA_ "GenSigTimeoutTime_MCPA" SG_ 503 MCPA_PIM_DC_Side_Busbar_Temp_P 0;
BA_ "GenSigTimeoutTime_IDCM" SG_ 503 MCPA_PIM_DC_Side_Busbar_Temp_P 0;
BA_ "GenSigTimeoutTime_ECM" SG_ 503 MCPA_PIM_DC_Side_Busbar_Temp_P 0;
BA_ "GenSigTimeoutTime_DMPI" SG_ 503 MCPA_PIM_DC_Side_Busbar_Temp_P 0;
BA_ "GenSigTimeoutTime_BPCM" SG_ 503 MCPA_PIM_DC_Side_Busbar_Temp_P 0;
BA_ "GenSigTimeoutTime_PBWM" SG_ 503 MCPA_Inverter_Temp_P 0;
BA_ "GenSigTimeoutTime_MCPB" SG_ 503 MCPA_Inverter_Temp_P 0;
BA_ "GenSigTimeoutTime_MCPA" SG_ 503 MCPA_Inverter_Temp_P 0;
BA_ "GenSigTimeoutTime_IDCM" SG_ 503 MCPA_Inverter_Temp_P 0;
BA_ "GenSigTimeoutTime_ECM" SG_ 503 MCPA_Inverter_Temp_P 0;
BA_ "GenSigTimeoutTime_DMPI" SG_ 503 MCPA_Inverter_Temp_P 0;
BA_ "GenSigTimeoutTime_BPCM" SG_ 503 MCPA_Inverter_Temp_P 0;
BA_ "GenSigStartValue" SG_ 503 MCPA_Inverter_Temp_P 40;
BA_ "GenSigTimeoutTime_PBWM" SG_ 293 MCPA_Temp_P 0;
BA_ "GenSigTimeoutTime_MCPB" SG_ 293 MCPA_Temp_P 0;
BA_ "GenSigTimeoutTime_MCPA" SG_ 293 MCPA_Temp_P 0;
BA_ "GenSigTimeoutTime_IDCM" SG_ 293 MCPA_Temp_P 0;
BA_ "GenSigTimeoutTime_ECM" SG_ 293 MCPA_Temp_P 0;
BA_ "GenSigTimeoutTime_DMPI" SG_ 293 MCPA_Temp_P 0;
BA_ "GenSigTimeoutTime_BPCM" SG_ 293 MCPA_Temp_P 0;
BA_ "GenSigStartValue" SG_ 293 MCPA_Temp_P 40;
BA_ "GenSigTimeoutTime_PBWM" SG_ 503 MCPA_Control_Board_Temperature_P 0;
BA_ "GenSigTimeoutTime_MCPB" SG_ 503 MCPA_Control_Board_Temperature_P 0;
BA_ "GenSigTimeoutTime_MCPA" SG_ 503 MCPA_Control_Board_Temperature_P 0;
BA_ "GenSigTimeoutTime_IDCM" SG_ 503 MCPA_Control_Board_Temperature_P 0;
BA_ "GenSigTimeoutTime_ECM" SG_ 503 MCPA_Control_Board_Temperature_P 0;
BA_ "GenSigTimeoutTime_DMPI" SG_ 503 MCPA_Control_Board_Temperature_P 0;
BA_ "GenSigTimeoutTime_BPCM" SG_ 503 MCPA_Control_Board_Temperature_P 0;
BA_ "GenSigStartValue" SG_ 503 MCPA_Control_Board_Temperature_P 255;
BA_ "GenSigTimeoutTime_PBWM" SG_ 503 CLrDiagInfo_MCPA_P 0;
BA_ "GenSigTimeoutTime_MCPB" SG_ 503 CLrDiagInfo_MCPA_P 0;
BA_ "GenSigTimeoutTime_MCPA" SG_ 503 CLrDiagInfo_MCPA_P 0;
BA_ "GenSigTimeoutTime_IDCM" SG_ 503 CLrDiagInfo_MCPA_P 0;
BA_ "GenSigTimeoutTime_ECM" SG_ 503 CLrDiagInfo_MCPA_P 0;
BA_ "GenSigTimeoutTime_DMPI" SG_ 503 CLrDiagInfo_MCPA_P 0;
BA_ "GenSigTimeoutTime_BPCM" SG_ 503 CLrDiagInfo_MCPA_P 0;
BA_ "GenSigTimeoutTime_PBWM" SG_ 503 MCPA_Service_Lamp_Request_P 0;
BA_ "GenSigTimeoutTime_MCPB" SG_ 503 MCPA_Service_Lamp_Request_P 0;
BA_ "GenSigTimeoutTime_MCPA" SG_ 503 MCPA_Service_Lamp_Request_P 0;
BA_ "GenSigTimeoutTime_IDCM" SG_ 503 MCPA_Service_Lamp_Request_P 0;
BA_ "GenSigTimeoutTime_ECM" SG_ 503 MCPA_Service_Lamp_Request_P 0;
BA_ "GenSigTimeoutTime_DMPI" SG_ 503 MCPA_Service_Lamp_Request_P 0;
BA_ "GenSigTimeoutTime_BPCM" SG_ 503 MCPA_Service_Lamp_Request_P 0;
BA_ "GenSigTimeoutTime_PBWM" SG_ 503 MCPA_Rotor_Temperature_P 0;
BA_ "GenSigTimeoutTime_MCPB" SG_ 503 MCPA_Rotor_Temperature_P 0;
BA_ "GenSigTimeoutTime_MCPA" SG_ 503 MCPA_Rotor_Temperature_P 0;
BA_ "GenSigTimeoutTime_IDCM" SG_ 503 MCPA_Rotor_Temperature_P 0;
BA_ "GenSigTimeoutTime_ECM" SG_ 503 MCPA_Rotor_Temperature_P 0;
BA_ "GenSigTimeoutTime_DMPI" SG_ 503 MCPA_Rotor_Temperature_P 0;
BA_ "GenSigTimeoutTime_BPCM" SG_ 503 MCPA_Rotor_Temperature_P 0;
BA_ "GenSigStartValue" SG_ 503 MCPA_Rotor_Temperature_P 255;
BA_ "GenSigTimeoutTime_PBWM" SG_ 503 MCPA_DerateReason_P 0;
BA_ "GenSigTimeoutTime_MCPB" SG_ 503 MCPA_DerateReason_P 0;
BA_ "GenSigTimeoutTime_MCPA" SG_ 503 MCPA_DerateReason_P 0;
BA_ "GenSigTimeoutTime_IDCM" SG_ 503 MCPA_DerateReason_P 0;
BA_ "GenSigTimeoutTime_ECM" SG_ 503 MCPA_DerateReason_P 0;
BA_ "GenSigTimeoutTime_DMPI" SG_ 503 MCPA_DerateReason_P 0;
BA_ "GenSigTimeoutTime_BPCM" SG_ 503 MCPA_DerateReason_P 0;
BA_ "GenSigTimeoutTime_PBWM" SG_ 503 MCPA_DC_Current_P 0;
BA_ "GenSigTimeoutTime_MCPB" SG_ 503 MCPA_DC_Current_P 0;
BA_ "GenSigTimeoutTime_MCPA" SG_ 503 MCPA_DC_Current_P 0;
BA_ "GenSigTimeoutTime_IDCM" SG_ 503 MCPA_DC_Current_P 0;
BA_ "GenSigTimeoutTime_ECM" SG_ 503 MCPA_DC_Current_P 0;
BA_ "GenSigTimeoutTime_DMPI" SG_ 503 MCPA_DC_Current_P 0;
BA_ "GenSigStartValue" SG_ 503 MCPA_DC_Current_P 16384;
BA_ "GenSigTimeoutTime_PBWM" SG_ 503 MCPA_DC_Current_V_P 0;
BA_ "GenSigTimeoutTime_MCPB" SG_ 503 MCPA_DC_Current_V_P 0;
BA_ "GenSigTimeoutTime_MCPA" SG_ 503 MCPA_DC_Current_V_P 0;
BA_ "GenSigTimeoutTime_IDCM" SG_ 503 MCPA_DC_Current_V_P 0;
BA_ "GenSigTimeoutTime_ECM" SG_ 503 MCPA_DC_Current_V_P 0;
BA_ "GenSigTimeoutTime_DMPI" SG_ 503 MCPA_DC_Current_V_P 0;
BA_ "GenSigTimeoutTime_BPCM" SG_ 503 MCPA_DC_Current_V_P 0;
BA_ "GenSigTimeoutTime_PBWM" SG_ 503 MCPA_DC_Volt_V_P 0;
BA_ "GenSigTimeoutTime_MCPB" SG_ 503 MCPA_DC_Volt_V_P 0;
BA_ "GenSigTimeoutTime_MCPA" SG_ 503 MCPA_DC_Volt_V_P 0;
BA_ "GenSigTimeoutTime_IDCM" SG_ 503 MCPA_DC_Volt_V_P 0;
BA_ "GenSigTimeoutTime_ECM" SG_ 503 MCPA_DC_Volt_V_P 0;
BA_ "GenSigTimeoutTime_DMPI" SG_ 503 MCPA_DC_Volt_V_P 0;
BA_ "GenSigTimeoutTime_BPCM" SG_ 503 MCPA_DC_Volt_V_P 0;
BA_ "GenSigTimeoutTime_PBWM" SG_ 503 MCPA_DC_Voltage_P 0;
BA_ "GenSigTimeoutTime_MCPB" SG_ 503 MCPA_DC_Voltage_P 0;
BA_ "GenSigTimeoutTime_MCPA" SG_ 503 MCPA_DC_Voltage_P 0;
BA_ "GenSigTimeoutTime_IDCM" SG_ 503 MCPA_DC_Voltage_P 0;
BA_ "GenSigTimeoutTime_ECM" SG_ 503 MCPA_DC_Voltage_P 0;
BA_ "GenSigTimeoutTime_DMPI" SG_ 503 MCPA_DC_Voltage_P 0;
BA_ "GenSigTimeoutTime_BPCM" SG_ 503 MCPA_DC_Voltage_P 0;
BA_ "GenSigTimeoutTime_PBWM" SG_ 293 MCPA_SPT_Stat_P 0;
BA_ "GenSigTimeoutTime_MCPB" SG_ 293 MCPA_SPT_Stat_P 0;
BA_ "GenSigTimeoutTime_MCPA" SG_ 293 MCPA_SPT_Stat_P 0;
BA_ "GenSigTimeoutTime_IDCM" SG_ 293 MCPA_SPT_Stat_P 0;
BA_ "GenSigTimeoutTime_ECM" SG_ 293 MCPA_SPT_Stat_P 0;
BA_ "GenSigTimeoutTime_DMPI" SG_ 293 MCPA_SPT_Stat_P 0;
BA_ "GenSigTimeoutTime_BPCM" SG_ 293 MCPA_SPT_Stat_P 0;
BA_ "GenSigTimeoutTime_PBWM" SG_ 293 MCPA_TorqAchieved_AEMD_P 0;
BA_ "GenSigTimeoutTime_MCPB" SG_ 293 MCPA_TorqAchieved_AEMD_P 0;
BA_ "GenSigTimeoutTime_MCPA" SG_ 293 MCPA_TorqAchieved_AEMD_P 0;
BA_ "GenSigTimeoutTime_IDCM" SG_ 293 MCPA_TorqAchieved_AEMD_P 0;
BA_ "GenSigTimeoutTime_ECM" SG_ 293 MCPA_TorqAchieved_AEMD_P 0;
BA_ "GenSigTimeoutTime_DMPI" SG_ 293 MCPA_TorqAchieved_AEMD_P 0;
BA_ "GenSigTimeoutTime_BPCM" SG_ 293 MCPA_TorqAchieved_AEMD_P 0;
BA_ "GenSigStartValue" SG_ 293 MCPA_TorqAchieved_AEMD_P 8184;
BA_ "GenSigTimeoutTime_PBWM" SG_ 293 MCPA_TorqAchieved_AEMD_V_P 0;
BA_ "GenSigTimeoutTime_MCPB" SG_ 293 MCPA_TorqAchieved_AEMD_V_P 0;
BA_ "GenSigTimeoutTime_MCPA" SG_ 293 MCPA_TorqAchieved_AEMD_V_P 0;
BA_ "GenSigTimeoutTime_IDCM" SG_ 293 MCPA_TorqAchieved_AEMD_V_P 0;
BA_ "GenSigTimeoutTime_ECM" SG_ 293 MCPA_TorqAchieved_AEMD_V_P 0;
BA_ "GenSigTimeoutTime_DMPI" SG_ 293 MCPA_TorqAchieved_AEMD_V_P 0;
BA_ "GenSigTimeoutTime_BPCM" SG_ 293 MCPA_TorqAchieved_AEMD_V_P 0;
BA_ "GenSigTimeoutTime_PBWM" SG_ 293 MCPA_Torque_Achieved_P 0;
BA_ "GenSigTimeoutTime_MCPB" SG_ 293 MCPA_Torque_Achieved_P 0;
BA_ "GenSigTimeoutTime_MCPA" SG_ 293 MCPA_Torque_Achieved_P 0;
BA_ "GenSigTimeoutTime_IDCM" SG_ 293 MCPA_Torque_Achieved_P 0;
BA_ "GenSigTimeoutTime_ECM" SG_ 293 MCPA_Torque_Achieved_P 0;
BA_ "GenSigTimeoutTime_DMPI" SG_ 293 MCPA_Torque_Achieved_P 0;
BA_ "GenSigTimeoutTime_BPCM" SG_ 293 MCPA_Torque_Achieved_P 0;
BA_ "GenSigStartValue" SG_ 293 MCPA_Torque_Achieved_P 8184;
BA_ "GenSigTimeoutTime_PBWM" SG_ 293 MCPA_Torque_Achieved_V_P 0;
BA_ "GenSigTimeoutTime_MCPB" SG_ 293 MCPA_Torque_Achieved_V_P 0;
BA_ "GenSigTimeoutTime_MCPA" SG_ 293 MCPA_Torque_Achieved_V_P 0;
BA_ "GenSigTimeoutTime_IDCM" SG_ 293 MCPA_Torque_Achieved_V_P 0;
BA_ "GenSigTimeoutTime_ECM" SG_ 293 MCPA_Torque_Achieved_V_P 0;
BA_ "GenSigTimeoutTime_DMPI" SG_ 293 MCPA_Torque_Achieved_V_P 0;
BA_ "GenSigTimeoutTime_BPCM" SG_ 293 MCPA_Torque_Achieved_V_P 0;
BA_ "GenSigTimeoutTime_PBWM" SG_ 503 CRC_MCPA_STATUS 0;
BA_ "GenSigTimeoutTime_MCPB" SG_ 503 CRC_MCPA_STATUS 0;
BA_ "GenSigTimeoutTime_MCPA" SG_ 503 CRC_MCPA_STATUS 0;
BA_ "GenSigTimeoutTime_IDCM" SG_ 503 CRC_MCPA_STATUS 0;
BA_ "GenSigTimeoutTime_ECM" SG_ 503 CRC_MCPA_STATUS 0;
BA_ "GenSigTimeoutTime_DMPI" SG_ 503 CRC_MCPA_STATUS 0;
BA_ "GenSigTimeoutTime_BPCM" SG_ 503 CRC_MCPA_STATUS 0;
BA_ "GenSigTimeoutTime_PBWM" SG_ 503 MC_MCPA_STATUS 0;
BA_ "GenSigTimeoutTime_MCPB" SG_ 503 MC_MCPA_STATUS 0;
BA_ "GenSigTimeoutTime_MCPA" SG_ 503 MC_MCPA_STATUS 0;
BA_ "GenSigTimeoutTime_IDCM" SG_ 503 MC_MCPA_STATUS 0;
BA_ "GenSigTimeoutTime_ECM" SG_ 503 MC_MCPA_STATUS 0;
BA_ "GenSigTimeoutTime_DMPI" SG_ 503 MC_MCPA_STATUS 0;
BA_ "GenSigTimeoutTime_BPCM" SG_ 503 MC_MCPA_STATUS 0;
BA_ "GenSigTimeoutTime_PBWM" SG_ 503 MCPA_CoolantTemp_P 0;
BA_ "GenSigTimeoutTime_MCPB" SG_ 503 MCPA_CoolantTemp_P 0;
BA_ "GenSigTimeoutTime_MCPA" SG_ 503 MCPA_CoolantTemp_P 0;
BA_ "GenSigTimeoutTime_IDCM" SG_ 503 MCPA_CoolantTemp_P 0;
BA_ "GenSigTimeoutTime_ECM" SG_ 503 MCPA_CoolantTemp_P 0;
BA_ "GenSigTimeoutTime_DMPI" SG_ 503 MCPA_CoolantTemp_P 0;
BA_ "GenSigTimeoutTime_BPCM" SG_ 503 MCPA_CoolantTemp_P 0;
BA_ "GenSigTimeoutTime_PBWM" SG_ 293 MCPA_MtrMinCpbltyTrq_P 0;
BA_ "GenSigTimeoutTime_MCPB" SG_ 293 MCPA_MtrMinCpbltyTrq_P 0;
BA_ "GenSigTimeoutTime_MCPA" SG_ 293 MCPA_MtrMinCpbltyTrq_P 0;
BA_ "GenSigTimeoutTime_IDCM" SG_ 293 MCPA_MtrMinCpbltyTrq_P 0;
BA_ "GenSigTimeoutTime_ECM" SG_ 293 MCPA_MtrMinCpbltyTrq_P 0;
BA_ "GenSigTimeoutTime_DMPI" SG_ 293 MCPA_MtrMinCpbltyTrq_P 0;
BA_ "GenSigTimeoutTime_PBWM" SG_ 293 MCPA_RPM_P 0;
BA_ "GenSigTimeoutTime_MCPB" SG_ 293 MCPA_RPM_P 0;
BA_ "GenSigTimeoutTime_MCPA" SG_ 293 MCPA_RPM_P 0;
BA_ "GenSigTimeoutTime_IDCM" SG_ 293 MCPA_RPM_P 0;
BA_ "GenSigTimeoutTime_ECM" SG_ 293 MCPA_RPM_P 0;
BA_ "GenSigTimeoutTime_DMPI" SG_ 293 MCPA_RPM_P 0;
BA_ "GenSigTimeoutTime_BPCM" SG_ 293 MCPA_RPM_P 0;
BA_ "GenSigStartValue" SG_ 293 MCPA_RPM_P 32768;
BA_ "GenSigTimeoutTime_PBWM" SG_ 293 MCPA_RPM_V_P 0;
BA_ "GenSigTimeoutTime_MCPB" SG_ 293 MCPA_RPM_V_P 0;
BA_ "GenSigTimeoutTime_MCPA" SG_ 293 MCPA_RPM_V_P 0;
BA_ "GenSigTimeoutTime_IDCM" SG_ 293 MCPA_RPM_V_P 0;
BA_ "GenSigTimeoutTime_ECM" SG_ 293 MCPA_RPM_V_P 0;
BA_ "GenSigTimeoutTime_DMPI" SG_ 293 MCPA_RPM_V_P 0;
BA_ "GenSigTimeoutTime_BPCM" SG_ 293 MCPA_RPM_V_P 0;
BA_ "GenSigTimeoutTime_PBWM" SG_ 293 MCPA_Spd_Lim_P 0;
BA_ "GenSigTimeoutTime_MCPB" SG_ 293 MCPA_Spd_Lim_P 0;
BA_ "GenSigTimeoutTime_MCPA" SG_ 293 MCPA_Spd_Lim_P 0;
BA_ "GenSigTimeoutTime_IDCM" SG_ 293 MCPA_Spd_Lim_P 0;
BA_ "GenSigTimeoutTime_ECM" SG_ 293 MCPA_Spd_Lim_P 0;
BA_ "GenSigTimeoutTime_DMPI" SG_ 293 MCPA_Spd_Lim_P 0;
BA_ "GenSigTimeoutTime_BPCM" SG_ 293 MCPA_Spd_Lim_P 0;
BA_ "GenSigStartValue" SG_ 293 MCPA_Spd_Lim_P 32767;
BA_ "GenSigTimeoutTime_BPCM" SG_ 293 MCPA_MtrMinCpbltyTrq_P 0;
BA_ "GenSigStartValue" SG_ 293 MCPA_MtrMinCpbltyTrq_P 8184;
BA_ "GenSigTimeoutTime_PBWM" SG_ 293 MCPA_MaxTorq_P 0;
BA_ "GenSigTimeoutTime_MCPB" SG_ 293 MCPA_MaxTorq_P 0;
BA_ "GenSigTimeoutTime_MCPA" SG_ 293 MCPA_MaxTorq_P 0;
BA_ "GenSigTimeoutTime_IDCM" SG_ 293 MCPA_MaxTorq_P 0;
BA_ "GenSigTimeoutTime_ECM" SG_ 293 MCPA_MaxTorq_P 0;
BA_ "GenSigTimeoutTime_DMPI" SG_ 293 MCPA_MaxTorq_P 0;
BA_ "GenSigTimeoutTime_BPCM" SG_ 293 MCPA_MaxTorq_P 0;
BA_ "GenSigStartValue" SG_ 293 MCPA_MaxTorq_P 8184;
BA_ "GenSigTimeoutTime_PBWM" SG_ 293 MCPA_MinTorq_P 0;
BA_ "GenSigTimeoutTime_MCPB" SG_ 293 MCPA_MinTorq_P 0;
BA_ "GenSigTimeoutTime_MCPA" SG_ 293 MCPA_MinTorq_P 0;
BA_ "GenSigTimeoutTime_IDCM" SG_ 293 MCPA_MinTorq_P 0;
BA_ "GenSigTimeoutTime_ECM" SG_ 293 MCPA_MinTorq_P 0;
BA_ "GenSigTimeoutTime_DMPI" SG_ 293 MCPA_MinTorq_P 0;
BA_ "GenSigTimeoutTime_BPCM" SG_ 293 MCPA_MinTorq_P 0;
BA_ "GenSigStartValue" SG_ 293 MCPA_MinTorq_P 8184;
BA_ "GenSigTimeoutTime_PBWM" SG_ 293 MCPA_MtrIndex_P 0;
BA_ "GenSigTimeoutTime_MCPB" SG_ 293 MCPA_MtrIndex_P 0;
BA_ "GenSigTimeoutTime_MCPA" SG_ 293 MCPA_MtrIndex_P 0;
BA_ "GenSigTimeoutTime_IDCM" SG_ 293 MCPA_MtrIndex_P 0;
BA_ "GenSigTimeoutTime_ECM" SG_ 293 MCPA_MtrIndex_P 0;
BA_ "GenSigTimeoutTime_DMPI" SG_ 293 MCPA_MtrIndex_P 0;
BA_ "GenSigTimeoutTime_BPCM" SG_ 293 MCPA_MtrIndex_P 0;
BA_ "GenSigTimeoutTime_PBWM" SG_ 293 MCPA_MtrMaxCpbltyTrq_P 0;
BA_ "GenSigTimeoutTime_MCPB" SG_ 293 MCPA_MtrMaxCpbltyTrq_P 0;
BA_ "GenSigTimeoutTime_MCPA" SG_ 293 MCPA_MtrMaxCpbltyTrq_P 0;
BA_ "GenSigTimeoutTime_IDCM" SG_ 293 MCPA_MtrMaxCpbltyTrq_P 0;
BA_ "GenSigTimeoutTime_ECM" SG_ 293 MCPA_MtrMaxCpbltyTrq_P 0;
BA_ "GenSigTimeoutTime_DMPI" SG_ 293 MCPA_MtrMaxCpbltyTrq_P 0;
BA_ "GenSigTimeoutTime_BPCM" SG_ 293 MCPA_MtrMaxCpbltyTrq_P 0;
BA_ "GenSigStartValue" SG_ 293 MCPA_MtrMaxCpbltyTrq_P 8184;
BA_ "GenSigTimeoutTime_PBWM" SG_ 293 MCPA_6SO_Status_P 0;
BA_ "GenSigTimeoutTime_MCPB" SG_ 293 MCPA_6SO_Status_P 0;
BA_ "GenSigTimeoutTime_MCPA" SG_ 293 MCPA_6SO_Status_P 0;
BA_ "GenSigTimeoutTime_IDCM" SG_ 293 MCPA_6SO_Status_P 0;
BA_ "GenSigTimeoutTime_ECM" SG_ 293 MCPA_6SO_Status_P 0;
BA_ "GenSigTimeoutTime_DMPI" SG_ 293 MCPA_6SO_Status_P 0;
BA_ "GenSigTimeoutTime_BPCM" SG_ 293 MCPA_6SO_Status_P 0;
BA_ "GenSigTimeoutTime_PBWM" SG_ 293 MCPA_AccelRawV_P 0;
BA_ "GenSigTimeoutTime_MCPB" SG_ 293 MCPA_AccelRawV_P 0;
BA_ "GenSigTimeoutTime_MCPA" SG_ 293 MCPA_AccelRawV_P 0;
BA_ "GenSigTimeoutTime_IDCM" SG_ 293 MCPA_AccelRawV_P 0;
BA_ "GenSigTimeoutTime_ECM" SG_ 293 MCPA_AccelRawV_P 0;
BA_ "GenSigTimeoutTime_DMPI" SG_ 293 MCPA_AccelRawV_P 0;
BA_ "GenSigTimeoutTime_BPCM" SG_ 293 MCPA_AccelRawV_P 0;
BA_ "GenSigTimeoutTime_PBWM" SG_ 293 MCPA_CpbltySpdDivVolt_P 0;
BA_ "GenSigTimeoutTime_MCPB" SG_ 293 MCPA_CpbltySpdDivVolt_P 0;
BA_ "GenSigTimeoutTime_MCPA" SG_ 293 MCPA_CpbltySpdDivVolt_P 0;
BA_ "GenSigTimeoutTime_IDCM" SG_ 293 MCPA_CpbltySpdDivVolt_P 0;
BA_ "GenSigTimeoutTime_ECM" SG_ 293 MCPA_CpbltySpdDivVolt_P 0;
BA_ "GenSigTimeoutTime_DMPI" SG_ 293 MCPA_CpbltySpdDivVolt_P 0;
BA_ "GenSigTimeoutTime_BPCM" SG_ 293 MCPA_CpbltySpdDivVolt_P 0;
BA_ "GenSigTimeoutTime_PBWM" SG_ 293 MCPA_DeratingFactor_P 0;
BA_ "GenSigTimeoutTime_MCPB" SG_ 293 MCPA_DeratingFactor_P 0;
BA_ "GenSigTimeoutTime_MCPA" SG_ 293 MCPA_DeratingFactor_P 0;
BA_ "GenSigTimeoutTime_IDCM" SG_ 293 MCPA_DeratingFactor_P 0;
BA_ "GenSigTimeoutTime_ECM" SG_ 293 MCPA_DeratingFactor_P 0;
BA_ "GenSigTimeoutTime_DMPI" SG_ 293 MCPA_DeratingFactor_P 0;
BA_ "GenSigTimeoutTime_BPCM" SG_ 293 MCPA_DeratingFactor_P 0;
BA_ "GenSigTimeoutTime_PBWM" SG_ 293 MCPA_Dschrge_Status_P 0;
BA_ "GenSigTimeoutTime_MCPB" SG_ 293 MCPA_Dschrge_Status_P 0;
BA_ "GenSigTimeoutTime_MCPA" SG_ 293 MCPA_Dschrge_Status_P 0;
BA_ "GenSigTimeoutTime_IDCM" SG_ 293 MCPA_Dschrge_Status_P 0;
BA_ "GenSigTimeoutTime_ECM" SG_ 293 MCPA_Dschrge_Status_P 0;
BA_ "GenSigTimeoutTime_DMPI" SG_ 293 MCPA_Dschrge_Status_P 0;
BA_ "GenSigTimeoutTime_BPCM" SG_ 293 MCPA_Dschrge_Status_P 0;
BA_ "GenSigTimeoutTime_PBWM" SG_ 293 MCPA_HV_CnctrOpn_Req_P 0;
BA_ "GenSigTimeoutTime_MCPB" SG_ 293 MCPA_HV_CnctrOpn_Req_P 0;
BA_ "GenSigTimeoutTime_MCPA" SG_ 293 MCPA_HV_CnctrOpn_Req_P 0;
BA_ "GenSigTimeoutTime_IDCM" SG_ 293 MCPA_HV_CnctrOpn_Req_P 0;
BA_ "GenSigTimeoutTime_ECM" SG_ 293 MCPA_HV_CnctrOpn_Req_P 0;
BA_ "GenSigTimeoutTime_DMPI" SG_ 293 MCPA_HV_CnctrOpn_Req_P 0;
BA_ "GenSigTimeoutTime_BPCM" SG_ 293 MCPA_HV_CnctrOpn_Req_P 0;
BA_ "GenSigTimeoutTime_PBWM" SG_ 293 MCPA_InterlockSts_P 0;
BA_ "GenSigTimeoutTime_MCPB" SG_ 293 MCPA_InterlockSts_P 0;
BA_ "GenSigTimeoutTime_MCPA" SG_ 293 MCPA_InterlockSts_P 0;
BA_ "GenSigTimeoutTime_IDCM" SG_ 293 MCPA_InterlockSts_P 0;
BA_ "GenSigTimeoutTime_ECM" SG_ 293 MCPA_InterlockSts_P 0;
BA_ "GenSigTimeoutTime_DMPI" SG_ 293 MCPA_InterlockSts_P 0;
BA_ "GenSigTimeoutTime_BPCM" SG_ 293 MCPA_InterlockSts_P 0;
BA_ "GenSigTimeoutTime_PBWM" SG_ 293 MCPA_Invrtr_State_P 0;
BA_ "GenSigTimeoutTime_MCPB" SG_ 293 MCPA_Invrtr_State_P 0;
BA_ "GenSigTimeoutTime_MCPA" SG_ 293 MCPA_Invrtr_State_P 0;
BA_ "GenSigTimeoutTime_IDCM" SG_ 293 MCPA_Invrtr_State_P 0;
BA_ "GenSigTimeoutTime_ECM" SG_ 293 MCPA_Invrtr_State_P 0;
BA_ "GenSigTimeoutTime_DMPI" SG_ 293 MCPA_Invrtr_State_P 0;
BA_ "GenSigTimeoutTime_BPCM" SG_ 293 MCPA_Invrtr_State_P 0;
BA_ "GenSigTimeoutTime_PBWM" SG_ 293 MCPA_3PS_Pos_P 0;
BA_ "GenSigTimeoutTime_MCPB" SG_ 293 MCPA_3PS_Pos_P 0;
BA_ "GenSigTimeoutTime_MCPA" SG_ 293 MCPA_3PS_Pos_P 0;
BA_ "GenSigTimeoutTime_IDCM" SG_ 293 MCPA_3PS_Pos_P 0;
BA_ "GenSigTimeoutTime_ECM" SG_ 293 MCPA_3PS_Pos_P 0;
BA_ "GenSigTimeoutTime_DMPI" SG_ 293 MCPA_3PS_Pos_P 0;
BA_ "GenSigTimeoutTime_BPCM" SG_ 293 MCPA_3PS_Pos_P 0;
BA_ "GenSigTimeoutTime_PBWM" SG_ 1057 MessageCounter_MCPA_OBD_DTC 0;
BA_ "GenSigTimeoutTime_MCPB" SG_ 1057 MessageCounter_MCPA_OBD_DTC 0;
BA_ "GenSigTimeoutTime_MCPA" SG_ 1057 MessageCounter_MCPA_OBD_DTC 0;
BA_ "GenSigTimeoutTime_IDCM" SG_ 1057 MessageCounter_MCPA_OBD_DTC 0;
BA_ "GenSigTimeoutTime_ECM" SG_ 1057 MessageCounter_MCPA_OBD_DTC 0;
BA_ "GenSigTimeoutTime_DMPI" SG_ 1057 MessageCounter_MCPA_OBD_DTC 0;
BA_ "GenSigTimeoutTime_BPCM" SG_ 1057 MessageCounter_MCPA_OBD_DTC 0;
BA_ "GenSigTimeoutTime_PBWM" SG_ 1057 MCPA_DTC_Stat1 0;
BA_ "GenSigTimeoutTime_MCPB" SG_ 1057 MCPA_DTC_Stat1 0;
BA_ "GenSigTimeoutTime_MCPA" SG_ 1057 MCPA_DTC_Stat1 0;
BA_ "GenSigTimeoutTime_IDCM" SG_ 1057 MCPA_DTC_Stat1 0;
BA_ "GenSigTimeoutTime_ECM" SG_ 1057 MCPA_DTC_Stat1 0;
BA_ "GenSigTimeoutTime_DMPI" SG_ 1057 MCPA_DTC_Stat1 0;
BA_ "GenSigTimeoutTime_BPCM" SG_ 1057 MCPA_DTC_Stat1 0;
BA_ "GenSigTimeoutTime_PBWM" SG_ 1057 MCPA_DTC_Stat2 0;
BA_ "GenSigTimeoutTime_MCPB" SG_ 1057 MCPA_DTC_Stat2 0;
BA_ "GenSigTimeoutTime_MCPA" SG_ 1057 MCPA_DTC_Stat2 0;
BA_ "GenSigTimeoutTime_IDCM" SG_ 1057 MCPA_DTC_Stat2 0;
BA_ "GenSigTimeoutTime_ECM" SG_ 1057 MCPA_DTC_Stat2 0;
BA_ "GenSigTimeoutTime_DMPI" SG_ 1057 MCPA_DTC_Stat2 0;
BA_ "GenSigTimeoutTime_BPCM" SG_ 1057 MCPA_DTC_Stat2 0;
BA_ "GenSigTimeoutTime_PBWM" SG_ 1057 MCPA_Cal_ID_Idx 0;
BA_ "GenSigTimeoutTime_MCPB" SG_ 1057 MCPA_Cal_ID_Idx 0;
BA_ "GenSigTimeoutTime_MCPA" SG_ 1057 MCPA_Cal_ID_Idx 0;
BA_ "GenSigTimeoutTime_IDCM" SG_ 1057 MCPA_Cal_ID_Idx 0;
BA_ "GenSigTimeoutTime_ECM" SG_ 1057 MCPA_Cal_ID_Idx 0;
BA_ "GenSigTimeoutTime_DMPI" SG_ 1057 MCPA_Cal_ID_Idx 0;
BA_ "GenSigTimeoutTime_BPCM" SG_ 1057 MCPA_Cal_ID_Idx 0;
BA_ "GenSigTimeoutTime_PBWM" SG_ 1057 MCPA_CalChar 0;
BA_ "GenSigTimeoutTime_MCPB" SG_ 1057 MCPA_CalChar 0;
BA_ "GenSigTimeoutTime_MCPA" SG_ 1057 MCPA_CalChar 0;
BA_ "GenSigTimeoutTime_IDCM" SG_ 1057 MCPA_CalChar 0;
BA_ "GenSigTimeoutTime_ECM" SG_ 1057 MCPA_CalChar 0;
BA_ "GenSigTimeoutTime_DMPI" SG_ 1057 MCPA_CalChar 0;
BA_ "GenSigTimeoutTime_BPCM" SG_ 1057 MCPA_CalChar 0;
BA_ "GenSigTimeoutTime_PBWM" SG_ 1057 MCPA_DTC_Idx1 0;
BA_ "GenSigTimeoutTime_MCPB" SG_ 1057 MCPA_DTC_Idx1 0;
BA_ "GenSigTimeoutTime_MCPA" SG_ 1057 MCPA_DTC_Idx1 0;
BA_ "GenSigTimeoutTime_IDCM" SG_ 1057 MCPA_DTC_Idx1 0;
BA_ "GenSigTimeoutTime_ECM" SG_ 1057 MCPA_DTC_Idx1 0;
BA_ "GenSigTimeoutTime_DMPI" SG_ 1057 MCPA_DTC_Idx1 0;
BA_ "GenSigTimeoutTime_BPCM" SG_ 1057 MCPA_DTC_Idx1 0;
BA_ "GenSigTimeoutTime_PBWM" SG_ 1057 MCPA_DTC_Idx2 0;
BA_ "GenSigTimeoutTime_MCPB" SG_ 1057 MCPA_DTC_Idx2 0;
BA_ "GenSigTimeoutTime_MCPA" SG_ 1057 MCPA_DTC_Idx2 0;
BA_ "GenSigTimeoutTime_IDCM" SG_ 1057 MCPA_DTC_Idx2 0;
BA_ "GenSigTimeoutTime_ECM" SG_ 1057 MCPA_DTC_Idx2 0;
BA_ "GenSigTimeoutTime_DMPI" SG_ 1057 MCPA_DTC_Idx2 0;
BA_ "GenSigTimeoutTime_BPCM" SG_ 1057 MCPA_DTC_Idx2 0;
BA_ "GenSigTimeoutTime_PBWM" SG_ 1057 CRC_MCPA_OBD_DTC 0;
BA_ "GenSigTimeoutTime_MCPB" SG_ 1057 CRC_MCPA_OBD_DTC 0;
BA_ "GenSigTimeoutTime_MCPA" SG_ 1057 CRC_MCPA_OBD_DTC 0;
BA_ "GenSigTimeoutTime_IDCM" SG_ 1057 CRC_MCPA_OBD_DTC 0;
BA_ "GenSigTimeoutTime_ECM" SG_ 1057 CRC_MCPA_OBD_DTC 0;
BA_ "GenSigTimeoutTime_DMPI" SG_ 1057 CRC_MCPA_OBD_DTC 0;
BA_ "GenSigTimeoutTime_BPCM" SG_ 1057 CRC_MCPA_OBD_DTC 0;
BA_ "GenSigTimeoutTime_PBWM" SG_ 293 MCPA_AC_Isolation_Status_P 0;
BA_ "GenSigTimeoutTime_MCPB" SG_ 293 MCPA_AC_Isolation_Status_P 0;
BA_ "GenSigTimeoutTime_MCPA" SG_ 293 MCPA_AC_Isolation_Status_P 0;
BA_ "GenSigTimeoutTime_IDCM" SG_ 293 MCPA_AC_Isolation_Status_P 0;
BA_ "GenSigTimeoutTime_ECM" SG_ 293 MCPA_AC_Isolation_Status_P 0;
BA_ "GenSigTimeoutTime_DMPI" SG_ 293 MCPA_AC_Isolation_Status_P 0;
BA_ "GenSigTimeoutTime_BPCM" SG_ 293 MCPA_AC_Isolation_Status_P 0;
BA_ "GenSigTimeoutTime_PBWM" SG_ 293 CRC_MCPA_PROPULSION 0;
BA_ "GenSigTimeoutTime_MCPB" SG_ 293 CRC_MCPA_PROPULSION 0;
BA_ "GenSigTimeoutTime_MCPA" SG_ 293 CRC_MCPA_PROPULSION 0;
BA_ "GenSigTimeoutTime_IDCM" SG_ 293 CRC_MCPA_PROPULSION 0;
BA_ "GenSigTimeoutTime_ECM" SG_ 293 CRC_MCPA_PROPULSION 0;
BA_ "GenSigTimeoutTime_DMPI" SG_ 293 CRC_MCPA_PROPULSION 0;
BA_ "GenSigTimeoutTime_BPCM" SG_ 293 CRC_MCPA_PROPULSION 0;
BA_ "GenSigTimeoutTime_PBWM" SG_ 293 MC_MCPA_PROPULSION 0;
BA_ "GenSigTimeoutTime_MCPB" SG_ 293 MC_MCPA_PROPULSION 0;
BA_ "GenSigTimeoutTime_MCPA" SG_ 293 MC_MCPA_PROPULSION 0;
BA_ "GenSigTimeoutTime_IDCM" SG_ 293 MC_MCPA_PROPULSION 0;
BA_ "GenSigTimeoutTime_ECM" SG_ 293 MC_MCPA_PROPULSION 0;
BA_ "GenSigTimeoutTime_DMPI" SG_ 293 MC_MCPA_PROPULSION 0;
BA_ "GenSigTimeoutTime_BPCM" SG_ 293 MC_MCPA_PROPULSION 0;
BA_ "GenSigTimeoutTime_PBWM" SG_ 293 MCPA_AccelRaw_P 0;
BA_ "GenSigTimeoutTime_MCPB" SG_ 293 MCPA_AccelRaw_P 0;
BA_ "GenSigTimeoutTime_MCPA" SG_ 293 MCPA_AccelRaw_P 0;
BA_ "GenSigTimeoutTime_IDCM" SG_ 293 MCPA_AccelRaw_P 0;
BA_ "GenSigTimeoutTime_ECM" SG_ 293 MCPA_AccelRaw_P 0;
BA_ "GenSigTimeoutTime_DMPI" SG_ 293 MCPA_AccelRaw_P 0;
BA_ "GenSigTimeoutTime_BPCM" SG_ 293 MCPA_AccelRaw_P 0;
BA_ "GenSigStartValue" SG_ 293 MCPA_AccelRaw_P 32768;
BA_ "GenSigTimeoutTime_PBWM" SG_ 2654486588 CBV_bit0_RepeatMessageRequestBit 0;
BA_ "GenSigTimeoutTime_MCPB" SG_ 2654486588 CBV_bit0_RepeatMessageRequestBit 0;
BA_ "GenSigTimeoutTime_MCPA" SG_ 2654486588 CBV_bit0_RepeatMessageRequestBit 0;
BA_ "GenSigTimeoutTime_IDCM" SG_ 2654486588 CBV_bit0_RepeatMessageRequestBit 0;
BA_ "GenSigTimeoutTime_EVCU2" SG_ 2654486588 CBV_bit0_RepeatMessageRequestBit 0;
BA_ "GenSigTimeoutTime_ECM" SG_ 2654486588 CBV_bit0_RepeatMessageRequestBit 0;
BA_ "GenSigTimeoutTime_DMPI" SG_ 2654486588 CBV_bit0_RepeatMessageRequestBit 0;
BA_ "GenSigTimeoutTime_BPCM" SG_ 2654486588 CBV_bit0_RepeatMessageRequestBit 0;
BA_ "GenSigTimeoutTime_PBWM" SG_ 2654486588 CBV_bit1 0;
BA_ "GenSigTimeoutTime_MCPB" SG_ 2654486588 CBV_bit1 0;
BA_ "GenSigTimeoutTime_MCPA" SG_ 2654486588 CBV_bit1 0;
BA_ "GenSigTimeoutTime_IDCM" SG_ 2654486588 CBV_bit1 0;
BA_ "GenSigTimeoutTime_EVCU2" SG_ 2654486588 CBV_bit1 0;
BA_ "GenSigTimeoutTime_ECM" SG_ 2654486588 CBV_bit1 0;
BA_ "GenSigTimeoutTime_DMPI" SG_ 2654486588 CBV_bit1 0;
BA_ "GenSigTimeoutTime_BPCM" SG_ 2654486588 CBV_bit1 0;
BA_ "GenSigTimeoutTime_PBWM" SG_ 2654486588 CBV_bit2 0;
BA_ "GenSigTimeoutTime_MCPB" SG_ 2654486588 CBV_bit2 0;
BA_ "GenSigTimeoutTime_MCPA" SG_ 2654486588 CBV_bit2 0;
BA_ "GenSigTimeoutTime_IDCM" SG_ 2654486588 CBV_bit2 0;
BA_ "GenSigTimeoutTime_EVCU2" SG_ 2654486588 CBV_bit2 0;
BA_ "GenSigTimeoutTime_ECM" SG_ 2654486588 CBV_bit2 0;
BA_ "GenSigTimeoutTime_DMPI" SG_ 2654486588 CBV_bit2 0;
BA_ "GenSigTimeoutTime_BPCM" SG_ 2654486588 CBV_bit2 0;
BA_ "GenSigTimeoutTime_PBWM" SG_ 2654486588 CBV_bit3_NMCoordinatorBit 0;
BA_ "GenSigTimeoutTime_MCPB" SG_ 2654486588 CBV_bit3_NMCoordinatorBit 0;
BA_ "GenSigTimeoutTime_MCPA" SG_ 2654486588 CBV_bit3_NMCoordinatorBit 0;
BA_ "GenSigTimeoutTime_IDCM" SG_ 2654486588 CBV_bit3_NMCoordinatorBit 0;
BA_ "GenSigTimeoutTime_EVCU2" SG_ 2654486588 CBV_bit3_NMCoordinatorBit 0;
BA_ "GenSigTimeoutTime_ECM" SG_ 2654486588 CBV_bit3_NMCoordinatorBit 0;
BA_ "GenSigTimeoutTime_DMPI" SG_ 2654486588 CBV_bit3_NMCoordinatorBit 0;
BA_ "GenSigTimeoutTime_BPCM" SG_ 2654486588 CBV_bit3_NMCoordinatorBit 0;
BA_ "GenSigTimeoutTime_PBWM" SG_ 2654486588 CBV_bit4_ActiveWakeupBit 0;
BA_ "GenSigTimeoutTime_MCPB" SG_ 2654486588 CBV_bit4_ActiveWakeupBit 0;
BA_ "GenSigTimeoutTime_MCPA" SG_ 2654486588 CBV_bit4_ActiveWakeupBit 0;
BA_ "GenSigTimeoutTime_IDCM" SG_ 2654486588 CBV_bit4_ActiveWakeupBit 0;
BA_ "GenSigTimeoutTime_EVCU2" SG_ 2654486588 CBV_bit4_ActiveWakeupBit 0;
BA_ "GenSigTimeoutTime_ECM" SG_ 2654486588 CBV_bit4_ActiveWakeupBit 0;
BA_ "GenSigTimeoutTime_DMPI" SG_ 2654486588 CBV_bit4_ActiveWakeupBit 0;
BA_ "GenSigTimeoutTime_BPCM" SG_ 2654486588 CBV_bit4_ActiveWakeupBit 0;
BA_ "GenSigTimeoutTime_PBWM" SG_ 2654486588 CBV_bit5 0;
BA_ "GenSigTimeoutTime_MCPB" SG_ 2654486588 CBV_bit5 0;
BA_ "GenSigTimeoutTime_MCPA" SG_ 2654486588 CBV_bit5 0;
BA_ "GenSigTimeoutTime_IDCM" SG_ 2654486588 CBV_bit5 0;
BA_ "GenSigTimeoutTime_EVCU2" SG_ 2654486588 CBV_bit5 0;
BA_ "GenSigTimeoutTime_ECM" SG_ 2654486588 CBV_bit5 0;
BA_ "GenSigTimeoutTime_DMPI" SG_ 2654486588 CBV_bit5 0;
BA_ "GenSigTimeoutTime_BPCM" SG_ 2654486588 CBV_bit5 0;
BA_ "GenSigTimeoutTime_PBWM" SG_ 2654486588 CBV_bit6_PartialNtwInfBit 0;
BA_ "GenSigTimeoutTime_MCPB" SG_ 2654486588 CBV_bit6_PartialNtwInfBit 0;
BA_ "GenSigTimeoutTime_MCPA" SG_ 2654486588 CBV_bit6_PartialNtwInfBit 0;
BA_ "GenSigTimeoutTime_IDCM" SG_ 2654486588 CBV_bit6_PartialNtwInfBit 0;
BA_ "GenSigTimeoutTime_EVCU2" SG_ 2654486588 CBV_bit6_PartialNtwInfBit 0;
BA_ "GenSigTimeoutTime_ECM" SG_ 2654486588 CBV_bit6_PartialNtwInfBit 0;
BA_ "GenSigTimeoutTime_DMPI" SG_ 2654486588 CBV_bit6_PartialNtwInfBit 0;
BA_ "GenSigTimeoutTime_BPCM" SG_ 2654486588 CBV_bit6_PartialNtwInfBit 0;
BA_ "GenSigTimeoutTime_PBWM" SG_ 2654486588 CBV_bit7 0;
BA_ "GenSigTimeoutTime_MCPB" SG_ 2654486588 CBV_bit7 0;
BA_ "GenSigTimeoutTime_MCPA" SG_ 2654486588 CBV_bit7 0;
BA_ "GenSigTimeoutTime_IDCM" SG_ 2654486588 CBV_bit7 0;
BA_ "GenSigTimeoutTime_EVCU2" SG_ 2654486588 CBV_bit7 0;
BA_ "GenSigTimeoutTime_ECM" SG_ 2654486588 CBV_bit7 0;
BA_ "GenSigTimeoutTime_DMPI" SG_ 2654486588 CBV_bit7 0;
BA_ "GenSigTimeoutTime_BPCM" SG_ 2654486588 CBV_bit7 0;
BA_ "GenSigTimeoutTime_PBWM" SG_ 2654486588 SourceNodeIdentifier 0;
BA_ "GenSigTimeoutTime_MCPB" SG_ 2654486588 SourceNodeIdentifier 0;
BA_ "GenSigTimeoutTime_MCPA" SG_ 2654486588 SourceNodeIdentifier 0;
BA_ "GenSigTimeoutTime_IDCM" SG_ 2654486588 SourceNodeIdentifier 0;
BA_ "GenSigTimeoutTime_EVCU2" SG_ 2654486588 SourceNodeIdentifier 0;
BA_ "GenSigTimeoutTime_ECM" SG_ 2654486588 SourceNodeIdentifier 0;
BA_ "GenSigTimeoutTime_DMPI" SG_ 2654486588 SourceNodeIdentifier 0;
BA_ "GenSigTimeoutTime_BPCM" SG_ 2654486588 SourceNodeIdentifier 0;
BA_ "GenSigTimeoutTime_IDCM" SG_ 504 MCPB_DC_Current_P 0;
BA_ "GenSigTimeoutTime_ECM" SG_ 504 MCPB_DC_Current_P 0;
BA_ "GenSigTimeoutTime_DMPI" SG_ 504 MCPB_DC_Current_P 0;
BA_ "GenSigStartValue" SG_ 504 MCPB_DC_Current_P 16384;
BA_ "GenSigTimeoutTime_PBWM" SG_ 504 MCPB_DC_Current_V_P 0;
BA_ "GenSigTimeoutTime_MCPB" SG_ 504 MCPB_DC_Current_V_P 0;
BA_ "GenSigTimeoutTime_MCPA" SG_ 504 MCPB_DC_Current_V_P 0;
BA_ "GenSigTimeoutTime_IDCM" SG_ 504 MCPB_DC_Current_V_P 0;
BA_ "GenSigTimeoutTime_ECM" SG_ 504 MCPB_DC_Current_V_P 0;
BA_ "GenSigTimeoutTime_DMPI" SG_ 504 MCPB_DC_Current_V_P 0;
BA_ "GenSigTimeoutTime_BPCM" SG_ 504 MCPB_DC_Current_V_P 0;
BA_ "GenSigTimeoutTime_PBWM" SG_ 504 MCPB_DC_Volt_V_P 0;
BA_ "GenSigTimeoutTime_MCPB" SG_ 504 MCPB_DC_Volt_V_P 0;
BA_ "GenSigTimeoutTime_MCPA" SG_ 504 MCPB_DC_Volt_V_P 0;
BA_ "GenSigTimeoutTime_IDCM" SG_ 504 MCPB_DC_Volt_V_P 0;
BA_ "GenSigTimeoutTime_ECM" SG_ 504 MCPB_DC_Volt_V_P 0;
BA_ "GenSigTimeoutTime_DMPI" SG_ 504 MCPB_DC_Volt_V_P 0;
BA_ "GenSigTimeoutTime_BPCM" SG_ 504 MCPB_DC_Volt_V_P 0;
BA_ "GenSigTimeoutTime_PBWM" SG_ 504 MCPB_DC_Voltage_P 0;
BA_ "GenSigTimeoutTime_MCPB" SG_ 504 MCPB_DC_Voltage_P 0;
BA_ "GenSigTimeoutTime_MCPA" SG_ 504 MCPB_DC_Voltage_P 0;
BA_ "GenSigTimeoutTime_IDCM" SG_ 504 MCPB_DC_Voltage_P 0;
BA_ "GenSigTimeoutTime_ECM" SG_ 504 MCPB_DC_Voltage_P 0;
BA_ "GenSigTimeoutTime_DMPI" SG_ 504 MCPB_DC_Voltage_P 0;
BA_ "GenSigTimeoutTime_BPCM" SG_ 504 MCPB_DC_Voltage_P 0;
BA_ "GenSigTimeoutTime_PBWM" SG_ 504 MCPB_DerateReason_P 0;
BA_ "GenSigTimeoutTime_MCPB" SG_ 504 MCPB_DerateReason_P 0;
BA_ "GenSigTimeoutTime_MCPA" SG_ 504 MCPB_DerateReason_P 0;
BA_ "GenSigTimeoutTime_IDCM" SG_ 504 MCPB_DerateReason_P 0;
BA_ "GenSigTimeoutTime_ECM" SG_ 504 MCPB_DerateReason_P 0;
BA_ "GenSigTimeoutTime_DMPI" SG_ 504 MCPB_DerateReason_P 0;
BA_ "GenSigTimeoutTime_BPCM" SG_ 504 MCPB_DerateReason_P 0;
BA_ "GenSigTimeoutTime_PBWM" SG_ 294 MCPB_MtrMaxCpbltyTrq_P 0;
BA_ "GenSigTimeoutTime_MCPB" SG_ 294 MCPB_MtrMaxCpbltyTrq_P 0;
BA_ "GenSigTimeoutTime_MCPA" SG_ 294 MCPB_MtrMaxCpbltyTrq_P 0;
BA_ "GenSigTimeoutTime_IDCM" SG_ 294 MCPB_MtrMaxCpbltyTrq_P 0;
BA_ "GenSigTimeoutTime_PBWM" SG_ 504 MCPB_PIM_DC_Side_Busbar_Temp_P 0;
BA_ "GenSigTimeoutTime_MCPB" SG_ 504 MCPB_PIM_DC_Side_Busbar_Temp_P 0;
BA_ "GenSigTimeoutTime_MCPA" SG_ 504 MCPB_PIM_DC_Side_Busbar_Temp_P 0;
BA_ "GenSigTimeoutTime_IDCM" SG_ 504 MCPB_PIM_DC_Side_Busbar_Temp_P 0;
BA_ "GenSigTimeoutTime_ECM" SG_ 504 MCPB_PIM_DC_Side_Busbar_Temp_P 0;
BA_ "GenSigTimeoutTime_DMPI" SG_ 504 MCPB_PIM_DC_Side_Busbar_Temp_P 0;
BA_ "GenSigTimeoutTime_BPCM" SG_ 504 MCPB_PIM_DC_Side_Busbar_Temp_P 0;
BA_ "GenSigTimeoutTime_PBWM" SG_ 504 MCPB_Inverter_Temp_P 0;
BA_ "GenSigTimeoutTime_MCPB" SG_ 504 MCPB_Inverter_Temp_P 0;
BA_ "GenSigTimeoutTime_MCPA" SG_ 504 MCPB_Inverter_Temp_P 0;
BA_ "GenSigTimeoutTime_IDCM" SG_ 504 MCPB_Inverter_Temp_P 0;
BA_ "GenSigTimeoutTime_ECM" SG_ 504 MCPB_Inverter_Temp_P 0;
BA_ "GenSigTimeoutTime_DMPI" SG_ 504 MCPB_Inverter_Temp_P 0;
BA_ "GenSigTimeoutTime_BPCM" SG_ 504 MCPB_Inverter_Temp_P 0;
BA_ "GenSigStartValue" SG_ 504 MCPB_Inverter_Temp_P 40;
BA_ "GenSigTimeoutTime_PBWM" SG_ 294 MCPB_Temp_P 0;
BA_ "GenSigTimeoutTime_MCPB" SG_ 294 MCPB_Temp_P 0;
BA_ "GenSigTimeoutTime_MCPA" SG_ 294 MCPB_Temp_P 0;
BA_ "GenSigTimeoutTime_IDCM" SG_ 294 MCPB_Temp_P 0;
BA_ "GenSigTimeoutTime_ECM" SG_ 294 MCPB_Temp_P 0;
BA_ "GenSigTimeoutTime_DMPI" SG_ 294 MCPB_Temp_P 0;
BA_ "GenSigTimeoutTime_BPCM" SG_ 294 MCPB_Temp_P 0;
BA_ "GenSigStartValue" SG_ 294 MCPB_Temp_P 40;
BA_ "GenSigTimeoutTime_PBWM" SG_ 504 MCPB_Control_Board_Temperature_P 0;
BA_ "GenSigTimeoutTime_MCPB" SG_ 504 MCPB_Control_Board_Temperature_P 0;
BA_ "GenSigTimeoutTime_MCPA" SG_ 504 MCPB_Control_Board_Temperature_P 0;
BA_ "GenSigTimeoutTime_IDCM" SG_ 504 MCPB_Control_Board_Temperature_P 0;
BA_ "GenSigTimeoutTime_ECM" SG_ 504 MCPB_Control_Board_Temperature_P 0;
BA_ "GenSigTimeoutTime_DMPI" SG_ 504 MCPB_Control_Board_Temperature_P 0;
BA_ "GenSigTimeoutTime_BPCM" SG_ 504 MCPB_Control_Board_Temperature_P 0;
BA_ "GenSigTimeoutTime_PBWM" SG_ 504 CLrDiagInfo_MCPB_P 0;
BA_ "GenSigTimeoutTime_MCPB" SG_ 504 CLrDiagInfo_MCPB_P 0;
BA_ "GenSigTimeoutTime_MCPA" SG_ 504 CLrDiagInfo_MCPB_P 0;
BA_ "GenSigTimeoutTime_IDCM" SG_ 504 CLrDiagInfo_MCPB_P 0;
BA_ "GenSigTimeoutTime_ECM" SG_ 504 CLrDiagInfo_MCPB_P 0;
BA_ "GenSigTimeoutTime_DMPI" SG_ 504 CLrDiagInfo_MCPB_P 0;
BA_ "GenSigTimeoutTime_BPCM" SG_ 504 CLrDiagInfo_MCPB_P 0;
BA_ "GenSigTimeoutTime_PBWM" SG_ 504 MCPB_Service_Lamp_Request_P 0;
BA_ "GenSigTimeoutTime_MCPB" SG_ 504 MCPB_Service_Lamp_Request_P 0;
BA_ "GenSigTimeoutTime_MCPA" SG_ 504 MCPB_Service_Lamp_Request_P 0;
BA_ "GenSigTimeoutTime_IDCM" SG_ 504 MCPB_Service_Lamp_Request_P 0;
BA_ "GenSigTimeoutTime_ECM" SG_ 504 MCPB_Service_Lamp_Request_P 0;
BA_ "GenSigTimeoutTime_DMPI" SG_ 504 MCPB_Service_Lamp_Request_P 0;
BA_ "GenSigTimeoutTime_BPCM" SG_ 504 MCPB_Service_Lamp_Request_P 0;
BA_ "GenSigTimeoutTime_PBWM" SG_ 504 MCPB_Rotor_Temperature_P 0;
BA_ "GenSigTimeoutTime_MCPB" SG_ 504 MCPB_Rotor_Temperature_P 0;
BA_ "GenSigTimeoutTime_MCPA" SG_ 504 MCPB_Rotor_Temperature_P 0;
BA_ "GenSigTimeoutTime_IDCM" SG_ 504 MCPB_Rotor_Temperature_P 0;
BA_ "GenSigTimeoutTime_ECM" SG_ 504 MCPB_Rotor_Temperature_P 0;
BA_ "GenSigTimeoutTime_DMPI" SG_ 504 MCPB_Rotor_Temperature_P 0;
BA_ "GenSigTimeoutTime_BPCM" SG_ 504 MCPB_Rotor_Temperature_P 0;
BA_ "GenSigStartValue" SG_ 504 MCPB_Rotor_Temperature_P 255;
BA_ "GenSigTimeoutTime_PBWM" SG_ 1065 MessageCounter_MCPB_OBD_DTC 0;
BA_ "GenSigTimeoutTime_MCPB" SG_ 1065 MessageCounter_MCPB_OBD_DTC 0;
BA_ "GenSigTimeoutTime_MCPA" SG_ 1065 MessageCounter_MCPB_OBD_DTC 0;
BA_ "GenSigTimeoutTime_IDCM" SG_ 1065 MessageCounter_MCPB_OBD_DTC 0;
BA_ "GenSigTimeoutTime_ECM" SG_ 1065 MessageCounter_MCPB_OBD_DTC 0;
BA_ "GenSigTimeoutTime_DMPI" SG_ 1065 MessageCounter_MCPB_OBD_DTC 0;
BA_ "GenSigTimeoutTime_BPCM" SG_ 1065 MessageCounter_MCPB_OBD_DTC 0;
BA_ "GenSigTimeoutTime_PBWM" SG_ 1065 MCPB_DTC_Stat1 0;
BA_ "GenSigTimeoutTime_MCPB" SG_ 1065 MCPB_DTC_Stat1 0;
BA_ "GenSigTimeoutTime_MCPA" SG_ 1065 MCPB_DTC_Stat1 0;
BA_ "GenSigTimeoutTime_IDCM" SG_ 1065 MCPB_DTC_Stat1 0;
BA_ "GenSigTimeoutTime_ECM" SG_ 1065 MCPB_DTC_Stat1 0;
BA_ "GenSigTimeoutTime_DMPI" SG_ 1065 MCPB_DTC_Stat1 0;
BA_ "GenSigTimeoutTime_BPCM" SG_ 1065 MCPB_DTC_Stat1 0;
BA_ "GenSigTimeoutTime_PBWM" SG_ 1065 MCPB_DTC_Stat2 0;
BA_ "GenSigTimeoutTime_MCPB" SG_ 1065 MCPB_DTC_Stat2 0;
BA_ "GenSigTimeoutTime_MCPA" SG_ 1065 MCPB_DTC_Stat2 0;
BA_ "GenSigTimeoutTime_IDCM" SG_ 1065 MCPB_DTC_Stat2 0;
BA_ "GenSigTimeoutTime_ECM" SG_ 1065 MCPB_DTC_Stat2 0;
BA_ "GenSigTimeoutTime_DMPI" SG_ 1065 MCPB_DTC_Stat2 0;
BA_ "GenSigTimeoutTime_BPCM" SG_ 1065 MCPB_DTC_Stat2 0;
BA_ "GenSigTimeoutTime_PBWM" SG_ 1065 MCPB_Cal_ID_Idx 0;
BA_ "GenSigTimeoutTime_MCPB" SG_ 1065 MCPB_Cal_ID_Idx 0;
BA_ "GenSigTimeoutTime_MCPA" SG_ 1065 MCPB_Cal_ID_Idx 0;
BA_ "GenSigTimeoutTime_IDCM" SG_ 1065 MCPB_Cal_ID_Idx 0;
BA_ "GenSigTimeoutTime_ECM" SG_ 1065 MCPB_Cal_ID_Idx 0;
BA_ "GenSigTimeoutTime_DMPI" SG_ 1065 MCPB_Cal_ID_Idx 0;
BA_ "GenSigTimeoutTime_BPCM" SG_ 1065 MCPB_Cal_ID_Idx 0;
BA_ "GenSigTimeoutTime_PBWM" SG_ 1065 MCPB_CalChar 0;
BA_ "GenSigTimeoutTime_MCPB" SG_ 1065 MCPB_CalChar 0;
BA_ "GenSigTimeoutTime_MCPA" SG_ 1065 MCPB_CalChar 0;
BA_ "GenSigTimeoutTime_IDCM" SG_ 1065 MCPB_CalChar 0;
BA_ "GenSigTimeoutTime_ECM" SG_ 1065 MCPB_CalChar 0;
BA_ "GenSigTimeoutTime_DMPI" SG_ 1065 MCPB_CalChar 0;
BA_ "GenSigTimeoutTime_BPCM" SG_ 1065 MCPB_CalChar 0;
BA_ "GenSigTimeoutTime_PBWM" SG_ 1065 MCPB_DTC_Idx1 0;
BA_ "GenSigTimeoutTime_MCPB" SG_ 1065 MCPB_DTC_Idx1 0;
BA_ "GenSigTimeoutTime_MCPA" SG_ 1065 MCPB_DTC_Idx1 0;
BA_ "GenSigTimeoutTime_IDCM" SG_ 1065 MCPB_DTC_Idx1 0;
BA_ "GenSigTimeoutTime_ECM" SG_ 1065 MCPB_DTC_Idx1 0;
BA_ "GenSigTimeoutTime_DMPI" SG_ 1065 MCPB_DTC_Idx1 0;
BA_ "GenSigTimeoutTime_BPCM" SG_ 1065 MCPB_DTC_Idx1 0;
BA_ "GenSigTimeoutTime_PBWM" SG_ 1065 MCPB_DTC_Idx2 0;
BA_ "GenSigTimeoutTime_MCPB" SG_ 1065 MCPB_DTC_Idx2 0;
BA_ "GenSigTimeoutTime_MCPA" SG_ 1065 MCPB_DTC_Idx2 0;
BA_ "GenSigTimeoutTime_IDCM" SG_ 1065 MCPB_DTC_Idx2 0;
BA_ "GenSigTimeoutTime_ECM" SG_ 1065 MCPB_DTC_Idx2 0;
BA_ "GenSigTimeoutTime_DMPI" SG_ 1065 MCPB_DTC_Idx2 0;
BA_ "GenSigTimeoutTime_BPCM" SG_ 1065 MCPB_DTC_Idx2 0;
BA_ "GenSigTimeoutTime_ECM" SG_ 294 MCPB_MtrMaxCpbltyTrq_P 0;
BA_ "GenSigTimeoutTime_DMPI" SG_ 294 MCPB_MtrMaxCpbltyTrq_P 0;
BA_ "GenSigTimeoutTime_BPCM" SG_ 294 MCPB_MtrMaxCpbltyTrq_P 0;
BA_ "GenSigTimeoutTime_IDCM" SG_ 296 ShiftLeverPosition_P 0;
BA_ "GenSigTimeoutTime_EVCU2" SG_ 296 ShiftLeverPosition_P 0;
BA_ "GenSigTimeoutTime_ECM" SG_ 296 ShiftLeverPosition_P 0;
BA_ "GenSigTimeoutTime_DMPI" SG_ 296 ShiftLeverPosition_P 0;
BA_ "GenSigTimeoutTime_BPCM" SG_ 296 ShiftLeverPosition_P 0;
BA_ "GenSigTimeoutTime_PBWM" SG_ 296 ParkCmd_PT_P 0;
BA_ "GenSigTimeoutTime_MCPA" SG_ 296 ParkCmd_PT_P 0;
BA_ "GenSigTimeoutTime_IDCM" SG_ 296 ParkCmd_PT_P 0;
BA_ "GenSigTimeoutTime_EVCU2" SG_ 296 ParkCmd_PT_P 0;
BA_ "GenSigTimeoutTime_ECM" SG_ 296 ParkCmd_PT_P 0;
BA_ "GenSigTimeoutTime_DMPI" SG_ 296 ParkCmd_PT_P 0;
BA_ "GenSigTimeoutTime_BPCM" SG_ 296 ParkCmd_PT_P 0;
BA_ "GenSigTimeoutTime_PBWM" SG_ 296 Mtr_6SO_Request_MCPB_P 0;
BA_ "GenSigTimeoutTime_MCPA" SG_ 296 Mtr_6SO_Request_MCPB_P 0;
BA_ "GenSigTimeoutTime_IDCM" SG_ 296 Mtr_6SO_Request_MCPB_P 0;
BA_ "GenSigTimeoutTime_EVCU2" SG_ 296 Mtr_6SO_Request_MCPB_P 0;
BA_ "GenSigTimeoutTime_ECM" SG_ 296 Mtr_6SO_Request_MCPB_P 0;
BA_ "GenSigTimeoutTime_DMPI" SG_ 296 Mtr_6SO_Request_MCPB_P 0;
BA_ "GenSigTimeoutTime_BPCM" SG_ 296 Mtr_6SO_Request_MCPB_P 0;
BA_ "GenSigTimeoutTime_PBWM" SG_ 296 Mtr_6SO_Request_MCPA_P 0;
BA_ "GenSigTimeoutTime_MCPB" SG_ 296 Mtr_6SO_Request_MCPA_P 0;
BA_ "GenSigTimeoutTime_IDCM" SG_ 296 Mtr_6SO_Request_MCPA_P 0;
BA_ "GenSigTimeoutTime_EVCU2" SG_ 296 Mtr_6SO_Request_MCPA_P 0;
BA_ "GenSigTimeoutTime_ECM" SG_ 296 Mtr_6SO_Request_MCPA_P 0;
BA_ "GenSigTimeoutTime_DMPI" SG_ 296 Mtr_6SO_Request_MCPA_P 0;
BA_ "GenSigTimeoutTime_BPCM" SG_ 296 Mtr_6SO_Request_MCPA_P 0;
BA_ "GenSigTimeoutTime_PBWM" SG_ 296 ModeCommand_MCPB_P 0;
BA_ "GenSigTimeoutTime_MCPA" SG_ 296 ModeCommand_MCPB_P 0;
BA_ "GenSigTimeoutTime_IDCM" SG_ 296 ModeCommand_MCPB_P 0;
BA_ "GenSigTimeoutTime_EVCU2" SG_ 296 ModeCommand_MCPB_P 0;
BA_ "GenSigTimeoutTime_ECM" SG_ 296 ModeCommand_MCPB_P 0;
BA_ "GenSigTimeoutTime_DMPI" SG_ 296 ModeCommand_MCPB_P 0;
BA_ "GenSigTimeoutTime_BPCM" SG_ 296 ModeCommand_MCPB_P 0;
BA_ "GenSigTimeoutTime_PBWM" SG_ 296 ModeCommand_MCPA_P 0;
BA_ "GenSigTimeoutTime_MCPB" SG_ 296 ModeCommand_MCPA_P 0;
BA_ "GenSigTimeoutTime_IDCM" SG_ 296 ModeCommand_MCPA_P 0;
BA_ "GenSigTimeoutTime_EVCU2" SG_ 296 ModeCommand_MCPA_P 0;
BA_ "GenSigTimeoutTime_ECM" SG_ 296 ModeCommand_MCPA_P 0;
BA_ "GenSigTimeoutTime_DMPI" SG_ 296 ModeCommand_MCPA_P 0;
BA_ "GenSigTimeoutTime_BPCM" SG_ 296 ModeCommand_MCPA_P 0;
BA_ "GenSigTimeoutTime_PBWM" SG_ 296 MC_INVTARGET_PROPULSION1 0;
BA_ "GenSigTimeoutTime_IDCM" SG_ 296 MC_INVTARGET_PROPULSION1 0;
BA_ "GenSigTimeoutTime_EVCU2" SG_ 296 MC_INVTARGET_PROPULSION1 0;
BA_ "GenSigTimeoutTime_ECM" SG_ 296 MC_INVTARGET_PROPULSION1 0;
BA_ "GenSigTimeoutTime_DMPI" SG_ 296 MC_INVTARGET_PROPULSION1 0;
BA_ "GenSigTimeoutTime_BPCM" SG_ 296 MC_INVTARGET_PROPULSION1 0;
BA_ "GenSigTimeoutTime_PBWM" SG_ 296 CRC_INVTARGET_PROPULSION1 0;
BA_ "GenSigTimeoutTime_IDCM" SG_ 296 CRC_INVTARGET_PROPULSION1 0;
BA_ "GenSigTimeoutTime_EVCU2" SG_ 296 CRC_INVTARGET_PROPULSION1 0;
BA_ "GenSigTimeoutTime_ECM" SG_ 296 CRC_INVTARGET_PROPULSION1 0;
BA_ "GenSigTimeoutTime_DMPI" SG_ 296 CRC_INVTARGET_PROPULSION1 0;
BA_ "GenSigTimeoutTime_BPCM" SG_ 296 CRC_INVTARGET_PROPULSION1 0;
BA_ "GenSigTimeoutTime_PBWM" SG_ 296 CmdIgnSts_P 0;
BA_ "GenSigTimeoutTime_IDCM" SG_ 296 CmdIgnSts_P 0;
BA_ "GenSigTimeoutTime_EVCU2" SG_ 296 CmdIgnSts_P 0;
BA_ "GenSigTimeoutTime_ECM" SG_ 296 CmdIgnSts_P 0;
BA_ "GenSigTimeoutTime_DMPI" SG_ 296 CmdIgnSts_P 0;
BA_ "GenSigTimeoutTime_BPCM" SG_ 296 CmdIgnSts_P 0;
BA_ "GenSigTimeoutTime_PBWM" SG_ 296 BPCM_HV_TractionBusVoltage_P 0;
BA_ "GenSigTimeoutTime_IDCM" SG_ 296 BPCM_HV_TractionBusVoltage_P 0;
BA_ "GenSigTimeoutTime_EVCU2" SG_ 296 BPCM_HV_TractionBusVoltage_P 0;
BA_ "GenSigTimeoutTime_ECM" SG_ 296 BPCM_HV_TractionBusVoltage_P 0;
BA_ "GenSigTimeoutTime_DMPI" SG_ 296 BPCM_HV_TractionBusVoltage_P 0;
BA_ "GenSigTimeoutTime_BPCM" SG_ 296 BPCM_HV_TractionBusVoltage_P 0;
BA_ "GenSigTimeoutTime_PBWM" SG_ 296 BPCM_HV_Trac_Main_Contac_Sts_P 0;
BA_ "GenSigTimeoutTime_IDCM" SG_ 296 BPCM_HV_Trac_Main_Contac_Sts_P 0;
BA_ "GenSigTimeoutTime_EVCU2" SG_ 296 BPCM_HV_Trac_Main_Contac_Sts_P 0;
BA_ "GenSigTimeoutTime_ECM" SG_ 296 BPCM_HV_Trac_Main_Contac_Sts_P 0;
BA_ "GenSigTimeoutTime_DMPI" SG_ 296 BPCM_HV_Trac_Main_Contac_Sts_P 0;
BA_ "GenSigTimeoutTime_BPCM" SG_ 296 BPCM_HV_Trac_Main_Contac_Sts_P 0;
BA_ "GenSigTimeoutTime_PBWM" SG_ 296 AEMD_MinOffset_MCPB_P 0;
BA_ "GenSigTimeoutTime_MCPA" SG_ 296 AEMD_MinOffset_MCPB_P 0;
BA_ "GenSigTimeoutTime_IDCM" SG_ 296 AEMD_MinOffset_MCPB_P 0;
BA_ "GenSigTimeoutTime_EVCU2" SG_ 296 AEMD_MinOffset_MCPB_P 0;
BA_ "GenSigTimeoutTime_ECM" SG_ 296 AEMD_MinOffset_MCPB_P 0;
BA_ "GenSigTimeoutTime_DMPI" SG_ 296 AEMD_MinOffset_MCPB_P 0;
BA_ "GenSigTimeoutTime_BPCM" SG_ 296 AEMD_MinOffset_MCPB_P 0;
BA_ "GenSigStartValue" SG_ 296 AEMD_MinOffset_MCPB_P 8184;
VAL_ 2654486594 CBV_bit6_PartialNtwInfBit 0 "NM PDU contains no Partial Network request information" 1 "NM PDU contains Partial Network request information";
VAL_ 2654486588 CBV_bit6_PartialNtwInfBit 0 "NM PDU contains no Partial Network request information" 1 "NM PDU contains Partial Network request information";
VAL_ 2654486594 CBV_bit4_ActiveWakeupBit 0 "PassiveWakeup" 1 "ActiveWakeup";
VAL_ 2654486588 CBV_bit4_ActiveWakeupBit 0 "PassiveWakeup" 1 "ActiveWakeup";
VAL_ 2654486588 CBV_bit3_NMCoordinatorBit 0 "Start of synchronized shutdown is not requested by main coordinator" 1 "Start of synchronized shutdown is requested by main coordinator";
VAL_ 2654486594 CBV_bit3_NMCoordinatorBit 0 "Start of synchronized shutdown is not requested by main coordinator" 1 "Start of synchronized shutdown is requested by main coordinator";
VAL_ 2654486594 CBV_bit0_RepeatMessageRequestBit 0 "Repeat Message State not requested" 1 "Repeat Message State requested";
VAL_ 2654486588 CBV_bit0_RepeatMessageRequestBit 0 "Repeat Message State not requested" 1 "Repeat Message State requested";
VAL_ 214 Mtr_6SO_Request_MCPB_2 0 "False" 1 "True";
VAL_ 214 Mtr_6SO_Request_MCPA_2 0 "False" 1 "True";
VAL_ 214 ModeCommand_MCPB_2 0 "Inverter_Disabled" 1 "Torque_Control" 2 "Speed_Control" 3 "Active_Discharge" 4 "Disable_Immediate" 5 "Voltage_Control" 6 "Rapid_Shutdown" 7 "Shutdown_Initiated" 8 "ROL_Routine" 9 "Active_Short_Circuit" 15 "SNA";
VAL_ 214 ModeCommand_MCPA_2 0 "Inverter_Disabled" 1 "Torque_Control" 2 "Speed_Control" 3 "Active_Discharge" 4 "Disable_Immediate" 5 "Voltage_Control" 6 "0x6 Rapid_Shutdown" 7 "Shutdown_Initiated" 8 "ROL_Routine" 9 "Active_Short_Circuit" 15 "SNA";
VAL_ 214 MinTorque_Limit_MCPB_2 16383 "SNA";
VAL_ 214 MinTorque_Limit_MCPA_2 16383 "SNA";
VAL_ 214 MaxTorque_Limit_MCPB_2 16383 "SNA";
VAL_ 214 MaxTorque_Limit_MCPA_2 16383 "SNA";
VAL_ 214 HVBatVlt_V_2 0 "Valid" 1 "Invalid";
VAL_ 214 EVCU_END_Request_Flag_2 0 "No_Request" 1 "Request";
VAL_ 1065 MCPB_DTC_Stat2 0 "Not_Supported" 1 "Critically_disabled" 2 "No_status_to_report" 3 "Diagnostic_passed" 4 "Diagnostic_failed" 5 "Reset_DTC_status" 7 "SNA";
VAL_ 1065 MCPB_DTC_Stat1 0 "Not_Supported" 1 "Critically_disabled" 2 "No_status_to_report" 3 "Diagnostic_passed" 4 "Diagnostic_failed" 5 "Reset_DTC_status" 7 "SNA";
VAL_ 1065 MCPB_DTC_Idx2 31 "SNA";
VAL_ 1065 MCPB_DTC_Idx1 31 "SNA";
VAL_ 1065 MCPB_CalChar 255 "SNA";
VAL_ 1065 MCPB_Cal_ID_Idx 63 "SNA";
VAL_ 1057 MCPA_DTC_Stat2 0 "Not_Supported" 1 "Critically_disabled" 2 "No_status_to_report" 3 "Diagnostic_passed" 4 "Diagnostic_failed" 5 "Reset_DTC_status" 7 "SNA";
VAL_ 1057 MCPA_DTC_Stat1 0 "Not_Supported" 1 "Critically_disabled" 2 "No_status_to_report" 3 "Diagnostic_passed" 4 "Diagnostic_failed" 5 "Reset_DTC_status" 7 "SNA";
VAL_ 1057 MCPA_DTC_Idx2 31 "SNA";
VAL_ 1057 MCPA_DTC_Idx1 31 "SNA";
VAL_ 1057 MCPA_CalChar 255 "SNA";
VAL_ 1057 MCPA_Cal_ID_Idx 63 "SNA";
VAL_ 504 MCPB_DerateReason_P 0 "Reason1" 1 "Reason2" 2 "Reason3" 3 "Reason4" 4 "Reason5" 5 "Reason6" 6 "Reason7" 7 "Reason8" 8 "Reason9" 9 "Reason10" 10 "Reason11" 11 "Reason12" 12 "Reason13" 13 "Reason14" 14 "Reason15" 15 "Reason16";
VAL_ 504 MCPB_DC_Voltage_P 1023 "SNA";
VAL_ 504 MCPB_DC_Volt_V_P 0 "Valid" 1 "Invalid";
VAL_ 504 MCPB_DC_Current_V_P 0 "Valid" 1 "Invalid";
VAL_ 504 MCPB_CoolantTemp_P 2047 "SNA";
VAL_ 294 PlockFailSts_P 0 "Fault_Not_Present" 1 "Derating" 2 "Retrying" 3 "Non recoverable critical fault" 7 "SNA";
VAL_ 294 Plock_PosSensor_P 0 "Init" 1 "Unknown" 2 "Engaged" 3 "Between Engaged and Disengaged" 4 "Tooth to Tooth" 5 "Disengaged" 7 "SNA";
VAL_ 294 Plock_MotorPosSts_P 0 "Init" 1 "Unknown" 2 "Engaged Endstop" 3 "Engaged" 4 "Between Engaged and Disengaged" 5 "Disengaged" 6 "Disengaged Endstop" 7 "SNA";
VAL_ 294 Plock_fdbk_sts_P 0 "Init" 1 "Engaging" 2 "Engaged" 3 "Disengaging" 4 "Disengaged" 5 "Fault" 7 "SNA";
VAL_ 294 MPR_PosSensor_P 0 "Init" 1 "Unknown" 2 "Engaged" 3 "Disengaged" 7 "SNA";
VAL_ 294 MCPB_Torque_Achieved_V_P 0 "Valid" 1 "Invalid";
VAL_ 294 MCPB_Torque_Achieved_P 16383 "SNA";
VAL_ 294 MCPB_TorqAchieved_AEMD_V_P 0 "Valid" 1 "Invalid";
VAL_ 294 MCPB_TorqAchieved_AEMD_P 16383 "SNA";
VAL_ 294 MCPB_SPT_Stat_P 0 "Undetermined " 1 "Passed" 2 "Failed";
VAL_ 294 MCPB_RPM_V_P 0 "Valid" 1 "Invalid";
VAL_ 294 MCPB_RPM_P 65535 "SNA";
VAL_ 294 MCPB_MtrMinCpbltyTrq_P 16383 "SNA";
VAL_ 294 MCPB_MtrMaxCpbltyTrq_P 16383 "SNA";
VAL_ 294 MCPB_MtrIndex_P 31 "SNA";
VAL_ 294 MCPB_MinTorq_P 16383 "SNA";
VAL_ 294 MCPB_MaxTorq_P 16383 "SNA";
VAL_ 294 MCPB_Invrtr_State_P 0 "NORMAL_POWER_STAGE_OFF " 1 "NORMAL_POWER_STAGE_ON " 2 "NORMAL_POWER_STAGE_OVERRIDE" 3 "ACTIVE_DISCHARGE " 4 "INVERTER_FAULTED " 5 "NORMAL_POWER_STAGE_OFF_HV_RQD" 6 "NORMAL_VC_PRIMING" 7 "NORMAL_VC_ON";
VAL_ 294 MCPB_InterlockSts_P 0 "Not_Performed" 1 "OK" 2 "Fail" 3 "Invalid";
VAL_ 294 MCPB_HV_CnctrOpn_Req_P 0 "False" 1 "True";
VAL_ 294 MCPB_Dschrge_Status_P 0 "AD_INDETERMINATE" 1 "AD_INPROGRESS" 2 "AD_COMPLETE" 3 "AD_FAILED";
VAL_ 294 MCPB_DeratingFactor_P 63 "SNA";
VAL_ 294 MCPB_CpbltySpdDivVolt_P 65535 "SNA";
VAL_ 294 MCPB_AccelRawV_P 0 "Valid" 1 "Invalid";
VAL_ 294 MCPB_6SO_Status_P 0 "ThreePS" 1 "SixSO" 2 "Switching" 3 "SNA";
VAL_ 294 MCPB_3PS_Pos_P 0 "False" 1 "True";
VAL_ 503 MCPA_DerateReason_P 0 "Reason1" 1 "Reason2" 2 "Reason3" 3 "Reason4" 4 "Reason5" 5 "Reason6" 6 "Reason7" 7 "Reason8" 8 "Reason9" 9 "Reason10" 10 "Reason11" 11 "Reason12" 12 "Reason13" 13 "Reason14" 14 "Reason15" 15 "Reason16";
VAL_ 503 MCPA_DC_Voltage_P 1023 "SNA";
VAL_ 503 MCPA_DC_Volt_V_P 0 "Valid" 1 "Invalid";
VAL_ 503 MCPA_DC_Current_V_P 0 "Valid" 1 "Invalid";
VAL_ 503 MCPA_CoolantTemp_P 2047 "SNA";
VAL_ 293 MCPA_Torque_Achieved_V_P 0 "Valid" 1 "Invalid";
VAL_ 293 MCPA_Torque_Achieved_P 16383 "SNA";
VAL_ 293 MCPA_TorqAchieved_AEMD_V_P 0 "Valid" 1 "Invalid";
VAL_ 293 MCPA_TorqAchieved_AEMD_P 16383 "SNA";
VAL_ 293 MCPA_SPT_Stat_P 0 "Undetermined" 1 "Passed" 2 "Failed";
VAL_ 293 MCPA_RPM_V_P 0 "Valid" 1 "Invalid";
VAL_ 293 MCPA_RPM_P 65535 "SNA";
VAL_ 293 MCPA_MtrMinCpbltyTrq_P 16383 "SNA";
VAL_ 293 MCPA_MtrMaxCpbltyTrq_P 16383 "SNA";
VAL_ 293 MCPA_MtrIndex_P 31 "SNA";
VAL_ 293 MCPA_MinTorq_P 16383 "SNA";
VAL_ 293 MCPA_MaxTorq_P 16383 "SNA";
VAL_ 293 MCPA_Invrtr_State_P 0 "NORMAL_POWER_STAGE_OFF" 1 "NORMAL_POWER_STAGE_ON" 2 "NORMAL_POWER_STAGE_OVERRIDE" 3 "ACTIVE_DISCHARGE" 4 "INVERTER_FAULTED" 5 "NORMAL_POWER_STAGE_OFF_HV_RQD" 6 "NORMAL_VC_PRIMING" 7 "NORMAL_VC_ON";
VAL_ 293 MCPA_InterlockSts_P 0 "Not_Performed" 1 "OK" 2 "Fail" 3 "Invalid";
VAL_ 293 MCPA_HV_CnctrOpn_Req_P 0 "False" 1 "True";
VAL_ 293 MCPA_Dschrge_Status_P 0 "AD_INDETERMINATE" 1 "AD_INPROGRESS" 2 "AD_COMPLETE" 3 "AD_FAILED";
VAL_ 293 MCPA_DeratingFactor_P 63 "SNA";
VAL_ 293 MCPA_CpbltySpdDivVolt_P 65535 "SNA";
VAL_ 293 MCPA_AccelRawV_P 0 "Valid" 1 "Invalid";
VAL_ 293 MCPA_6SO_Status_P 0 "ThreePS" 1 "SixSO" 2 "Switching" 3 "SNA";
VAL_ 293 MCPA_3PS_Pos_P 0 "False" 1 "True";
VAL_ 297 Pwr_Electr_Loop_FlwRate_MCPB_P 255 "SNA";
VAL_ 297 Pwr_Electr_Loop_FlwRate_MCPA_P 255 "SNA";
VAL_ 297 EVCU_MotorB_Speed 65535 "SNA";
VAL_ 297 EVCU_MotorA_Speed 65535 "SNA";
VAL_ 296 VehicleSpeedVSOSig_P 8191 "SNA";
VAL_ 296 TorqueCommand_MCPB_P 16383 "SNA";
VAL_ 296 TorqueCommand_MCPA_P 16383 "SNA";
VAL_ 296 ShiftLeverPosition_P 0 "No_Selection_Active_Or_Available" 1 "Park" 2 "Reverse" 3 "Neutral" 4 "Drive" 5 "Low" 6 "TIP_Autostick" 7 "Plus" 8 "Minus" 9 "Sport" 15 "SNA";
VAL_ 296 ParkCmd_PT_P 0 "No_Request" 1 "Disengage" 2 "Engage" 3 "SNA";
VAL_ 296 Mtr_6SO_Request_MCPB_P 0 "False" 1 "True";
VAL_ 296 Mtr_6SO_Request_MCPA_P 0 "False" 1 "True";
VAL_ 296 ModeCommand_MCPB_P 0 "Inverter_Disabled" 1 "Torque_Control" 2 "Speed_Control" 3 "Active_Discharge" 4 "Disable_Immediate" 5 "Voltage_Control" 6 "0x6 Rapid_Shutdown" 7 "Shutdown_Initiated" 8 "ROL_Routine" 9 "Active_Short_Circuit" 15 "SNA";
VAL_ 296 ModeCommand_MCPA_P 0 "Inverter_Disabled" 1 "Torque_Control" 2 "Speed_Control" 3 "Active_Discharge" 4 "Disable_Immediate" 5 "Voltage_Control" 6 "0x6 Rapid_Shutdown" 7 "Shutdown_Initiated" 8 "ROL_Routine" 9 "Active_Short_Circuit" 15 "SNA";
VAL_ 296 CmdIgnSts_P 0 "Initialization" 1 "IGN_LK" 3 "ACC" 4 "RUN" 5 "START" 7 "SNA";
VAL_ 296 BPCM_HV_TractionBusVoltage_P 2047 "SNA";
VAL_ 296 BPCM_HV_Trac_Main_Contac_Sts_P 0 "Open" 1 "Closed" 3 "Error_Stuck_Open" 4 "Error_Stuck_Closed" 7 "SNA";
VAL_ 296 AEMD_MinOffset_MCPB_P 16383 "SNA";
VAL_ 296 AEMD_MinOffset_MCPA_P 16383 "SNA";
VAL_ 296 AEMD_MaxOffset_MCPB_P 16383 "SNA";
VAL_ 296 AEMD_MaxOffset_MCPA_P 16383 "SNA";
VAL_ 294 MCPB_AccelRaw_P 65535 "SNA";
VAL_ 293 MCPA_AccelRaw_P 65535 "SNA";
VAL_ 214 AEMD_Sclr_Gn_MCPB_2 2047 "SNA";
VAL_ 214 AEMD_Sclr_Gn_MCPA_2 2047 "SNA";
VAL_ 296 AEMD_Sclr_Gn_MCPB_P 511 "SNA";
VAL_ 296 AEMD_Sclr_Gn_MCPA_P 511 "SNA";
VAL_ 504 MCPB_Inverter_Temp_P 255 "SNA";
VAL_ 504 MCPB_PIM_DC_Side_Busbar_Temp_P 255 "SNA";
VAL_ 504 MCPB_Rotor_Temperature_P 255 "SNA";
VAL_ 504 MCPB_Service_Lamp_Request_P 0 "False" 1 "True";
VAL_ 504 CLrDiagInfo_MCPB_P 0 "False" 1 "True";
VAL_ 504 MCPB_Control_Board_Temperature_P 255 "SNA";
VAL_ 294 MCPB_AC_Isolation_Status_P 0 "Not_Performed" 1 "Invalid" 2 "Fail" 3 "Pass";
VAL_ 294 MCPB_Temp_P 255 "SNA";
VAL_ 503 MCPA_Inverter_Temp_P 255 "SNA";
VAL_ 503 MCPA_PIM_DC_Side_Busbar_Temp_P 255 "SNA";
VAL_ 503 MCPA_Rotor_Temperature_P 255 "SNA";
VAL_ 503 MCPA_Service_Lamp_Request_P 0 "False" 1 "True";
VAL_ 503 CLrDiagInfo_MCPA_P 0 "False" 1 "True";
VAL_ 503 MCPA_Control_Board_Temperature_P 255 "SNA";
VAL_ 293 MCPA_Temp_P 255 "SNA";
VAL_ 293 MCPA_AC_Isolation_Status_P 0 "Not_Performed" 1 "Invalid" 2 "Fail" 3 "Pass";
VAL_ 220 VIN_MSG_OBD 0 "VIN_LO" 1 "VIN_MID" 2 "VIN_HI" 3 "SNA";
VAL_ 220 VehicleSpeedVSOSig_OBD 8191 "SNA";
VAL_ 220 OperationalModeSts_OBD 0 "Initialization" 1 "Ignition_Off_WithoutKey" 2 "Ignition_Off" 3 "Ignition_Acc" 4 "Ignition_On" 5 "Ignition_Pre_Start" 6 "Ignition_Start" 7 "Ignition_Cranking" 8 "Ignition_On_EngOn" 9 "Ignition_Pre_Acc" 10 "Ignition_Pre_Off" 11 "Automatic_Cranking" 12 "Automatic_Stop" 13 "Key_Authenticated" 14 "Not_Used" 15 "SNA";
VAL_ 220 EngineSpeedFailSts_W_OBD 0 "Fail_not_present" 1 "Fail_present";
VAL_ 220 EngineSpeed_W_OBD 16383 "SNA";
VAL_ 220 CmdIgnSts_OBD 0 "Initialization" 1 "IGN_LK" 3 "ACC" 4 "RUN" 5 "START" 7 "SNA";
VAL_ 200 TotalAxle_Rq_BSM_PT 65535 "SNA";
VAL_ 200 TotalAxle_Min_Rq_BSM_PT 0 "Not_Active" 1 "Active";
VAL_ 200 TotalAxle_Max_Rq_BSM_PT 0 "Not_Active" 1 "Active";
VAL_ 200 Total_AxleTorque_Static_PT 65535 "SNA";
VAL_ 200 RHFWheelSpeed_PT 8191 "SNA";
VAL_ 200 RHF_WheelSensorFailSts_PT 0 "Fail_Not_Present" 1 "Fail_Present";
VAL_ 200 LHFWheelSpeed_PT 8191 "SNA";
VAL_ 200 LHF_WheelSensorFailSts_PT 0 "Fail_Not_Present" 1 "Fail_Present";
VAL_ 200 Ft_RrCouplingTrq_Desired_PT 255 "SNA";
VAL_ 200 Ft_RrCouplingTrq_Actual_PT 255 "SNA";
VAL_ 200 ESCActive_PT 0 "Not_Active" 1 "Active";
VAL_ 200 Axle_TorqueStatic_D_TTC_PT 65535 "SNA";
VAL_ 200 Axle_TorqueStatic_D_TTC_ESC_PT 65535 "SNA";
VAL_ 200 AWDSysStat_PT 0 "SH_IPG" 1 "4LO" 2 "4HI" 3 "2WD" 4 "NEUTRAL" 5 "SYNC_IPG" 6 "4WDLock" 7 "SNA";
VAL_ 200 AtmosphericPressureFailSts_PT 0 "Fail_Not_Present" 1 "Fail_Present";
VAL_ 200 AtmosphericPressure_W_PT 255 "SNA";
VAL_ 214 Boost_Torque_Margin_MCPB 1023 "SNA";
VAL_ 214 Boost_Torque_Margin_MCPA 1023 "SNA";
SIG_GROUP_ 200 PT_SYSTEM_FD_4_Pkt 1 : TotalAxle_Rq_BSM_PT TotalAxle_Min_Rq_BSM_PT TotalAxle_Max_Rq_BSM_PT Total_AxleTorque_Static_PT RHFWheelSpeed_PT RHF_WheelSensorFailSts_PT LHFWheelSpeed_PT LHF_WheelSensorFailSts_PT Ft_RrCouplingTrq_Desired_PT Ft_RrCouplingTrq_Actual_PT ESCActive_PT Axle_TorqueStatic_D_TTC_PT Axle_TorqueStatic_D_TTC_ESC_PT AWDSysStat_PT AtmosphericPressureFailSts_PT AtmosphericPressure_W_PT MessageCounter_PT_SYSTEM_FD_4 CRC_PT_SYSTEM_FD_4;
SIG_GROUP_ 214 INVTARGET1_2_Pkt 1 : UDCMin_Unlim_MCPB_2 UDCMin_Unlim_MCPA_2 UDCMax_Unlim_MCPB_2 UDCMax_Unlim_MCPA_2 TqGrdtLim_MCPB_2 TqGrdtLim_MCPA_2 TorqueCommand_MCPB_2 TorqueCommand_MCPA_2 TargetMotorRPM_MCPB_2 TargetMotorRPM_MCPA_2 SpdGrdtLim_MCPB_2 SpdGrdtLim_MCPA_2 Mtr_6SO_Request_MCPB_2 Mtr_6SO_Request_MCPA_2 ModeCommand_MCPB_2 ModeCommand_MCPA_2 MinTorque_Limit_MCPB_2 MinTorque_Limit_MCPA_2 MessageCounter_INVTARGET1_2 MaxTorque_Limit_MCPB_2 MaxTorque_Limit_MCPA_2 MAC_INVTARGET1_2 LgsDiagCldStrtCndMet_MCPB_2 LgsDiagCldStrtCndFltPr_MCPB_2 HVBatVlt_V_2 EVCU_END_Request_Flag_2 CRC_INVTARGET1_2 Cntr_INVTARGET1_2 AEMD_MinOffset_MCPB_2 AEMD_MinOffset_MCPA_2 AEMD_MaxOffset_MCPB_2 AEMD_Cutoff_FreqLow_MCPB_2 AEMD_Cutoff_FreqLow_MCPA_2 AEMD_Cutoff_FreqHigh_MCPB_2 AEMD_Cutoff_FreqHigh_MCPA_2 AEMD_Sclr_Gn_MCPB_2 AEMD_Sclr_Gn_MCPA_2 AEMD_Torque_BoostVolt_Margin Boost_Torque_Margin_MCPB Boost_Torque_Margin_MCPA;
SIG_GROUP_ 297 INVTARGET_PROPULSION2_Pkt 1 : UDCMin_Unlim_MCPB_P UDCMin_Unlim_MCPA_P UDCMax_Unlim_MCPB_P UDCMax_Unlim_MCPA_P TqGrdtLim_MCPB_P TqGrdtLim_MCPA_P SpdGrdtLim_MCPB_P SpdGrdtLim_MCPA_P Pwr_Electr_Loop_FlwRate_MCPB_P Pwr_Electr_Loop_FlwRate_MCPA_P MC_INVTARGET_PROPULSION2 EVCU_MotorB_Speed EVCU_MotorA_Speed CRC_INVTARGET_PROPULSION2;
SIG_GROUP_ 296 INVTARGET_PROPULSION1_Pkt 1 : VehicleSpeedVSOSig_P TorqueCommand_MCPB_P TorqueCommand_MCPA_P TargetMotorRPM_MCPB_P TargetMotorRPM_MCPA_P ShiftLeverPosition_P ParkCmd_PT_P Mtr_6SO_Request_MCPB_P Mtr_6SO_Request_MCPA_P ModeCommand_MCPB_P ModeCommand_MCPA_P MC_INVTARGET_PROPULSION1 CRC_INVTARGET_PROPULSION1 CmdIgnSts_P BPCM_HV_TractionBusVoltage_P BPCM_HV_Trac_Main_Contac_Sts_P AEMD_MinOffset_MCPB_P AEMD_MinOffset_MCPA_P AEMD_MaxOffset_MCPB_P AEMD_MaxOffset_MCPA_P AEMD_Cutoff_FreqLow_MCPB_P AEMD_Cutoff_FreqLow_MCPA_P AEMD_Cutoff_FreqHigh_MCPB_P AEMD_Cutoff_FreqHigh_MCPA_P AEMD_Sclr_Gn_MCPB_P AEMD_Sclr_Gn_MCPA_P;
SIG_GROUP_ 294 MCPB_PROPULSION_Pkt 1 : PlockFailSts_P Plock_PosSensor_P Plock_MotorPosSts_P Plock_fdbk_sts_P MPR_PosSensor_P MCPB_Torque_Achieved_V_P MCPB_Torque_Achieved_P MCPB_TorqAchieved_AEMD_V_P MCPB_TorqAchieved_AEMD_P MCPB_SPT_Stat_P MCPB_Spd_Lim_P MCPB_RPM_V_P MCPB_RPM_P MCPB_MtrMinCpbltyTrq_P MCPB_MtrMaxCpbltyTrq_P MCPB_MtrIndex_P MCPB_MinTorq_P MCPB_MaxTorq_P MCPB_Invrtr_State_P MCPB_InterlockSts_P MCPB_HV_CnctrOpn_Req_P MCPB_Dschrge_Status_P MCPB_DeratingFactor_P MCPB_CpbltySpdDivVolt_P MCPB_AccelRawV_P MCPB_6SO_Status_P MCPB_3PS_Pos_P MCPB_AccelRaw_P MC_MCPB_PROPULSION CRC_MCPB_PROPULSION MCPB_AC_Isolation_Status_P MCPB_Temp_P;
SIG_GROUP_ 293 MCPA_PROPULSION_Pkt 1 : MCPA_Torque_Achieved_V_P MCPA_Torque_Achieved_P MCPA_TorqAchieved_AEMD_V_P MCPA_TorqAchieved_AEMD_P MCPA_SPT_Stat_P MCPA_Spd_Lim_P MCPA_RPM_V_P MCPA_RPM_P MCPA_MtrMinCpbltyTrq_P MCPA_MtrMaxCpbltyTrq_P MCPA_MtrIndex_P MCPA_MinTorq_P MCPA_MaxTorq_P MCPA_Invrtr_State_P MCPA_InterlockSts_P MCPA_HV_CnctrOpn_Req_P MCPA_Dschrge_Status_P MCPA_DeratingFactor_P MCPA_CpbltySpdDivVolt_P MCPA_AccelRawV_P MCPA_6SO_Status_P MCPA_3PS_Pos_P MCPA_AccelRaw_P MC_MCPA_PROPULSION CRC_MCPA_PROPULSION MCPA_Temp_P MCPA_AC_Isolation_Status_P;
